VERSION ""

NS_ :

BS_:

BU_:

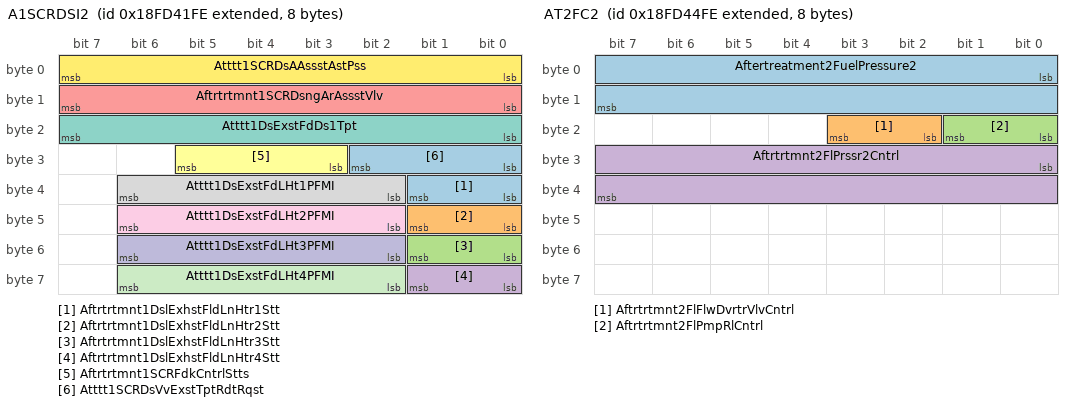
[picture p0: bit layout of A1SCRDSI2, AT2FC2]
BO_ 2566734334 A1SCRDSI2: 8 Vector__XXX
 SG_ Aftrtrtmnt1DslExhstFldLnHtr1Stt : 32|2@1+ (1,0) [0|3] "" Vector__XXX
 SG_ Aftrtrtmnt1DslExhstFldLnHtr2Stt : 40|2@1+ (1,0) [0|3] "" Vector__XXX
 SG_ Aftrtrtmnt1DslExhstFldLnHtr3Stt : 48|2@1+ (1,0) [0|3] "" Vector__XXX
 SG_ Aftrtrtmnt1DslExhstFldLnHtr4Stt : 56|2@1+ (1,0) [0|3] "" Vector__XXX
 SG_ Aftrtrtmnt1SCRDsngArAssstVlv : 8|8@1+ (0.4,0) [0|100] "%" Vector__XXX
 SG_ Aftrtrtmnt1SCRFdkCntrlStts : 27|3@1+ (1,0) [0|7] "" Vector__XXX
 SG_ Atttt1DsExstFdDs1Tpt : 16|8@1+ (1,-40) [-40|210] "degC" Vector__XXX
 SG_ Atttt1DsExstFdLHt1PFMI : 34|5@1+ (1,0) [0|31] "binary" Vector__XXX
 SG_ Atttt1DsExstFdLHt2PFMI : 42|5@1+ (1,0) [0|31] "binary" Vector__XXX
 SG_ Atttt1DsExstFdLHt3PFMI : 50|5@1+ (1,0) [0|31] "binary" Vector__XXX
 SG_ Atttt1DsExstFdLHt4PFMI : 58|5@1+ (1,0) [0|31] "binary" Vector__XXX
 SG_ Atttt1SCRDsAAssstAstPss : 0|8@1+ (8,0) [0|2000] "kPa" Vector__XXX
 SG_ Atttt1SCRDsVvExstTptRdtRqst : 24|3@1+ (1,0) [0|7] "" Vector__XXX

BO_ 2566735102 AT2FC2: 8 Vector__XXX
 SG_ Aftertreatment2FuelPressure2 : 0|16@1+ (0.1,0) [0|6425.5] "kPa" Vector__XXX
 SG_ Aftrtrtmnt2FlFlwDvrtrVlvCntrl : 18|2@1+ (1,0) [0|3] "" Vector__XXX
 SG_ Aftrtrtmnt2FlPmpRlCntrl : 16|2@1+ (1,0) [0|3] "" Vector__XXX
 SG_ Aftrtrtmnt2FlPrssr2Cntrl : 24|16@1+ (0.0025,0) [0|160.6375] "%" Vector__XXX

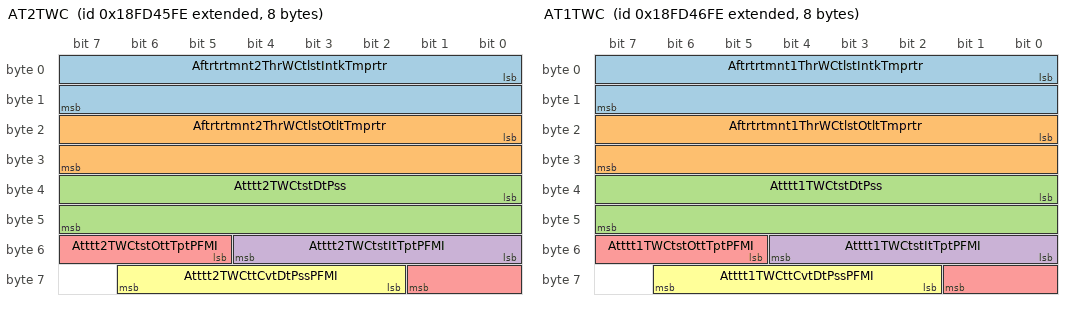
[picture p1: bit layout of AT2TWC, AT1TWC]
BO_ 2566735358 AT2TWC: 8 Vector__XXX
 SG_ Aftrtrtmnt2ThrWCtlstIntkTmprtr : 0|16@1+ (0.03125,-273) [-273|1734.96875] "degC" Vector__XXX
 SG_ Aftrtrtmnt2ThrWCtlstOtltTmprtr : 16|16@1+ (0.03125,-273) [-273|1734.96875] "degC" Vector__XXX
 SG_ Atttt2TWCtstDtPss : 32|16@1+ (0.1,0) [0|6425.5] "kPa" Vector__XXX
 SG_ Atttt2TWCtstItTptPFMI : 48|5@1+ (1,0) [0|31] "binary" Vector__XXX
 SG_ Atttt2TWCtstOttTptPFMI : 53|5@1+ (1,0) [0|31] "binary" Vector__XXX
 SG_ Atttt2TWCttCvtDtPssPFMI : 58|5@1+ (1,0) [0|31] "binary" Vector__XXX

BO_ 2566735614 AT1TWC: 8 Vector__XXX
 SG_ Aftrtrtmnt1ThrWCtlstIntkTmprtr : 0|16@1+ (0.03125,-273) [-273|1734.96875] "degC" Vector__XXX
 SG_ Aftrtrtmnt1ThrWCtlstOtltTmprtr : 16|16@1+ (0.03125,-273) [-273|1734.96875] "degC" Vector__XXX
 SG_ Atttt1TWCtstDtPss : 32|16@1+ (0.1,0) [0|6425.5] "kPa" Vector__XXX
 SG_ Atttt1TWCtstItTptPFMI : 48|5@1+ (1,0) [0|31] "binary" Vector__XXX
 SG_ Atttt1TWCtstOttTptPFMI : 53|5@1+ (1,0) [0|31] "binary" Vector__XXX
 SG_ Atttt1TWCttCvtDtPssPFMI : 58|5@1+ (1,0) [0|31] "binary" Vector__XXX

BO_ 2566736126 O2FT2: 8 Vector__XXX
 SG_ EngnExhstBnk2O2SnsrClsdLpOprtn : 32|4@1+ (1,0) [0|15] "" Vector__XXX
 SG_ LongtermFuelTrimBank2 : 0|16@1+ (0.1,-100) [-100|100] "%" Vector__XXX
 SG_ ShorttermFuelTrimBank2 : 16|16@1+ (0.1,-100) [-100|100] "%" Vector__XXX

BO_ 2566736382 O2FT1: 8 Vector__XXX
 SG_ EngnExhstBnk1O2SnsrClsdLpOprtn : 32|4@1+ (1,0) [0|15] "" Vector__XXX
 SG_ LongtermFuelTrimBank1 : 0|16@1+ (0.1,-100) [-100|100] "%" Vector__XXX
 SG_ ShorttermFuelTrimBank1 : 16|16@1+ (0.1,-100) [-100|100] "%" Vector__XXX

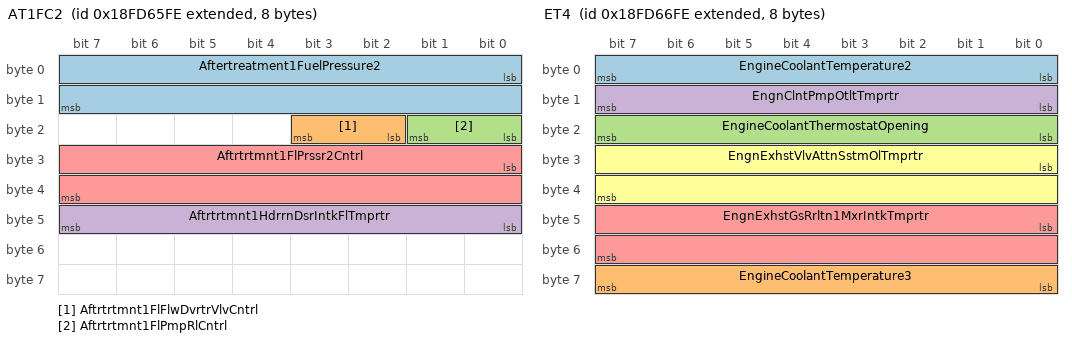
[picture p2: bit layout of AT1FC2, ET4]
BO_ 2566743550 AT1FC2: 8 Vector__XXX
 SG_ Aftertreatment1FuelPressure2 : 0|16@1+ (0.1,0) [0|6425.5] "kPa" Vector__XXX
 SG_ Aftrtrtmnt1FlFlwDvrtrVlvCntrl : 18|2@1+ (1,0) [0|3] "" Vector__XXX
 SG_ Aftrtrtmnt1FlPmpRlCntrl : 16|2@1+ (1,0) [0|3] "" Vector__XXX
 SG_ Aftrtrtmnt1HdrrnDsrIntkFlTmprtr : 40|8@1+ (1,-40) [-40|210] "degC" Vector__XXX
 SG_ Aftrtrtmnt1FlPrssr2Cntrl : 24|16@1+ (0.0025,0) [0|160.6375] "%" Vector__XXX

BO_ 2566743806 ET4: 8 Vector__XXX
 SG_ EngineCoolantTemperature2 : 0|8@1+ (1,-40) [-40|210] "degC" Vector__XXX
 SG_ EngineCoolantTemperature3 : 56|8@1+ (1,-40) [-40|210] "degC" Vector__XXX
 SG_ EngineCoolantThermostatOpening : 16|8@1+ (0.4,0) [0|100] "%" Vector__XXX
 SG_ EngnClntPmpOtltTmprtr : 8|8@1+ (1,-40) [-40|210] "degC" Vector__XXX
 SG_ EngnExhstGsRrltn1MxrIntkTmprtr : 40|16@1+ (0.03125,-273) [-273|1734.96875] "degC" Vector__XXX
 SG_ EngnExhstVlvAttnSstmOlTmprtr : 24|16@1+ (0.03125,-273) [-273|1734.96875] "degC" Vector__XXX

BO_ 2566744062 ZNVW: 8 Vector__XXX
 SG_ ZeroNetVehicleWeightChange : 0|2@1+ (1,0) [0|3] "" Vector__XXX

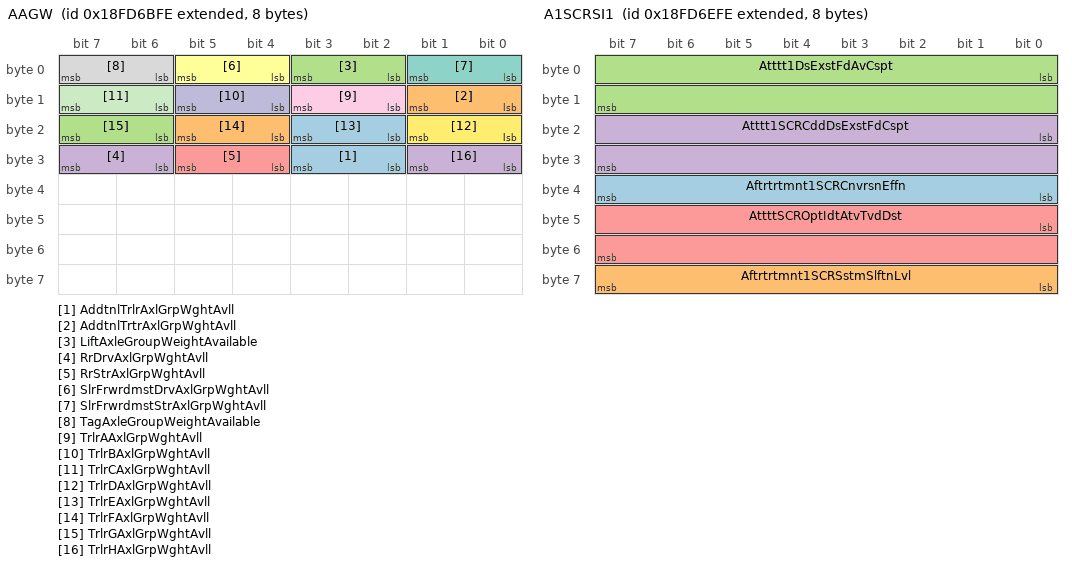
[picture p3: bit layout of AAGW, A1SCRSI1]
BO_ 2566745086 AAGW: 8 Vector__XXX
 SG_ AddtnlTrlrAxlGrpWghtAvll : 26|2@1+ (1,0) [0|3] "" Vector__XXX
 SG_ AddtnlTrtrAxlGrpWghtAvll : 8|2@1+ (1,0) [0|3] "" Vector__XXX
 SG_ LiftAxleGroupWeightAvailable : 2|2@1+ (1,0) [0|3] "" Vector__XXX
 SG_ RrDrvAxlGrpWghtAvll : 30|2@1+ (1,0) [0|3] "" Vector__XXX
 SG_ RrStrAxlGrpWghtAvll : 28|2@1+ (1,0) [0|3] "" Vector__XXX
 SG_ SlrFrwrdmstDrvAxlGrpWghtAvll : 4|2@1+ (1,0) [0|3] "" Vector__XXX
 SG_ SlrFrwrdmstStrAxlGrpWghtAvll : 0|2@1+ (1,0) [0|3] "" Vector__XXX
 SG_ TagAxleGroupWeightAvailable : 6|2@1+ (1,0) [0|3] "" Vector__XXX
 SG_ TrlrAAxlGrpWghtAvll : 10|2@1+ (1,0) [0|3] "" Vector__XXX
 SG_ TrlrBAxlGrpWghtAvll : 12|2@1+ (1,0) [0|3] "" Vector__XXX
 SG_ TrlrCAxlGrpWghtAvll : 14|2@1+ (1,0) [0|3] "" Vector__XXX
 SG_ TrlrDAxlGrpWghtAvll : 16|2@1+ (1,0) [0|3] "" Vector__XXX
 SG_ TrlrEAxlGrpWghtAvll : 18|2@1+ (1,0) [0|3] "" Vector__XXX
 SG_ TrlrFAxlGrpWghtAvll : 20|2@1+ (1,0) [0|3] "" Vector__XXX
 SG_ TrlrGAxlGrpWghtAvll : 22|2@1+ (1,0) [0|3] "" Vector__XXX
 SG_ TrlrHAxlGrpWghtAvll : 24|2@1+ (1,0) [0|3] "" Vector__XXX

BO_ 2566745342 AT2AC2: 8 Vector__XXX
 SG_ Aftrtrtmnt2SndrArDffrntlPrssr : 0|16@1+ (0.0078125,-250) [-250|251.99] "kPa" Vector__XXX
 SG_ Aftrtrtmnt2SndrArMssFlwRt : 32|16@1+ (0.2,0) [0|12851] "kg/h" Vector__XXX
 SG_ Aftrtrtmnt2SndrArPrssr : 48|16@1+ (0.1,0) [0|6425.5] "kPa" Vector__XXX
 SG_ Aftrtrtmnt2SndrArTmprtr : 16|16@1+ (0.03125,-273) [-273|1734.96875] "degC" Vector__XXX

BO_ 2566745598 AT1AC2: 8 Vector__XXX
 SG_ Aftrtrtmnt1SndrArDffrntlPrssr : 0|16@1+ (0.0078125,-250) [-250|251.99] "kPa" Vector__XXX
 SG_ Aftrtrtmnt1SndrArMssFlwRt : 32|16@1+ (0.2,0) [0|12851] "kg/h" Vector__XXX
 SG_ Aftrtrtmnt1SndrArPrssr : 48|16@1+ (0.1,0) [0|6425.5] "kPa" Vector__XXX
 SG_ Aftrtrtmnt1SndrArTmprtr : 16|16@1+ (0.03125,-273) [-273|1734.96875] "degC" Vector__XXX

BO_ 2566745854 A1SCRSI1: 8 Vector__XXX
 SG_ Aftrtrtmnt1SCRCnvrsnEffn : 32|8@1+ (0.4,0) [0|100] "%" Vector__XXX
 SG_ Aftrtrtmnt1SCRSstmSlftnLvl : 56|8@1+ (1,0) [0|250] "%" Vector__XXX
 SG_ Atttt1DsExstFdAvCspt : 0|16@1+ (0.05,0) [0|3212.75] "l/h" Vector__XXX
 SG_ Atttt1SCRCddDsExstFdCspt : 16|16@1+ (0.05,0) [0|3212.75] "l/h" Vector__XXX
 SG_ AttttSCROptIdtAtvTvdDst : 40|16@1+ (1,0) [0|64255] "km" Vector__XXX

BO_ 2566746110 EEC8: 8 Vector__XXX
 SG_ EExstGsRt1CItAstPss : 32|16@1+ (0.5,0) [0|32127.5] "kPa" Vector__XXX
 SG_ EngnExhstGsRrltn1ClrEffn : 48|8@1+ (0.4,0) [0|100] "%" Vector__XXX
 SG_ EngnExhstGsRrltn1ClrIntkTmprtr : 16|16@1+ (0.03125,-273) [-273|1734.96875] "degC" Vector__XXX
 SG_ EngnExhstGsRrltn1Vlv2Cntrl : 0|16@1+ (0.0025,0) [0|160.6375] "%" Vector__XXX

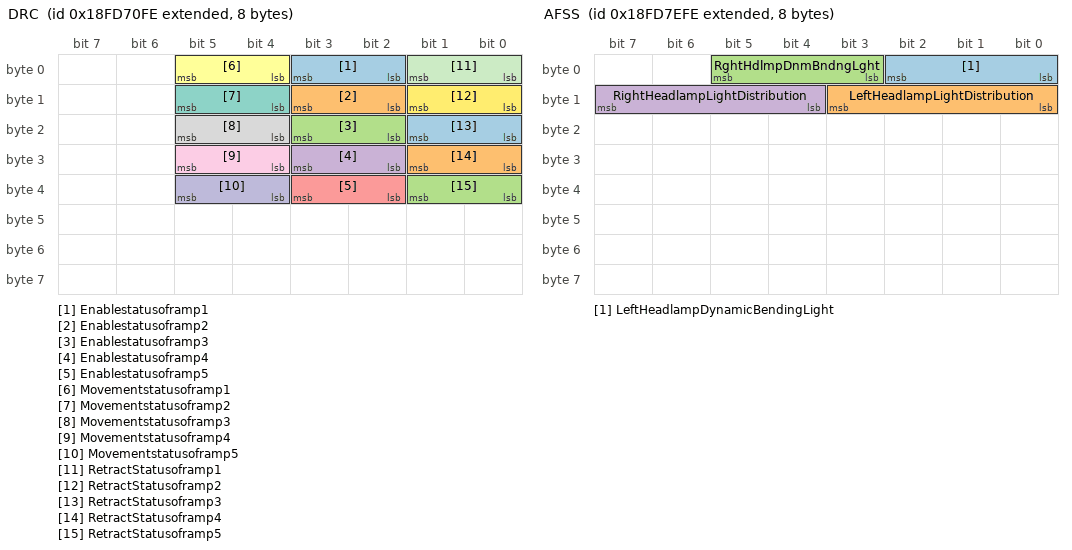
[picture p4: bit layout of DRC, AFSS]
BO_ 2566746366 DRC: 8 Vector__XXX
 SG_ Enablestatusoframp1 : 2|2@1+ (1,0) [0|3] "" Vector__XXX
 SG_ Enablestatusoframp2 : 10|2@1+ (1,0) [0|3] "" Vector__XXX
 SG_ Enablestatusoframp3 : 18|2@1+ (1,0) [0|3] "" Vector__XXX
 SG_ Enablestatusoframp4 : 26|2@1+ (1,0) [0|3] "" Vector__XXX
 SG_ Enablestatusoframp5 : 34|2@1+ (1,0) [0|3] "" Vector__XXX
 SG_ Movementstatusoframp1 : 4|2@1+ (1,0) [0|3] "" Vector__XXX
 SG_ Movementstatusoframp2 : 12|2@1+ (1,0) [0|3] "" Vector__XXX
 SG_ Movementstatusoframp3 : 20|2@1+ (1,0) [0|3] "" Vector__XXX
 SG_ Movementstatusoframp4 : 28|2@1+ (1,0) [0|3] "" Vector__XXX
 SG_ Movementstatusoframp5 : 36|2@1+ (1,0) [0|3] "" Vector__XXX
 SG_ RetractStatusoframp1 : 0|2@1+ (1,0) [0|3] "" Vector__XXX
 SG_ RetractStatusoframp2 : 8|2@1+ (1,0) [0|3] "" Vector__XXX
 SG_ RetractStatusoframp3 : 16|2@1+ (1,0) [0|3] "" Vector__XXX
 SG_ RetractStatusoframp4 : 24|2@1+ (1,0) [0|3] "" Vector__XXX
 SG_ RetractStatusoframp5 : 32|2@1+ (1,0) [0|3] "" Vector__XXX

BO_ 2566746622 BSA: 8 Vector__XXX
 SG_ TractorBrakeStrokeAxle1Left : 0|3@1+ (1,0) [0|7] "" Vector__XXX
 SG_ TractorBrakeStrokeAxle1Right : 3|3@1+ (1,0) [0|7] "" Vector__XXX
 SG_ TractorBrakeStrokeAxle2Left : 6|3@1+ (1,0) [0|7] "" Vector__XXX
 SG_ TractorBrakeStrokeAxle2Right : 9|3@1+ (1,0) [0|7] "" Vector__XXX
 SG_ TractorBrakeStrokeAxle3Left : 12|3@1+ (1,0) [0|7] "" Vector__XXX
 SG_ TractorBrakeStrokeAxle3Right : 15|3@1+ (1,0) [0|7] "" Vector__XXX
 SG_ TractorBrakeStrokeAxle4Left : 18|3@1+ (1,0) [0|7] "" Vector__XXX
 SG_ TractorBrakeStrokeAxle4Right : 21|3@1+ (1,0) [0|7] "" Vector__XXX
 SG_ TractorBrakeStrokeAxle5Left : 24|3@1+ (1,0) [0|7] "" Vector__XXX
 SG_ TractorBrakeStrokeAxle5Right : 27|3@1+ (1,0) [0|7] "" Vector__XXX
 SG_ TrailerBrakeStrokeAxle1Left : 30|3@1+ (1,0) [0|7] "" Vector__XXX
 SG_ TrailerBrakeStrokeAxle1Right : 33|3@1+ (1,0) [0|7] "" Vector__XXX
 SG_ TrailerBrakeStrokeAxle2Left : 36|3@1+ (1,0) [0|7] "" Vector__XXX
 SG_ TrailerBrakeStrokeAxle2Right : 39|3@1+ (1,0) [0|7] "" Vector__XXX
 SG_ TrailerBrakeStrokeAxle3Left : 42|3@1+ (1,0) [0|7] "" Vector__XXX
 SG_ TrailerBrakeStrokeAxle3Right : 45|3@1+ (1,0) [0|7] "" Vector__XXX
 SG_ TrailerBrakeStrokeAxle4Left : 48|3@1+ (1,0) [0|7] "" Vector__XXX
 SG_ TrailerBrakeStrokeAxle4Right : 51|3@1+ (1,0) [0|7] "" Vector__XXX
 SG_ TrailerBrakeStrokeAxle5Left : 54|3@1+ (1,0) [0|7] "" Vector__XXX
 SG_ TrailerBrakeStrokeAxle5Right : 57|3@1+ (1,0) [0|7] "" Vector__XXX

BO_ 2566746878 ESV6: 8 Vector__XXX
 SG_ EngineSparkPlug21 : 0|16@1+ (1,0) [0|64255] "V" Vector__XXX
 SG_ EngineSparkPlug22 : 16|16@1+ (1,0) [0|64255] "V" Vector__XXX
 SG_ EngineSparkPlug23 : 32|16@1+ (1,0) [0|64255] "V" Vector__XXX
 SG_ EngineSparkPlug24 : 48|16@1+ (1,0) [0|64255] "V" Vector__XXX

BO_ 2566747134 ESV5: 8 Vector__XXX
 SG_ EngineSparkPlug17 : 0|16@1+ (1,0) [0|64255] "V" Vector__XXX
 SG_ EngineSparkPlug18 : 16|16@1+ (1,0) [0|64255] "V" Vector__XXX
 SG_ EngineSparkPlug19 : 32|16@1+ (1,0) [0|64255] "V" Vector__XXX
 SG_ EngineSparkPlug20 : 48|16@1+ (1,0) [0|64255] "V" Vector__XXX

BO_ 2566747390 ESV4: 8 Vector__XXX
 SG_ EngineSparkPlug13 : 0|16@1+ (1,0) [0|64255] "V" Vector__XXX
 SG_ EngineSparkPlug14 : 16|16@1+ (1,0) [0|64255] "V" Vector__XXX
 SG_ EngineSparkPlug15 : 32|16@1+ (1,0) [0|64255] "V" Vector__XXX
 SG_ EngineSparkPlug16 : 48|16@1+ (1,0) [0|64255] "V" Vector__XXX

BO_ 2566747646 ESV3: 8 Vector__XXX
 SG_ EngineSparkPlug10 : 16|16@1+ (1,0) [0|64255] "V" Vector__XXX
 SG_ EngineSparkPlug11 : 32|16@1+ (1,0) [0|64255] "V" Vector__XXX
 SG_ EngineSparkPlug12 : 48|16@1+ (1,0) [0|64255] "V" Vector__XXX
 SG_ EngineSparkPlug9 : 0|16@1+ (1,0) [0|64255] "V" Vector__XXX

BO_ 2566747902 ESV2: 8 Vector__XXX
 SG_ EngineSparkPlug5 : 0|16@1+ (1,0) [0|64255] "V" Vector__XXX
 SG_ EngineSparkPlug6 : 16|16@1+ (1,0) [0|64255] "V" Vector__XXX
 SG_ EngineSparkPlug7 : 32|16@1+ (1,0) [0|64255] "V" Vector__XXX
 SG_ EngineSparkPlug8 : 48|16@1+ (1,0) [0|64255] "V" Vector__XXX

BO_ 2566748158 ESV1: 8 Vector__XXX
 SG_ EngineSparkPlug1 : 0|16@1+ (1,0) [0|64255] "V" Vector__XXX
 SG_ EngineSparkPlug2 : 16|16@1+ (1,0) [0|64255] "V" Vector__XXX
 SG_ EngineSparkPlug3 : 32|16@1+ (1,0) [0|64255] "V" Vector__XXX
 SG_ EngineSparkPlug4 : 48|16@1+ (1,0) [0|64255] "V" Vector__XXX

BO_ 2566748414 AT2TI: 32 Vector__XXX
 SG_ Aftrtrtmnt2DslPrtltFltrTrpFlUsd : 0|32@1+ (0.5,0) [0|2105540607.5] "l" Vector__XXX
 SG_ Atttt2DsPttFtTpAtvRtT : 32|32@1+ (1,0) [0|4.21108E+09] "s" Vector__XXX
 SG_ Atttt2DsPttFtTpDsdT : 64|32@1+ (1,0) [0|4.21108E+09] "s" Vector__XXX
 SG_ Atttt2DsPttFtTpNAtvRtItRqsts : 192|32@1+ (1,0) [0|4.21108E+09] "count" Vector__XXX
 SG_ Atttt2DsPttFtTpNAtvRtMRqsts : 224|32@1+ (1,0) [0|4.21108E+09] "count" Vector__XXX
 SG_ Atttt2DsPttFtTpNAtvRts : 96|32@1+ (1,0) [0|4.21108E+09] "count" Vector__XXX
 SG_ Atttt2DsPttFtTpNPssvRts : 160|32@1+ (1,0) [0|4.21108E+09] "count" Vector__XXX
 SG_ Atttt2DsPttFtTpPssvRtT : 128|32@1+ (1,0) [0|4.21108E+09] "s" Vector__XXX

BO_ 2566748670 AT1TI: 32 Vector__XXX
 SG_ Aftrtrtmnt1DslPrtltFltrTrpFlUsd : 0|32@1+ (0.5,0) [0|2105540607.5] "l" Vector__XXX
 SG_ Atttt1DsPttFtTpAtvRtT : 32|32@1+ (1,0) [0|4.21108E+09] "s" Vector__XXX
 SG_ Atttt1DsPttFtTpDsdT : 64|32@1+ (1,0) [0|4.21108E+09] "s" Vector__XXX
 SG_ Atttt1DsPttFtTpNAtvRtItRqsts : 192|32@1+ (1,0) [0|4.21108E+09] "count" Vector__XXX
 SG_ Atttt1DsPttFtTpNAtvRtMRqsts : 224|32@1+ (1,0) [0|4.21108E+09] "count" Vector__XXX
 SG_ Atttt1DsPttFtTpNAtvRts : 96|32@1+ (1,0) [0|4.21108E+09] "count" Vector__XXX
 SG_ Atttt1DsPttFtTpNPssvRts : 160|32@1+ (1,0) [0|4.21108E+09] "count" Vector__XXX
 SG_ Atttt1DsPttFtTpPssvRtT : 128|32@1+ (1,0) [0|4.21108E+09] "s" Vector__XXX

BO_ 2566748926 AT2S1: 8 Vector__XXX
 SG_ Aftrtrtmnt2DslPrtltFltrStLdPrnt : 0|8@1+ (1,0) [0|250] "%" Vector__XXX
 SG_ Atttt2DsPttFtAsLdPt : 8|8@1+ (1,0) [0|250] "%" Vector__XXX
 SG_ Atttt2DsPttFtStLdRtTsd : 48|16@1+ (0.0025,0) [0|160.6375] "%" Vector__XXX
 SG_ Atttt2DsPttFtTSLstAtvRt : 16|32@1+ (1,0) [0|4.21108E+09] "s" Vector__XXX

BO_ 2566749182 AT1S1: 8 Vector__XXX
 SG_ Aftrtrtmnt1DslPrtltFltrStLdPrnt : 0|8@1+ (1,0) [0|250] "%" Vector__XXX
 SG_ Atttt1DsPttFtAsLdPt : 8|8@1+ (1,0) [0|250] "%" Vector__XXX
 SG_ Atttt1DsPttFtStLdRtTsd : 48|16@1+ (0.0025,0) [0|160.6375] "%" Vector__XXX
 SG_ Atttt1DsPttFtTSLstAtvRt : 16|32@1+ (1,0) [0|4.21108E+09] "s" Vector__XXX

BO_ 2566749438 DPFC1: 8 Vector__XXX
 SG_ AftrtrtmntDslPrtltFltrStts : 12|3@1+ (1,0) [0|7] "" Vector__XXX
 SG_ Atttt1DsPttFtCdtsNtMtAtvRt : 60|2@1+ (1,0) [0|3] "" Vector__XXX
 SG_ AttttDsPttFtAtvRtStts : 10|2@1+ (1,0) [0|3] "" Vector__XXX
 SG_ AttttDsPttFtPssvRtStts : 8|2@1+ (1,0) [0|3] "" Vector__XXX
 SG_ DslPrtltFltrAtvRgnrtnAvlltStts : 3|2@1+ (1,0) [0|3] "" Vector__XXX
 SG_ DslPrtltFltrAtvRgnrtnFrdStts : 53|3@1+ (1,0) [0|7] "" Vector__XXX
 SG_ DslPrtltFltrAtvRgnrtnInhtdStts : 16|2@1+ (1,0) [0|3] "" Vector__XXX
 SG_ DslPrtltFltrLmpCmmnd : 0|3@1+ (1,0) [0|7] "" Vector__XXX
 SG_ DsPttFtAttAtvRtIttCt : 48|2@1+ (1,0) [0|3] "" Vector__XXX
 SG_ DsPttFtAtvRtItdDtAtPdOId : 26|2@1+ (1,0) [0|3] "" Vector__XXX
 SG_ DsPttFtAtvRtItdDtCtDsd : 20|2@1+ (1,0) [0|3] "" Vector__XXX
 SG_ DsPttFtAtvRtItdDtENtWdUp : 44|2@1+ (1,0) [0|3] "" Vector__XXX
 SG_ DsPttFtAtvRtItdDtItSwt : 18|2@1+ (1,0) [0|3] "" Vector__XXX
 SG_ DsPttFtAtvRtItdDtLwExstPss : 58|2@1+ (1,0) [0|3] "" Vector__XXX
 SG_ DsPttFtAtvRtItdDtLwExstTpt : 34|2@1+ (1,0) [0|3] "" Vector__XXX
 SG_ DsPttFtAtvRtItdDtOtNt : 28|2@1+ (1,0) [0|3] "" Vector__XXX
 SG_ DsPttFtAtvRtItdDtPBNtSt : 32|2@1+ (1,0) [0|3] "" Vector__XXX
 SG_ DsPttFtAtvRtItdDtPTOAtv : 24|2@1+ (1,0) [0|3] "" Vector__XXX
 SG_ DsPttFtAtvRtItdDtPtSstLt : 42|2@1+ (1,0) [0|3] "" Vector__XXX
 SG_ DsPttFtAtvRtItdDtSstFtAtv : 36|2@1+ (1,0) [0|3] "" Vector__XXX
 SG_ DsPttFtAtvRtItdDtSstTt : 38|2@1+ (1,0) [0|3] "" Vector__XXX
 SG_ DsPttFtAtvRtItdDtSvBAtv : 22|2@1+ (1,0) [0|3] "" Vector__XXX
 SG_ DsPttFtAtvRtItdDtTpSstLt : 40|2@1+ (1,0) [0|3] "" Vector__XXX
 SG_ DsPttFtAtvRtItdDtVSpdAvAwdSpd : 30|2@1+ (1,0) [0|3] "" Vector__XXX
 SG_ DsPttFtAtvRtItdDtVSpdBwAwdSpd : 46|2@1+ (1,0) [0|3] "" Vector__XXX
 SG_ ExhstSstmHghTmprtrLmpCmmnd : 50|3@1+ (1,0) [0|7] "" Vector__XXX
 SG_ HydrocarbonDoserPurgingEnable : 56|2@1+ (1,0) [0|3] "" Vector__XXX
 SG_ DsPttFtAtvRtItdDtTs : 62|2@1+ (1,0) [0|3] "" Vector__XXX

BO_ 2566749950 AFSS: 8 Vector__XXX
 SG_ LeftHeadlampDynamicBendingLight : 0|3@1+ (1,0) [0|7] "" Vector__XXX
 SG_ LeftHeadlampLightDistribution : 8|4@1+ (1,0) [0|15] "" Vector__XXX
 SG_ RghtHdlmpDnmBndngLght : 3|3@1+ (1,0) [0|7] "" Vector__XXX
 SG_ RightHeadlampLightDistribution : 12|4@1+ (1,0) [0|15] "" Vector__XXX

BO_ 2566750206 EC2: 8 Vector__XXX
 SG_ EngnCnfgrtnIdntftn : 16|16@1+ (1,0) [0|64255] "ID" Vector__XXX
 SG_ MxmmCrnkAttmptsprStrtAttmpt : 0|8@1+ (1,0) [0|250] "count" Vector__XXX
 SG_ NmrfCmstnClsfrAvrgng : 8|8@1+ (1,0) [0|250] "count" Vector__XXX
 SG_ TrnsmssnIdlGvrnrFlngInhtSpprt : 32|2@1+ (1,0) [0|3] "" Vector__XXX

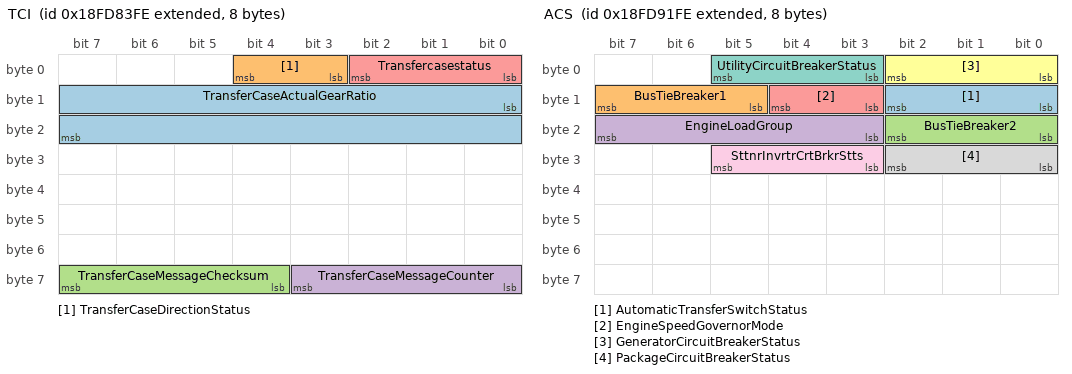
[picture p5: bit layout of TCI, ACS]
BO_ 2566751230 TCI: 8 Vector__XXX
 SG_ TransferCaseActualGearRatio : 8|16@1+ (0.01,0) [0|642.55] "" Vector__XXX
 SG_ TransferCaseDirectionStatus : 3|2@1+ (1,0) [0|3] "" Vector__XXX
 SG_ TransferCaseMessageChecksum : 60|4@1+ (1,0) [0|15] "count" Vector__XXX
 SG_ TransferCaseMessageCounter : 56|4@1+ (1,0) [0|15] "count" Vector__XXX
 SG_ Transfercasestatus : 0|3@1+ (1,0) [0|7] "" Vector__XXX

BO_ 2566751486 EFLP9: 8 Vector__XXX
 SG_ EngnIntkVlvAttnOlPrssrfrClndr17 : 0|16@1+ (0.1,0) [0|6425.5] "kPa" Vector__XXX
 SG_ EngnIntkVlvAttnOlPrssrfrClndr18 : 16|16@1+ (0.1,0) [0|6425.5] "kPa" Vector__XXX
 SG_ EngnIntkVlvAttnOlPrssrfrClndr19 : 32|16@1+ (0.1,0) [0|6425.5] "kPa" Vector__XXX
 SG_ EngnIntkVlvAttnOlPrssrfrClndr20 : 48|16@1+ (0.1,0) [0|6425.5] "kPa" Vector__XXX

BO_ 2566751742 EFLP8: 8 Vector__XXX
 SG_ EngnIntkVlvAttnOlPrssrfrClndr13 : 0|16@1+ (0.1,0) [0|6425.5] "kPa" Vector__XXX
 SG_ EngnIntkVlvAttnOlPrssrfrClndr14 : 16|16@1+ (0.1,0) [0|6425.5] "kPa" Vector__XXX
 SG_ EngnIntkVlvAttnOlPrssrfrClndr15 : 32|16@1+ (0.1,0) [0|6425.5] "kPa" Vector__XXX
 SG_ EngnIntkVlvAttnOlPrssrfrClndr16 : 48|16@1+ (0.1,0) [0|6425.5] "kPa" Vector__XXX

BO_ 2566751998 EFLP7: 8 Vector__XXX
 SG_ EngnIntkVlvAttnOlPrssrfrClndr10 : 16|16@1+ (0.1,0) [0|6425.5] "kPa" Vector__XXX
 SG_ EngnIntkVlvAttnOlPrssrfrClndr11 : 32|16@1+ (0.1,0) [0|6425.5] "kPa" Vector__XXX
 SG_ EngnIntkVlvAttnOlPrssrfrClndr12 : 48|16@1+ (0.1,0) [0|6425.5] "kPa" Vector__XXX
 SG_ EngnIntkVlvAttnOlPrssrfrClndr9 : 0|16@1+ (0.1,0) [0|6425.5] "kPa" Vector__XXX

BO_ 2566752254 EFLP6: 8 Vector__XXX
 SG_ EngnIntkVlvAttnOlPrssrfrClndr5 : 0|16@1+ (0.1,0) [0|6425.5] "kPa" Vector__XXX
 SG_ EngnIntkVlvAttnOlPrssrfrClndr6 : 16|16@1+ (0.1,0) [0|6425.5] "kPa" Vector__XXX
 SG_ EngnIntkVlvAttnOlPrssrfrClndr7 : 32|16@1+ (0.1,0) [0|6425.5] "kPa" Vector__XXX
 SG_ EngnIntkVlvAttnOlPrssrfrClndr8 : 48|16@1+ (0.1,0) [0|6425.5] "kPa" Vector__XXX

BO_ 2566752510 EFLP5: 8 Vector__XXX
 SG_ EngnIntkVlvAttnOlPrssrfrClndr1 : 0|16@1+ (0.1,0) [0|6425.5] "kPa" Vector__XXX
 SG_ EngnIntkVlvAttnOlPrssrfrClndr2 : 16|16@1+ (0.1,0) [0|6425.5] "kPa" Vector__XXX
 SG_ EngnIntkVlvAttnOlPrssrfrClndr3 : 32|16@1+ (0.1,0) [0|6425.5] "kPa" Vector__XXX
 SG_ EngnIntkVlvAttnOlPrssrfrClndr4 : 48|16@1+ (0.1,0) [0|6425.5] "kPa" Vector__XXX

BO_ 2566752766 VDS2: 8 Vector__XXX
 SG_ VehicleRoll : 0|16@1+ (0.0078125,-200) [-200|301.99] "deg" Vector__XXX

BO_ 2566753278 AT2GP: 8 Vector__XXX
 SG_ Atttt2DsPttFtItPss : 0|16@1+ (0.1,0) [0|6425.5] "kPa" Vector__XXX
 SG_ Atttt2DsPttFtOttPss : 16|16@1+ (0.1,0) [0|6425.5] "kPa" Vector__XXX

BO_ 2566753534 AT1GP: 8 Vector__XXX
 SG_ Atttt1DsPttFtItPss : 0|16@1+ (0.1,0) [0|6425.5] "kPa" Vector__XXX
 SG_ Atttt1DsPttFtOttPss : 16|16@1+ (0.1,0) [0|6425.5] "kPa" Vector__XXX

BO_ 2566753790 UTACER: 8 Vector__XXX
 SG_ UtilityTotalkVArHoursExport : 0|32@1+ (1,0) [0|4.21108E+09] "kVArh" Vector__XXX
 SG_ UtilityTotalkVArHoursImport : 32|32@1+ (1,0) [0|4.21108E+09] "kVArh" Vector__XXX

BO_ 2566754046 GTACER: 8 Vector__XXX
 SG_ GeneratorTotalkVArHoursExport : 0|32@1+ (1,0) [0|4.21108E+09] "kVArh" Vector__XXX
 SG_ GeneratorTotalkVArHoursImport : 32|32@1+ (1,0) [0|4.21108E+09] "kVArh" Vector__XXX

BO_ 2566754302 GTACPP: 8 Vector__XXX
 SG_ GeneratorTotalPercentkVA : 16|16@1+ (0.0078125,-251) [-251|250.99] "%" Vector__XXX
 SG_ GeneratorTotalPercentkVAr : 32|16@1+ (0.0078125,-251) [-251|250.99] "%" Vector__XXX
 SG_ GeneratorTotalPercentkW : 0|16@1+ (0.0078125,-251) [-251|250.99] "%" Vector__XXX

BO_ 2566754814 ACS: 8 Vector__XXX
 SG_ AutomaticTransferSwitchStatus : 8|3@1+ (1,0) [0|7] "" Vector__XXX
 SG_ BusTieBreaker1 : 13|3@1+ (1,0) [0|7] "" Vector__XXX
 SG_ BusTieBreaker2 : 16|3@1+ (1,0) [0|7] "" Vector__XXX
 SG_ EngineLoadGroup : 19|5@1+ (1,0) [0|31] "count" Vector__XXX
 SG_ EngineSpeedGovernorMode : 11|2@1+ (1,0) [0|3] "" Vector__XXX
 SG_ GeneratorCircuitBreakerStatus : 0|3@1+ (1,0) [0|7] "" Vector__XXX
 SG_ UtilityCircuitBreakerStatus : 3|3@1+ (1,0) [0|7] "" Vector__XXX
 SG_ PackageCircuitBreakerStatus : 24|3@1+ (1,0) [0|7] "" Vector__XXX
 SG_ SttnrInvrtrCrtBrkrStts : 27|3@1+ (1,0) [0|7] "" Vector__XXX

BO_ 2566755582 EEC7: 8 Vector__XXX
 SG_ EngnCrnksBrthrOlSprtrSpd : 32|16@1+ (1,0) [0|64255] "rpm" Vector__XXX
 SG_ EngnExhstGsRrltn1Vlv2Pstn : 16|16@1+ (0.0025,0) [0|160.6375] "%" Vector__XXX
 SG_ EngnExhstGsRrltn1VlvPstn : 0|16@1+ (0.0025,0) [0|160.6375] "%" Vector__XXX
 SG_ EngnIntkMnfldCmmnddPrssr : 48|16@1+ (0.125,0) [0|8031.875] "kPa" Vector__XXX

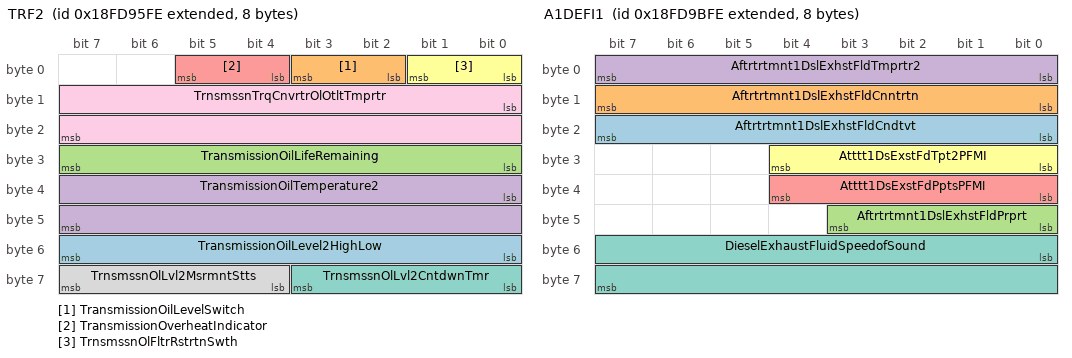
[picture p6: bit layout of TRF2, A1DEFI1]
BO_ 2566755838 TRF2: 8 Vector__XXX
 SG_ TransmissionOilLevel2HighLow : 48|8@1+ (0.5,-62.5) [-62.5|62.5] "l" Vector__XXX
 SG_ TransmissionOilLevelSwitch : 2|2@1+ (1,0) [0|3] "" Vector__XXX
 SG_ TransmissionOilLifeRemaining : 24|8@1+ (0.4,0) [0|100] "%" Vector__XXX
 SG_ TransmissionOilTemperature2 : 32|16@1+ (0.03125,-273) [-273|1734.96875] "degC" Vector__XXX
 SG_ TransmissionOverheatIndicator : 4|2@1+ (1,0) [0|3] "" Vector__XXX
 SG_ TrnsmssnOlFltrRstrtnSwth : 0|2@1+ (1,0) [0|3] "" Vector__XXX
 SG_ TrnsmssnOlLvl2CntdwnTmr : 56|4@1+ (1,0) [0|15] "" Vector__XXX
 SG_ TrnsmssnOlLvl2MsrmntStts : 60|4@1+ (1,0) [0|15] "" Vector__XXX
 SG_ TrnsmssnTrqCnvrtrOlOtltTmprtr : 8|16@1+ (0.03125,-273) [-273|1734.96875] "degC" Vector__XXX

BO_ 2566756094 LFI2: 8 Vector__XXX
 SG_ EngineFuelReturnFlowRate : 32|32@1+ (0.001,0) [0|4211081.215] "l/h" Vector__XXX
 SG_ EngineFuelSupplyFlowRate : 0|32@1+ (0.001,0) [0|4211081.215] "l/h" Vector__XXX

BO_ 2566756350 LFI3: 8 Vector__XXX
 SG_ EngineFuelReturnTemperature : 8|8@1+ (1,-40) [-40|210] "degC" Vector__XXX
 SG_ EngineFuelSupplyTemperature : 0|8@1+ (1,-40) [-40|210] "degC" Vector__XXX

BO_ 2566756606 AT1HI1: 40 Vector__XXX
 SG_ Aftertreatment1TotalFuelUsed : 0|32@1+ (0.5,0) [0|2105540607.5] "l" Vector__XXX
 SG_ Aftrtrtmnt1TtlDsldTm : 64|32@1+ (1,0) [0|4.21108E+09] "s" Vector__XXX
 SG_ Aftrtrtmnt1TtlNmrfAtvRgnrtns : 96|32@1+ (1,0) [0|4.21108E+09] "count" Vector__XXX
 SG_ Aftrtrtmnt1TtlRgnrtnTm : 32|32@1+ (1,0) [0|4.21108E+09] "s" Vector__XXX
 SG_ Atttt1DsPttFtAvDstBtwAtvRts : 288|32@1+ (0.125,0) [0|526385151.875] "km" Vector__XXX
 SG_ Atttt1DsPttFtAvTBtwAtvRts : 256|32@1+ (1,0) [0|4.21108E+09] "s" Vector__XXX
 SG_ Atttt1DsPttFtTtNAtvRtItRqsts : 192|32@1+ (1,0) [0|4.21108E+09] "count" Vector__XXX
 SG_ Atttt1DsPttFtTtNAtvRtMRqsts : 224|32@1+ (1,0) [0|4.21108E+09] "count" Vector__XXX
 SG_ Atttt1DsPttFtTtNPssvRts : 160|32@1+ (1,0) [0|4.21108E+09] "count" Vector__XXX
 SG_ Atttt1DsPttFtTtPssvRtT : 128|32@1+ (1,0) [0|4.21108E+09] "s" Vector__XXX

BO_ 2566756862 AT2HI1: 40 Vector__XXX
 SG_ Aftertreatment2TotalFuelUsed : 0|32@1+ (0.5,0) [0|2105540607.5] "l" Vector__XXX
 SG_ Aftrtrtmnt2TtlDsldTm : 64|32@1+ (1,0) [0|4.21108E+09] "s" Vector__XXX
 SG_ Aftrtrtmnt2TtlNmrfAtvRgnrtns : 96|32@1+ (1,0) [0|4.21108E+09] "count" Vector__XXX
 SG_ Aftrtrtmnt2TtlRgnrtnTm : 32|32@1+ (1,0) [0|4.21108E+09] "s" Vector__XXX
 SG_ Atttt2DsPttFtAvDstBtwAtvRts : 288|32@1+ (0.125,0) [0|526385151.875] "km" Vector__XXX
 SG_ Atttt2DsPttFtAvTBtwAtvRts : 256|32@1+ (1,0) [0|4.21108E+09] "s" Vector__XXX
 SG_ Atttt2DsPttFtTtNAtvRtItRqsts : 192|32@1+ (1,0) [0|4.21108E+09] "count" Vector__XXX
 SG_ Atttt2DsPttFtTtNAtvRtMRqsts : 224|32@1+ (1,0) [0|4.21108E+09] "count" Vector__XXX
 SG_ Atttt2DsPttFtTtNPssvRts : 160|32@1+ (1,0) [0|4.21108E+09] "count" Vector__XXX
 SG_ Atttt2DsPttFtTtPssvRtT : 128|32@1+ (1,0) [0|4.21108E+09] "s" Vector__XXX

BO_ 2566757374 A1DEFI1: 8 Vector__XXX
 SG_ Aftrtrtmnt1DslExhstFldCndtvt : 16|8@1+ (5,0) [0|1250] "µSiemens/mm" Vector__XXX
 SG_ Aftrtrtmnt1DslExhstFldCnntrtn : 8|8@1+ (0.25,0) [0|62.5] "%" Vector__XXX
 SG_ Aftrtrtmnt1DslExhstFldPrprt : 40|4@1+ (1,0) [0|15] "" Vector__XXX
 SG_ Aftrtrtmnt1DslExhstFldTmprtr2 : 0|8@1+ (1,-40) [-40|210] "degC" Vector__XXX
 SG_ Atttt1DsExstFdPptsPFMI : 32|5@1+ (1,0) [0|31] "binary" Vector__XXX
 SG_ Atttt1DsExstFdTpt2PFMI : 24|5@1+ (1,0) [0|31] "binary" Vector__XXX
 SG_ DieselExhaustFluidSpeedofSound : 48|16@1+ (0.1,0) [0|6425.5] "m/s" Vector__XXX

BO_ 2566757630 SEP2: 8 Vector__XXX
 SG_ Sensorsupplyvoltage5 : 0|16@1+ (0.05,0) [0|3212.75] "V" Vector__XXX
 SG_ Sensorsupplyvoltage6 : 16|16@1+ (0.05,0) [0|3212.75] "V" Vector__XXX
 SG_ Sensorsupplyvoltage7 : 32|16@1+ (0.05,0) [0|3212.75] "V" Vector__XXX
 SG_ Sensorsupplyvoltage8 : 48|16@1+ (0.05,0) [0|3212.75] "V" Vector__XXX

BO_ 2566757886 SEP1: 8 Vector__XXX
 SG_ Sensorsupplyvoltage1 : 0|16@1+ (0.05,0) [0|3212.75] "V" Vector__XXX
 SG_ Sensorsupplyvoltage2 : 16|16@1+ (0.05,0) [0|3212.75] "V" Vector__XXX
 SG_ Sensorsupplyvoltage3 : 32|16@1+ (0.05,0) [0|3212.75] "V" Vector__XXX
 SG_ Sensorsupplyvoltage4 : 48|16@1+ (0.05,0) [0|3212.75] "V" Vector__XXX

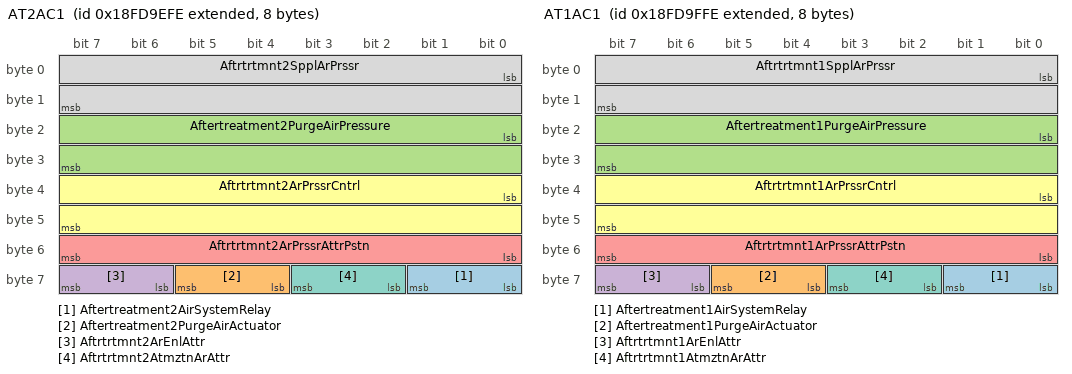
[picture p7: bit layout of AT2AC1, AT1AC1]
BO_ 2566758142 AT2AC1: 8 Vector__XXX
 SG_ Aftertreatment2AirSystemRelay : 56|2@1+ (1,0) [0|3] "" Vector__XXX
 SG_ Aftertreatment2PurgeAirActuator : 60|2@1+ (1,0) [0|3] "" Vector__XXX
 SG_ Aftertreatment2PurgeAirPressure : 16|16@1+ (0.1,0) [0|6425.5] "kPa" Vector__XXX
 SG_ Aftrtrtmnt2ArEnlAttr : 62|2@1+ (1,0) [0|3] "" Vector__XXX
 SG_ Aftrtrtmnt2ArPrssrAttrPstn : 48|8@1+ (0.4,0) [0|100] "%" Vector__XXX
 SG_ Aftrtrtmnt2ArPrssrCntrl : 32|16@1+ (0.0025,0) [0|160.6375] "%" Vector__XXX
 SG_ Aftrtrtmnt2AtmztnArAttr : 58|2@1+ (1,0) [0|3] "" Vector__XXX
 SG_ Aftrtrtmnt2SpplArPrssr : 0|16@1+ (0.1,0) [0|6425.5] "kPa" Vector__XXX

BO_ 2566758398 AT1AC1: 8 Vector__XXX
 SG_ Aftertreatment1AirSystemRelay : 56|2@1+ (1,0) [0|3] "" Vector__XXX
 SG_ Aftertreatment1PurgeAirActuator : 60|2@1+ (1,0) [0|3] "" Vector__XXX
 SG_ Aftertreatment1PurgeAirPressure : 16|16@1+ (0.1,0) [0|6425.5] "kPa" Vector__XXX
 SG_ Aftrtrtmnt1ArEnlAttr : 62|2@1+ (1,0) [0|3] "" Vector__XXX
 SG_ Aftrtrtmnt1ArPrssrAttrPstn : 48|8@1+ (0.4,0) [0|100] "%" Vector__XXX
 SG_ Aftrtrtmnt1ArPrssrCntrl : 32|16@1+ (0.0025,0) [0|160.6375] "%" Vector__XXX
 SG_ Aftrtrtmnt1AtmztnArAttr : 58|2@1+ (1,0) [0|3] "" Vector__XXX
 SG_ Aftrtrtmnt1SpplArPrssr : 0|16@1+ (0.1,0) [0|6425.5] "kPa" Vector__XXX

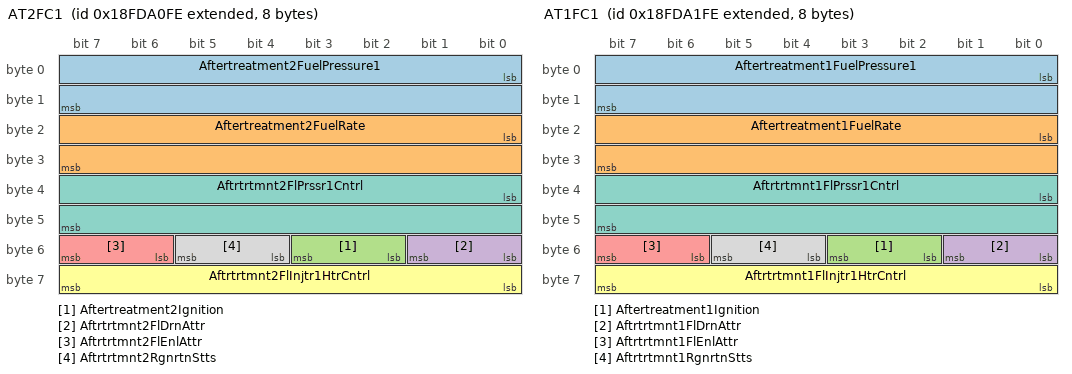
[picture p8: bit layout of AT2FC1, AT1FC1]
BO_ 2566758654 AT2FC1: 8 Vector__XXX
 SG_ Aftertreatment2FuelPressure1 : 0|16@1+ (0.1,0) [0|6425.5] "kPa" Vector__XXX
 SG_ Aftertreatment2FuelRate : 16|16@1+ (0.05,0) [0|3212.75] "l/h" Vector__XXX
 SG_ Aftertreatment2Ignition : 50|2@1+ (1,0) [0|3] "" Vector__XXX
 SG_ Aftrtrtmnt2FlDrnAttr : 48|2@1+ (1,0) [0|3] "" Vector__XXX
 SG_ Aftrtrtmnt2FlEnlAttr : 54|2@1+ (1,0) [0|3] "" Vector__XXX
 SG_ Aftrtrtmnt2FlInjtr1HtrCntrl : 56|8@1+ (0.4,0) [0|100] "%" Vector__XXX
 SG_ Aftrtrtmnt2FlPrssr1Cntrl : 32|16@1+ (0.0025,0) [0|160.6375] "%" Vector__XXX
 SG_ Aftrtrtmnt2RgnrtnStts : 52|2@1+ (1,0) [0|3] "" Vector__XXX

BO_ 2566758910 AT1FC1: 8 Vector__XXX
 SG_ Aftertreatment1FuelPressure1 : 0|16@1+ (0.1,0) [0|6425.5] "kPa" Vector__XXX
 SG_ Aftertreatment1FuelRate : 16|16@1+ (0.05,0) [0|3212.75] "l/h" Vector__XXX
 SG_ Aftertreatment1Ignition : 50|2@1+ (1,0) [0|3] "" Vector__XXX
 SG_ Aftrtrtmnt1FlDrnAttr : 48|2@1+ (1,0) [0|3] "" Vector__XXX
 SG_ Aftrtrtmnt1FlEnlAttr : 54|2@1+ (1,0) [0|3] "" Vector__XXX
 SG_ Aftrtrtmnt1FlInjtr1HtrCntrl : 56|8@1+ (0.4,0) [0|100] "%" Vector__XXX
 SG_ Aftrtrtmnt1FlPrssr1Cntrl : 32|16@1+ (0.0025,0) [0|160.6375] "%" Vector__XXX
 SG_ Aftrtrtmnt1RgnrtnStts : 52|2@1+ (1,0) [0|3] "" Vector__XXX

BO_ 2566759678 PTODE: 8 Vector__XXX
 SG_ AtleastonePTOengaged : 48|2@1+ (1,0) [0|3] "" Vector__XXX
 SG_ EnableSwitchPTOEngineFlywheel : 8|2@1+ (1,0) [0|3] "" Vector__XXX
 SG_ EnggmntCnsntPTOEngnAssrDrv1 : 26|2@1+ (1,0) [0|3] "" Vector__XXX
 SG_ EnggmntCnsntPTOEngnAssrDrv2 : 28|2@1+ (1,0) [0|3] "" Vector__XXX
 SG_ EnggmntCnsntPTOEngnFlwhl : 24|2@1+ (1,0) [0|3] "" Vector__XXX
 SG_ EnggmntSttsPTOEngnAssrDrv1 : 42|2@1+ (1,0) [0|3] "" Vector__XXX
 SG_ EnggmntSttsPTOEngnAssrDrv2 : 44|2@1+ (1,0) [0|3] "" Vector__XXX
 SG_ EnggmntSttsPTOEngnFlwhl : 40|2@1+ (1,0) [0|3] "" Vector__XXX
 SG_ EnlSwthPTOEngnAssrDrv1 : 10|2@1+ (1,0) [0|3] "" Vector__XXX
 SG_ EnlSwthPTOEngnAssrDrv2 : 12|2@1+ (1,0) [0|3] "" Vector__XXX
 SG_ EnlSwthTrnsfrstptshftPTO : 0|2@1+ (1,0) [0|3] "" Vector__XXX
 SG_ EnlSwthTrnsmssntptshftPTO : 2|2@1+ (1,0) [0|3] "" Vector__XXX
 SG_ EnlSwthTrnsmssnnptshftPTO2 : 4|2@1+ (1,0) [0|3] "" Vector__XXX
 SG_ EnlSwthTrnsmssnnptshftPTO1 : 6|2@1+ (1,0) [0|3] "" Vector__XXX
 SG_ EnggmntCnsntTrnsfrstptshftPTO : 16|2@1+ (1,0) [0|3] "" Vector__XXX
 SG_ EnggmntCnsntTrnsmssntptshftPTO : 18|2@1+ (1,0) [0|3] "" Vector__XXX
 SG_ EnggmntCnsntTrnsmssnnptshftPTO2 : 20|2@1+ (1,0) [0|3] "" Vector__XXX
 SG_ EnggmntCnsntTrnsmssnnptshftPTO1 : 22|2@1+ (1,0) [0|3] "" Vector__XXX
 SG_ EnggmntSttsTrnsfrstptshftPTO : 32|2@1+ (1,0) [0|3] "" Vector__XXX
 SG_ EnggmntSttsTrnsmssntptshftPTO : 34|2@1+ (1,0) [0|3] "" Vector__XXX
 SG_ EnggmntSttsTrnsmssnnptshftPTO2 : 36|2@1+ (1,0) [0|3] "" Vector__XXX
 SG_ EnggmntSttsTrnsmssnnptshftPTO1 : 38|2@1+ (1,0) [0|3] "" Vector__XXX

BO_ 2566759934 DC2: 8 Vector__XXX
 SG_ EnableStatusofDoor1 : 4|2@1+ (1,0) [0|3] "" Vector__XXX
 SG_ EnableStatusofDoor10 : 58|2@1+ (1,0) [0|3] "" Vector__XXX
 SG_ EnableStatusofDoor2 : 10|2@1+ (1,0) [0|3] "" Vector__XXX
 SG_ EnableStatusofDoor3 : 16|2@1+ (1,0) [0|3] "" Vector__XXX
 SG_ EnableStatusofDoor4 : 22|2@1+ (1,0) [0|3] "" Vector__XXX
 SG_ EnableStatusofDoor5 : 28|2@1+ (1,0) [0|3] "" Vector__XXX
 SG_ EnableStatusofDoor6 : 34|2@1+ (1,0) [0|3] "" Vector__XXX
 SG_ EnableStatusofDoor7 : 40|2@1+ (1,0) [0|3] "" Vector__XXX
 SG_ EnableStatusofDoor8 : 46|2@1+ (1,0) [0|3] "" Vector__XXX
 SG_ EnableStatusofDoor9 : 52|2@1+ (1,0) [0|3] "" Vector__XXX
 SG_ LockStatusofDoor1 : 0|2@1+ (1,0) [0|3] "" Vector__XXX
 SG_ LockStatusofDoor10 : 54|2@1+ (1,0) [0|3] "" Vector__XXX
 SG_ LockStatusofDoor2 : 6|2@1+ (1,0) [0|3] "" Vector__XXX
 SG_ LockStatusofDoor3 : 12|2@1+ (1,0) [0|3] "" Vector__XXX
 SG_ LockStatusofDoor4 : 18|2@1+ (1,0) [0|3] "" Vector__XXX
 SG_ LockStatusofDoor5 : 24|2@1+ (1,0) [0|3] "" Vector__XXX
 SG_ LockStatusofDoor6 : 30|2@1+ (1,0) [0|3] "" Vector__XXX
 SG_ LockStatusofDoor7 : 36|2@1+ (1,0) [0|3] "" Vector__XXX
 SG_ LockStatusofDoor8 : 42|2@1+ (1,0) [0|3] "" Vector__XXX
 SG_ LockStatusofDoor9 : 48|2@1+ (1,0) [0|3] "" Vector__XXX
 SG_ OpenStatusofDoor1 : 2|2@1+ (1,0) [0|3] "" Vector__XXX
 SG_ OpenStatusofDoor10 : 56|2@1+ (1,0) [0|3] "" Vector__XXX
 SG_ OpenStatusofDoor2 : 8|2@1+ (1,0) [0|3] "" Vector__XXX
 SG_ OpenStatusofDoor3 : 14|2@1+ (1,0) [0|3] "" Vector__XXX
 SG_ OpenStatusofDoor4 : 20|2@1+ (1,0) [0|3] "" Vector__XXX
 SG_ OpenStatusofDoor5 : 26|2@1+ (1,0) [0|3] "" Vector__XXX
 SG_ OpenStatusofDoor6 : 32|2@1+ (1,0) [0|3] "" Vector__XXX
 SG_ OpenStatusofDoor7 : 38|2@1+ (1,0) [0|3] "" Vector__XXX
 SG_ OpenStatusofDoor8 : 44|2@1+ (1,0) [0|3] "" Vector__XXX
 SG_ OpenStatusofDoor9 : 50|2@1+ (1,0) [0|3] "" Vector__XXX

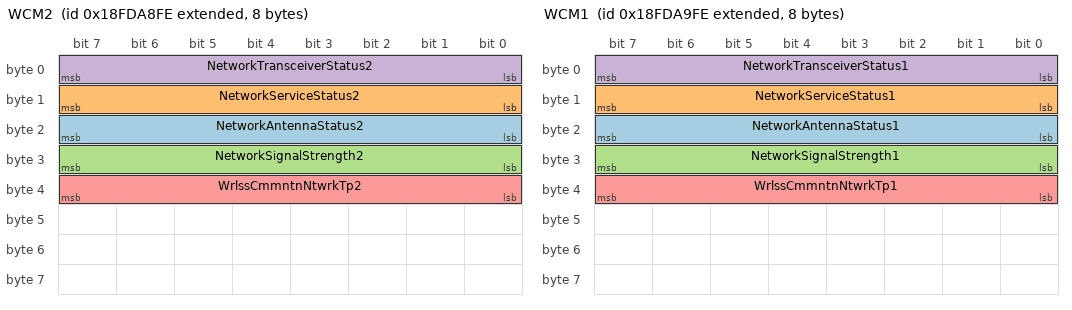
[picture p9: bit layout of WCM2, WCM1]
BO_ 2566760702 WCM2: 8 Vector__XXX
 SG_ NetworkAntennaStatus2 : 16|8@1+ (1,0) [0|255] "" Vector__XXX
 SG_ NetworkServiceStatus2 : 8|8@1+ (1,0) [0|255] "" Vector__XXX
 SG_ NetworkSignalStrength2 : 24|8@1+ (0.4,0) [0|100] "%" Vector__XXX
 SG_ NetworkTransceiverStatus2 : 0|8@1+ (1,0) [0|255] "" Vector__XXX
 SG_ WrlssCmmntnNtwrkTp2 : 32|8@1+ (1,0) [0|255] "" Vector__XXX

BO_ 2566760958 WCM1: 8 Vector__XXX
 SG_ NetworkAntennaStatus1 : 16|8@1+ (1,0) [0|255] "" Vector__XXX
 SG_ NetworkServiceStatus1 : 8|8@1+ (1,0) [0|255] "" Vector__XXX
 SG_ NetworkSignalStrength1 : 24|8@1+ (0.4,0) [0|100] "%" Vector__XXX
 SG_ NetworkTransceiverStatus1 : 0|8@1+ (1,0) [0|255] "" Vector__XXX
 SG_ WrlssCmmntnNtwrkTp1 : 32|8@1+ (1,0) [0|255] "" Vector__XXX

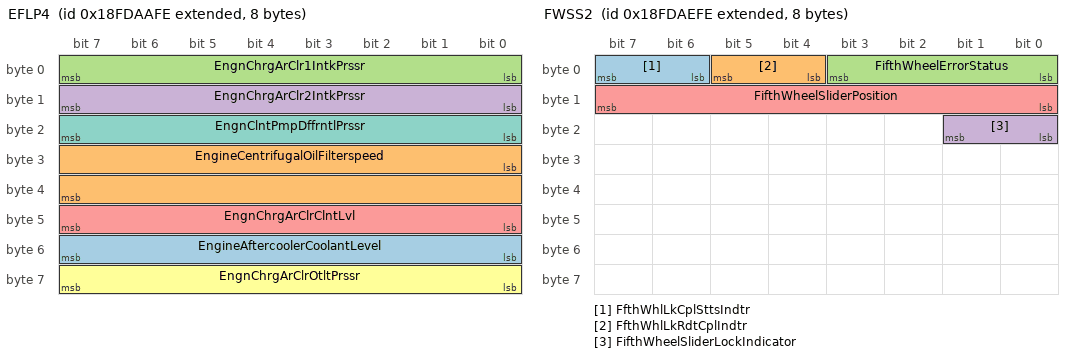
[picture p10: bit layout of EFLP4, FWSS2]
BO_ 2566761214 EFLP4: 8 Vector__XXX
 SG_ EngineAftercoolerCoolantLevel : 48|8@1+ (0.4,0) [0|100] "%" Vector__XXX
 SG_ EngineCentrifugalOilFilterspeed : 24|16@1+ (4,0) [0|257020] "rpm" Vector__XXX
 SG_ EngnChrgArClr1IntkPrssr : 0|8@1+ (2,0) [0|500] "kPa" Vector__XXX
 SG_ EngnChrgArClr2IntkPrssr : 8|8@1+ (2,0) [0|500] "kPa" Vector__XXX
 SG_ EngnChrgArClrClntLvl : 40|8@1+ (0.4,0) [0|100] "%" Vector__XXX
 SG_ EngnChrgArClrOtltPrssr : 56|8@1+ (2,0) [0|500] "kPa" Vector__XXX
 SG_ EngnClntPmpDffrntlPrssr : 16|8@1+ (1.64,-7) [-7|403] "kPa" Vector__XXX

BO_ 2566761726 EFI: 8 Vector__XXX
 SG_ EngineIdleFuelFlowRateThreshold : 8|32@1+ (0.001,0) [0|4211081.215] "l/h" Vector__XXX
 SG_ NmrfFlCnsmptnMntrngTrnsdrs : 0|8@1+ (1,0) [0|250] "count" Vector__XXX

BO_ 2566762238 FWSS2: 8 Vector__XXX
 SG_ FfthWhlLkCplSttsIndtr : 6|2@1+ (1,0) [0|3] "" Vector__XXX
 SG_ FfthWhlLkRdtCplIndtr : 4|2@1+ (1,0) [0|3] "" Vector__XXX
 SG_ FifthWheelErrorStatus : 0|4@1+ (1,0) [0|15] "" Vector__XXX
 SG_ FifthWheelSliderLockIndicator : 16|2@1+ (1,0) [0|3] "" Vector__XXX
 SG_ FifthWheelSliderPosition : 8|8@1+ (10,0) [0|2500] "mm" Vector__XXX

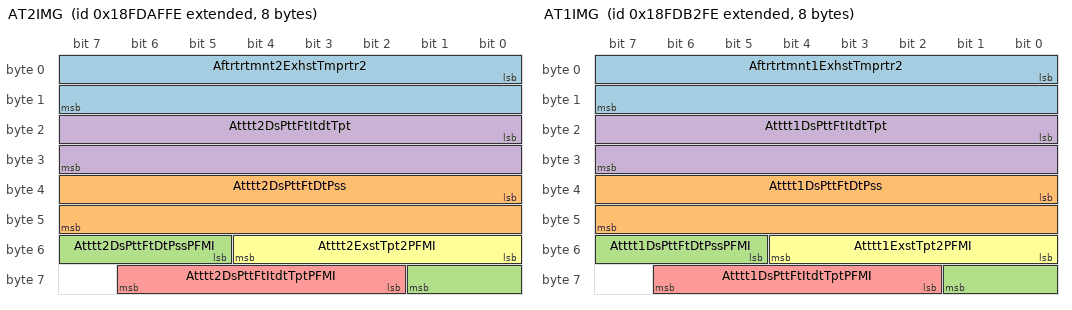
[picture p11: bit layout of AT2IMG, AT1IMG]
BO_ 2566762494 AT2IMG: 8 Vector__XXX
 SG_ Aftrtrtmnt2ExhstTmprtr2 : 0|16@1+ (0.03125,-273) [-273|1734.96875] "degC" Vector__XXX
 SG_ Atttt2DsPttFtDtPss : 32|16@1+ (0.1,0) [0|6425.5] "kPa" Vector__XXX
 SG_ Atttt2DsPttFtDtPssPFMI : 53|5@1+ (1,0) [0|31] "binary" Vector__XXX
 SG_ Atttt2DsPttFtItdtTpt : 16|16@1+ (0.03125,-273) [-273|1734.96875] "degC" Vector__XXX
 SG_ Atttt2DsPttFtItdtTptPFMI : 58|5@1+ (1,0) [0|31] "binary" Vector__XXX
 SG_ Atttt2ExstTpt2PFMI : 48|5@1+ (1,0) [0|31] "binary" Vector__XXX

BO_ 2566762750 AT2OG2: 8 Vector__XXX
 SG_ Aftrtrtmnt2ExhstTmprtr3 : 0|16@1+ (0.03125,-273) [-273|1734.96875] "degC" Vector__XXX
 SG_ Atttt2DsPttFtExstTptPFMI : 40|5@1+ (1,0) [0|31] "binary" Vector__XXX
 SG_ Atttt2DsPttFtOttTpt : 16|16@1+ (0.03125,-273) [-273|1734.96875] "degC" Vector__XXX
 SG_ Atttt2ExstTpt3PFMI : 32|5@1+ (1,0) [0|31] "binary" Vector__XXX

BO_ 2566763006 AT2IG2: 8 Vector__XXX
 SG_ Aftrtrtmnt2ExhstTmprtr1 : 0|16@1+ (0.03125,-273) [-273|1734.96875] "degC" Vector__XXX
 SG_ Atttt2DsPttFtItTpt : 16|16@1+ (0.03125,-273) [-273|1734.96875] "degC" Vector__XXX
 SG_ Atttt2DsPttFtItTptPFMI : 40|5@1+ (1,0) [0|31] "binary" Vector__XXX
 SG_ Atttt2ExstTpt1PFMI : 32|5@1+ (1,0) [0|31] "binary" Vector__XXX

BO_ 2566763262 AT1IMG: 8 Vector__XXX
 SG_ Aftrtrtmnt1ExhstTmprtr2 : 0|16@1+ (0.03125,-273) [-273|1734.96875] "degC" Vector__XXX
 SG_ Atttt1DsPttFtDtPss : 32|16@1+ (0.1,0) [0|6425.5] "kPa" Vector__XXX
 SG_ Atttt1DsPttFtDtPssPFMI : 53|5@1+ (1,0) [0|31] "binary" Vector__XXX
 SG_ Atttt1DsPttFtItdtTpt : 16|16@1+ (0.03125,-273) [-273|1734.96875] "degC" Vector__XXX
 SG_ Atttt1DsPttFtItdtTptPFMI : 58|5@1+ (1,0) [0|31] "binary" Vector__XXX
 SG_ Atttt1ExstTpt2PFMI : 48|5@1+ (1,0) [0|31] "binary" Vector__XXX

BO_ 2566763518 AT1OG2: 8 Vector__XXX
 SG_ Aftrtrtmnt1ExhstTmprtr3 : 0|16@1+ (0.03125,-273) [-273|1734.96875] "degC" Vector__XXX
 SG_ Atttt1DsPttFtOttExstTptPFMI : 40|5@1+ (1,0) [0|31] "binary" Vector__XXX
 SG_ Atttt1DsPttFtOttTpt : 16|16@1+ (0.03125,-273) [-273|1734.96875] "degC" Vector__XXX
 SG_ Atttt1ExstTpt3PFMI : 32|5@1+ (1,0) [0|31] "binary" Vector__XXX

BO_ 2566763774 AT1IG2: 8 Vector__XXX
 SG_ Aftrtrtmnt1ExhstTmprtr1 : 0|16@1+ (0.03125,-273) [-273|1734.96875] "degC" Vector__XXX
 SG_ Atttt1DsPttFtItTpt : 16|16@1+ (0.03125,-273) [-273|1734.96875] "degC" Vector__XXX
 SG_ Atttt1DsPttFtItTptPFMI : 40|5@1+ (1,0) [0|31] "binary" Vector__XXX
 SG_ Atttt1ExstTpt1PFMI : 32|5@1+ (1,0) [0|31] "binary" Vector__XXX

BO_ 2566765054 TPRI: 8 Vector__XXX
 SG_ ReferenceTirePressure : 8|8@1+ (8,0) [0|2000] "kPa" Vector__XXX
 SG_ TireLocation : 0|8@1+ (1,0) [0|255] "" Vector__XXX

BO_ 2566765310 TR6: 8 Vector__XXX
 SG_ FareboxAlarmIdentifier : 8|7@1+ (1,0) [0|127] "" Vector__XXX
 SG_ FareboxEmergencyStatus : 0|2@1+ (1,0) [0|3] "" Vector__XXX

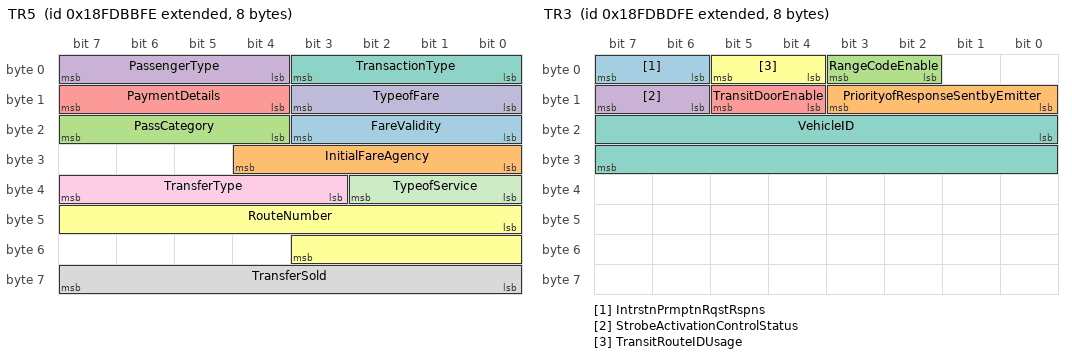
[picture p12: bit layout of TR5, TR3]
BO_ 2566765566 TR5: 8 Vector__XXX
 SG_ FareValidity : 16|4@1+ (1,0) [0|15] "count" Vector__XXX
 SG_ InitialFareAgency : 24|5@1+ (1,0) [0|31] "count" Vector__XXX
 SG_ PassCategory : 20|4@1+ (1,0) [0|15] "count" Vector__XXX
 SG_ PassengerType : 4|4@1+ (1,0) [0|15] "" Vector__XXX
 SG_ PaymentDetails : 12|4@1+ (1,0) [0|15] "" Vector__XXX
 SG_ RouteNumber : 40|12@1+ (1,0) [0|4095] "count" Vector__XXX
 SG_ TransactionType : 0|4@1+ (1,0) [0|15] "" Vector__XXX
 SG_ TransferSold : 56|8@1+ (1,0) [0|255] "count" Vector__XXX
 SG_ TransferType : 35|5@1+ (1,0) [0|31] "" Vector__XXX
 SG_ TypeofFare : 8|4@1+ (1,0) [0|15] "" Vector__XXX
 SG_ TypeofService : 32|3@1+ (1,0) [0|7] "" Vector__XXX

BO_ 2566765822 TR4: 15 Vector__XXX
 SG_ AssignedBlock : 88|16@1+ (1,0) [0|65535] "count" Vector__XXX
 SG_ AssignedRoute : 56|16@1+ (1,0) [0|65535] "count" Vector__XXX
 SG_ AssignedRun : 72|16@1+ (1,0) [0|65535] "count" Vector__XXX
 SG_ Driversfareboxsecuritycode : 104|16@1+ (1,0) [0|65535] "count" Vector__XXX
 SG_ FareboxServiceStatus : 0|2@1+ (1,0) [0|3] "" Vector__XXX
 SG_ FarePresets : 16|8@1+ (1,0) [0|255] "" Vector__XXX
 SG_ PatternNumber : 40|16@1+ (1,0) [0|65535] "count" Vector__XXX
 SG_ TripDirection : 8|4@1+ (1,0) [0|15] "" Vector__XXX
 SG_ TripNumber : 24|16@1+ (1,0) [0|65535] "count" Vector__XXX
 SG_ TripStatus : 2|3@1+ (1,0) [0|7] "" Vector__XXX

BO_ 2566766078 TR3: 8 Vector__XXX
 SG_ IntrstnPrmptnRqstRspns : 6|2@1+ (1,0) [0|3] "" Vector__XXX
 SG_ PriorityofResponseSentbyEmitter : 8|4@1+ (1,0) [0|15] "" Vector__XXX
 SG_ RangeCodeEnable : 2|2@1+ (1,0) [0|3] "" Vector__XXX
 SG_ StrobeActivationControlStatus : 14|2@1+ (1,0) [0|3] "" Vector__XXX
 SG_ TransitDoorEnable : 12|2@1+ (1,0) [0|3] "" Vector__XXX
 SG_ TransitRouteIDUsage : 4|2@1+ (1,0) [0|3] "" Vector__XXX
 SG_ VehicleID : 16|16@1+ (1,0) [0|65535] "count" Vector__XXX

BO_ 2566766334 TR1: 4 Vector__XXX
 SG_ Agency : 0|8@1+ (1,0) [0|255] "count" Vector__XXX
 SG_ NmrftsnthTrnstAssgndBlkIdntt : 24|8@1+ (1,0) [0|250] "byte" Vector__XXX
 SG_ NmrftsnthTrnstAssgndRnIdntt : 16|8@1+ (1,0) [0|250] "byte" Vector__XXX
 SG_ NmrftsnthTrnstAssgndRtIdntt : 8|8@1+ (1,0) [0|250] "byte" Vector__XXX

BO_ 2566766590 TR2: 8 Vector__XXX
 SG_ NmrftsnthMlpstIdntftn : 0|8@1+ (1,0) [0|250] "byte" Vector__XXX

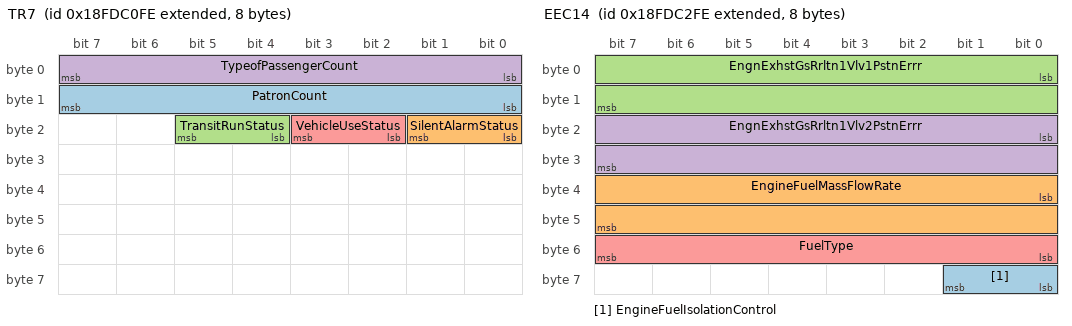
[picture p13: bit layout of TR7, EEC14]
BO_ 2566766846 TR7: 8 Vector__XXX
 SG_ PatronCount : 8|8@1+ (1,0) [0|250] "count" Vector__XXX
 SG_ SilentAlarmStatus : 16|2@1+ (1,0) [0|3] "" Vector__XXX
 SG_ TransitRunStatus : 20|2@1+ (1,0) [0|3] "" Vector__XXX
 SG_ TypeofPassengerCount : 0|8@1+ (1,0) [0|255] "" Vector__XXX
 SG_ VehicleUseStatus : 18|2@1+ (1,0) [0|3] "" Vector__XXX

BO_ 2566767102 EFLP3: 8 Vector__XXX
 SG_ EngnExhstGsRrltn1IntkPrssr : 16|8@1+ (2,0) [0|500] "kPa" Vector__XXX
 SG_ EngnExhstGsRrltn1OtltPrssr : 40|8@1+ (2,0) [0|500] "kPa" Vector__XXX
 SG_ EngnExhstVlvAttnSstmOlPrssr : 24|16@1+ (0.00390625,0) [0|250.996] "MPa" Vector__XXX
 SG_ EngnIntkVlvAttnSstmOlPrssr : 0|16@1+ (0.00390625,0) [0|250.996] "MPa" Vector__XXX
 SG_ EngnThrttlVlv1DffrntlPrssr : 48|16@1+ (0.1,0) [0|6425.5] "kPa" Vector__XXX

BO_ 2566767358 EEC14: 8 Vector__XXX
 SG_ EngineFuelIsolationControl : 56|2@1+ (1,0) [0|3] "" Vector__XXX
 SG_ EngineFuelMassFlowRate : 32|16@1+ (0.005,0) [0|321.275] "g/s" Vector__XXX
 SG_ EngnExhstGsRrltn1Vlv1PstnErrr : 0|16@1+ (0.004,-125) [-125|132.02] "%" Vector__XXX
 SG_ EngnExhstGsRrltn1Vlv2PstnErrr : 16|16@1+ (0.004,-125) [-125|132.02] "%" Vector__XXX
 SG_ FuelType : 48|8@1+ (1,0) [0|255] "" Vector__XXX

BO_ 2566767614 EEC15: 8 Vector__XXX
 SG_ AcceleratorPedal1Channel2 : 0|8@1+ (0.4,0) [0|100] "%" Vector__XXX
 SG_ AcceleratorPedal1Channel3 : 8|8@1+ (0.4,0) [0|100] "%" Vector__XXX
 SG_ AcceleratorPedal2Channel2 : 16|8@1+ (0.4,0) [0|100] "%" Vector__XXX
 SG_ AcceleratorPedal2Channel3 : 24|8@1+ (0.4,0) [0|100] "%" Vector__XXX
 SG_ EngnExhstGsRstrtnVlvCntrl : 32|16@1+ (0.0025,0) [0|160.6375] "%" Vector__XXX

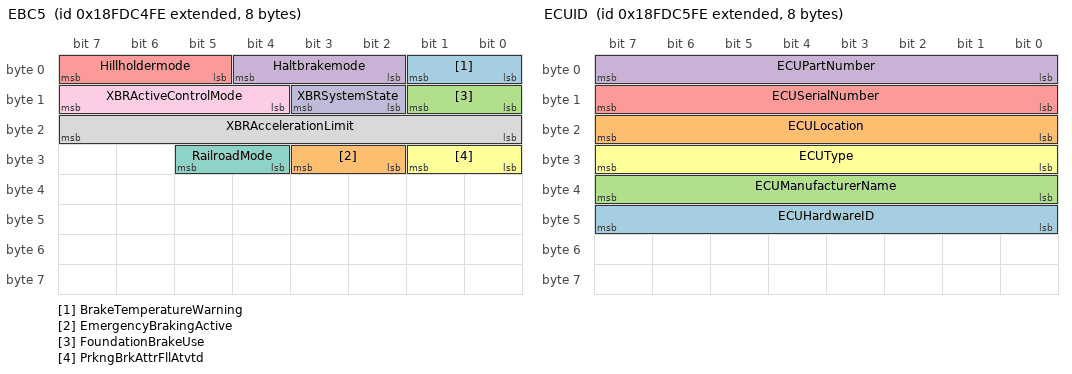
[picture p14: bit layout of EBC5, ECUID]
BO_ 2566767870 EBC5: 8 Vector__XXX
 SG_ BrakeTemperatureWarning : 0|2@1+ (1,0) [0|3] "" Vector__XXX
 SG_ EmergencyBrakingActive : 26|2@1+ (1,0) [0|3] "" Vector__XXX
 SG_ FoundationBrakeUse : 8|2@1+ (1,0) [0|3] "" Vector__XXX
 SG_ Haltbrakemode : 2|3@1+ (1,0) [0|7] "" Vector__XXX
 SG_ Hillholdermode : 5|3@1+ (1,0) [0|7] "" Vector__XXX
 SG_ PrkngBrkAttrFllAtvtd : 24|2@1+ (1,0) [0|3] "" Vector__XXX
 SG_ RailroadMode : 28|2@1+ (1,0) [0|3] "" Vector__XXX
 SG_ XBRAccelerationLimit : 16|8@1+ (0.1,-12.5) [-12.5|12.5] "m/(s*s)" Vector__XXX
 SG_ XBRActiveControlMode : 12|4@1+ (1,0) [0|15] "" Vector__XXX
 SG_ XBRSystemState : 10|2@1+ (1,0) [0|3] "" Vector__XXX

BO_ 2566768126 ECUID: 8 Vector__XXX
 SG_ ECUHardwareID : 40|8@1+ (1,0) [0|255] "ASCII" Vector__XXX
 SG_ ECULocation : 16|8@1+ (1,0) [0|255] "ASCII" Vector__XXX
 SG_ ECUManufacturerName : 32|8@1+ (1,0) [0|255] "ASCII" Vector__XXX
 SG_ ECUPartNumber : 0|8@1+ (1,0) [0|255] "ASCII" Vector__XXX
 SG_ ECUSerialNumber : 8|8@1+ (1,0) [0|255] "ASCII" Vector__XXX
 SG_ ECUType : 24|8@1+ (1,0) [0|255] "ASCII" Vector__XXX

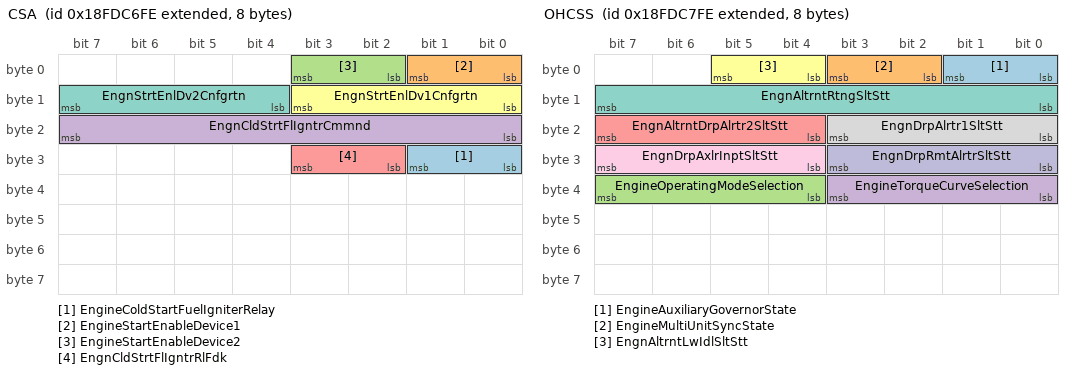
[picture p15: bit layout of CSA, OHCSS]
BO_ 2566768382 CSA: 8 Vector__XXX
 SG_ EngineColdStartFuelIgniterRelay : 24|2@1+ (1,0) [0|3] "" Vector__XXX
 SG_ EngineStartEnableDevice1 : 0|2@1+ (1,0) [0|3] "" Vector__XXX
 SG_ EngineStartEnableDevice2 : 2|2@1+ (1,0) [0|3] "" Vector__XXX
 SG_ EngnCldStrtFlIgntrCmmnd : 16|8@1+ (0.4,0) [0|100] "%" Vector__XXX
 SG_ EngnCldStrtFlIgntrRlFdk : 26|2@1+ (1,0) [0|3] "" Vector__XXX
 SG_ EngnStrtEnlDv1Cnfgrtn : 8|4@1+ (1,0) [0|15] "" Vector__XXX
 SG_ EngnStrtEnlDv2Cnfgrtn : 12|4@1+ (1,0) [0|15] "" Vector__XXX

BO_ 2566768638 OHCSS: 8 Vector__XXX
 SG_ EngineAuxiliaryGovernorState : 0|2@1+ (1,0) [0|3] "" Vector__XXX
 SG_ EngineMultiUnitSyncState : 2|2@1+ (1,0) [0|3] "" Vector__XXX
 SG_ EngineOperatingModeSelection : 36|4@1+ (1,0) [0|15] "" Vector__XXX
 SG_ EngineTorqueCurveSelection : 32|4@1+ (1,0) [0|15] "" Vector__XXX
 SG_ EngnAltrntDrpAlrtr2SltStt : 20|4@1+ (1,0) [0|15] "" Vector__XXX
 SG_ EngnAltrntLwIdlSltStt : 4|2@1+ (1,0) [0|3] "" Vector__XXX
 SG_ EngnAltrntRtngSltStt : 8|8@1+ (1,0) [0|255] "" Vector__XXX
 SG_ EngnDrpAlrtr1SltStt : 16|4@1+ (1,0) [0|15] "" Vector__XXX
 SG_ EngnDrpAxlrInptSltStt : 28|4@1+ (1,0) [0|15] "" Vector__XXX
 SG_ EngnDrpRmtAlrtrSltStt : 24|4@1+ (1,0) [0|15] "" Vector__XXX

BO_ 2566768894 ISCS: 8 Vector__XXX
 SG_ EngnOprtrPrmrIntrmdtSpdSltStt : 0|4@1+ (1,0) [0|15] "" Vector__XXX

BO_ 2566769406 ISC: 8 Vector__XXX
 SG_ EngnOprtrPrmrIntrmdtSpdSlt : 0|4@1+ (1,0) [0|15] "" Vector__XXX

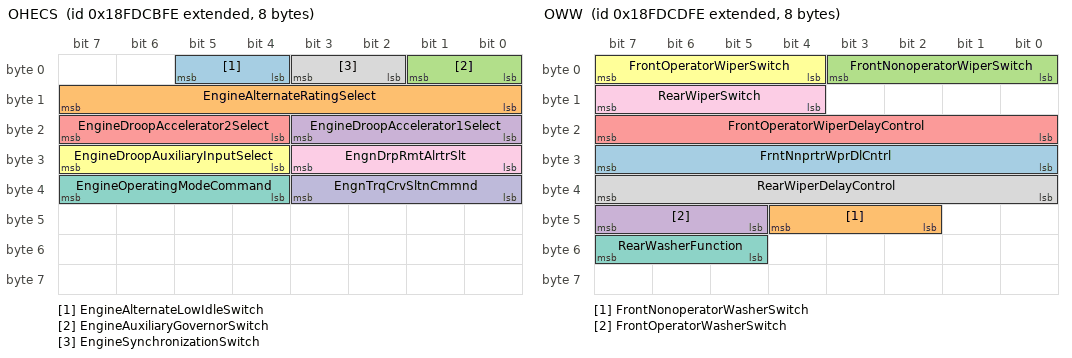
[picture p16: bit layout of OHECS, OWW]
BO_ 2566769662 OHECS: 8 Vector__XXX
 SG_ EngineAlternateLowIdleSwitch : 4|2@1+ (1,0) [0|3] "" Vector__XXX
 SG_ EngineAlternateRatingSelect : 8|8@1+ (1,0) [0|255] "selection" Vector__XXX
 SG_ EngineAuxiliaryGovernorSwitch : 0|2@1+ (1,0) [0|3] "" Vector__XXX
 SG_ EngineDroopAccelerator1Select : 16|4@1+ (1,0) [0|15] "" Vector__XXX
 SG_ EngineDroopAccelerator2Select : 20|4@1+ (1,0) [0|15] "" Vector__XXX
 SG_ EngineDroopAuxiliaryInputSelect : 28|4@1+ (1,0) [0|15] "" Vector__XXX
 SG_ EngineOperatingModeCommand : 36|4@1+ (1,0) [0|15] "" Vector__XXX
 SG_ EngineSynchronizationSwitch : 2|2@1+ (1,0) [0|3] "" Vector__XXX
 SG_ EngnDrpRmtAlrtrSlt : 24|4@1+ (1,0) [0|15] "" Vector__XXX
 SG_ EngnTrqCrvSltnCmmnd : 32|4@1+ (1,0) [0|15] "" Vector__XXX

BO_ 2566770174 OWW: 8 Vector__XXX
 SG_ FrntNnprtrWprDlCntrl : 24|8@1+ (0.4,0) [0|100] "%" Vector__XXX
 SG_ FrontNonoperatorWasherSwitch : 42|3@1+ (1,0) [0|7] "" Vector__XXX
 SG_ FrontNonoperatorWiperSwitch : 0|4@1+ (1,0) [0|15] "" Vector__XXX
 SG_ FrontOperatorWasherSwitch : 45|3@1+ (1,0) [0|7] "" Vector__XXX
 SG_ FrontOperatorWiperDelayControl : 16|8@1+ (0.4,0) [0|100] "%" Vector__XXX
 SG_ FrontOperatorWiperSwitch : 4|4@1+ (1,0) [0|15] "" Vector__XXX
 SG_ RearWasherFunction : 53|3@1+ (1,0) [0|7] "" Vector__XXX
 SG_ RearWiperDelayControl : 32|8@1+ (0.4,0) [0|100] "%" Vector__XXX
 SG_ RearWiperSwitch : 12|4@1+ (1,0) [0|15] "" Vector__XXX

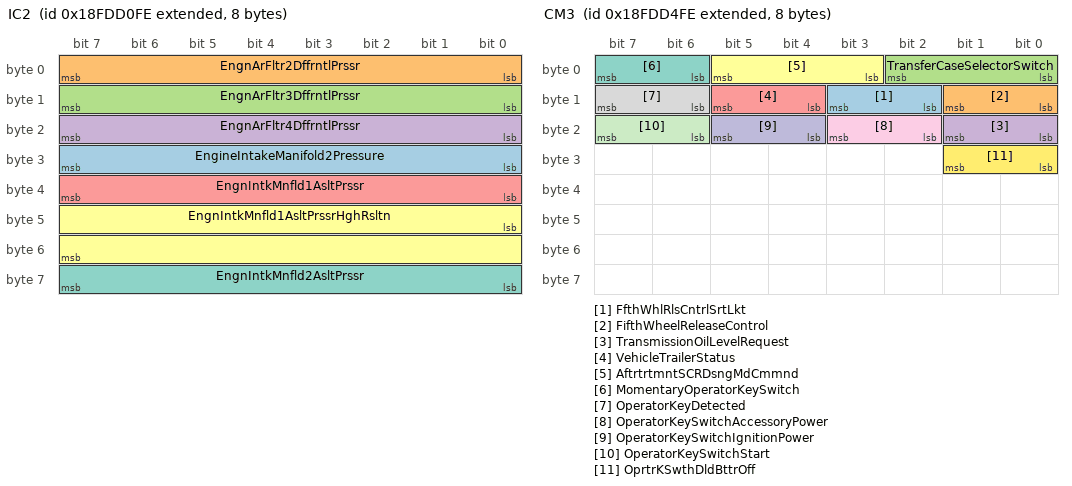
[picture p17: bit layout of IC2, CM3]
BO_ 2566770942 IC2: 8 Vector__XXX
 SG_ EngineIntakeManifold2Pressure : 24|8@1+ (2,0) [0|500] "kPa" Vector__XXX
 SG_ EngnArFltr2DffrntlPrssr : 0|8@1+ (0.05,0) [0|12.5] "kPa" Vector__XXX
 SG_ EngnArFltr3DffrntlPrssr : 8|8@1+ (0.05,0) [0|12.5] "kPa" Vector__XXX
 SG_ EngnArFltr4DffrntlPrssr : 16|8@1+ (0.05,0) [0|12.5] "kPa" Vector__XXX
 SG_ EngnIntkMnfld1AsltPrssr : 32|8@1+ (2,0) [0|500] "kPa" Vector__XXX
 SG_ EngnIntkMnfld1AsltPrssrHghRsltn : 40|16@1+ (0.1,0) [0|6425.5] "kPa" Vector__XXX
 SG_ EngnIntkMnfld2AsltPrssr : 56|8@1+ (2,0) [0|500] "kPa" Vector__XXX

BO_ 2566771454 EP: 8 Vector__XXX
 SG_ DataMemoryUsage : 16|8@1+ (0.4,0) [0|100] "%" Vector__XXX
 SG_ KeepAliveBatteryConsumption : 0|16@1+ (1,0) [0|64255] "mAh" Vector__XXX

BO_ 2566771710 TCI6: 8 Vector__XXX
 SG_ EngnTrhrgr1CmprssrOtltTmprtr : 0|16@1+ (0.03125,-273) [-273|1734.96875] "degC" Vector__XXX
 SG_ EngnTrhrgr2CmprssrOtltTmprtr : 16|16@1+ (0.03125,-273) [-273|1734.96875] "degC" Vector__XXX
 SG_ EngnTrhrgr3CmprssrOtltTmprtr : 32|16@1+ (0.03125,-273) [-273|1734.96875] "degC" Vector__XXX
 SG_ EngnTrhrgr4CmprssrOtltTmprtr : 48|16@1+ (0.03125,-273) [-273|1734.96875] "degC" Vector__XXX

BO_ 2566771966 CM3: 8 Vector__XXX
 SG_ FfthWhlRlsCntrlSrtLkt : 10|2@1+ (1,0) [0|3] "" Vector__XXX
 SG_ FifthWheelReleaseControl : 8|2@1+ (1,0) [0|3] "" Vector__XXX
 SG_ TransferCaseSelectorSwitch : 0|3@1+ (1,0) [0|7] "" Vector__XXX
 SG_ TransmissionOilLevelRequest : 16|2@1+ (1,0) [0|3] "" Vector__XXX
 SG_ VehicleTrailerStatus : 12|2@1+ (1,0) [0|3] "" Vector__XXX
 SG_ AftrtrtmntSCRDsngMdCmmnd : 3|3@1+ (1,0) [0|7] "" Vector__XXX
 SG_ MomentaryOperatorKeySwitch : 6|2@1+ (1,0) [0|3] "" Vector__XXX
 SG_ OperatorKeyDetected : 14|2@1+ (1,0) [0|3] "" Vector__XXX
 SG_ OperatorKeySwitchAccessoryPower : 18|2@1+ (1,0) [0|3] "" Vector__XXX
 SG_ OperatorKeySwitchIgnitionPower : 20|2@1+ (1,0) [0|3] "" Vector__XXX
 SG_ OperatorKeySwitchStart : 22|2@1+ (1,0) [0|3] "" Vector__XXX
 SG_ OprtrKSwthDldBttrOff : 24|2@1+ (1,0) [0|3] "" Vector__XXX

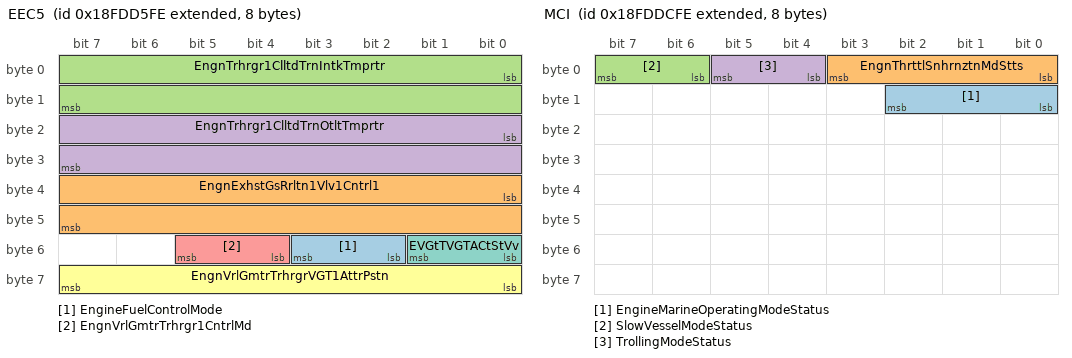
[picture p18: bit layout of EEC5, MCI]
BO_ 2566772222 EEC5: 8 Vector__XXX
 SG_ EngineFuelControlMode : 50|2@1+ (1,0) [0|3] "" Vector__XXX
 SG_ EngnExhstGsRrltn1Vlv1Cntrl1 : 32|16@1+ (0.0025,0) [0|160.6375] "%" Vector__XXX
 SG_ EngnTrhrgr1ClltdTrnIntkTmprtr : 0|16@1+ (0.03125,-273) [-273|1734.96875] "degC" Vector__XXX
 SG_ EngnTrhrgr1ClltdTrnOtltTmprtr : 16|16@1+ (0.03125,-273) [-273|1734.96875] "degC" Vector__XXX
 SG_ EngnVrlGmtrTrhrgr1CntrlMd : 52|2@1+ (1,0) [0|3] "" Vector__XXX
 SG_ EngnVrlGmtrTrhrgrVGT1AttrPstn : 56|8@1+ (0.4,0) [0|100] "%" Vector__XXX
 SG_ EVGtTVGTACtStVv : 48|2@1+ (1,0) [0|3] "" Vector__XXX

BO_ 2566774014 MCI: 8 Vector__XXX
 SG_ EngineMarineOperatingModeStatus : 8|3@1+ (1,0) [0|7] "" Vector__XXX
 SG_ EngnThrttlSnhrnztnMdStts : 0|4@1+ (1,0) [0|15] "" Vector__XXX
 SG_ SlowVesselModeStatus : 6|2@1+ (1,0) [0|3] "" Vector__XXX
 SG_ TrollingModeStatus : 4|2@1+ (1,0) [0|3] "" Vector__XXX

BO_ 2566775038 AMB2: 8 Vector__XXX
 SG_ BrmtrAsltPrssrHghRsltn : 48|16@1+ (0.1,0) [0|6425.5] "kPa" Vector__XXX
 SG_ CalculatedAmbientAirTemperature : 32|16@1+ (0.03125,-273) [-273|1734.96875] "degC" Vector__XXX
 SG_ SolarIntensityPercent : 0|8@1+ (0.4,0) [0|100] "%" Vector__XXX
 SG_ SolarSensorMaximum : 8|8@1+ (0.4,0) [0|100] "mW/(cm*cm)" Vector__XXX
 SG_ SpecificHumidity : 16|16@1+ (0.01,0) [0|642.55] "g/kg" Vector__XXX

BO_ 2566775294 CACI: 8 Vector__XXX
 SG_ AirConditionerCompressorStatus : 8|2@1+ (1,0) [0|3] "" Vector__XXX
 SG_ CACRfrgrntCmprssrOtltPrssr : 0|8@1+ (16,0) [0|4000] "kPa" Vector__XXX

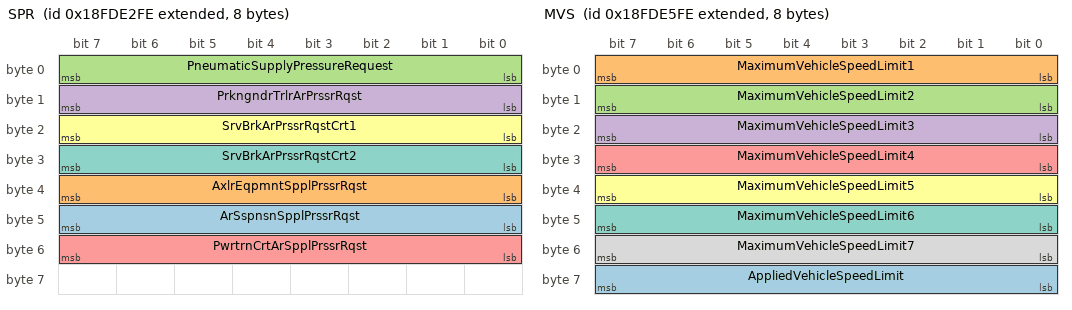
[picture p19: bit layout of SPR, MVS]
BO_ 2566775550 SPR: 8 Vector__XXX
 SG_ ArSspnsnSpplPrssrRqst : 40|8@1+ (8,0) [0|2000] "kPa" Vector__XXX
 SG_ AxlrEqpmntSpplPrssrRqst : 32|8@1+ (8,0) [0|2000] "kPa" Vector__XXX
 SG_ PneumaticSupplyPressureRequest : 0|8@1+ (8,0) [0|2000] "kPa" Vector__XXX
 SG_ PrkngndrTrlrArPrssrRqst : 8|8@1+ (8,0) [0|2000] "kPa" Vector__XXX
 SG_ PwrtrnCrtArSpplPrssrRqst : 48|8@1+ (8,0) [0|2000] "kPa" Vector__XXX
 SG_ SrvBrkArPrssrRqstCrt1 : 16|8@1+ (8,0) [0|2000] "kPa" Vector__XXX
 SG_ SrvBrkArPrssrRqstCrt2 : 24|8@1+ (8,0) [0|2000] "kPa" Vector__XXX

BO_ 2566775806 EOAC: 8 Vector__XXX
 SG_ TravelVelocityControlPosition : 0|8@1+ (1,-125) [-125|125] "%" Vector__XXX

BO_ 2566776062 EPD: 8 Vector__XXX
 SG_ PayloadCapacityPercentage : 56|8@1+ (1,0) [0|250] "%" Vector__XXX
 SG_ PayloadCarryBackWeight : 40|16@1+ (2,0) [0|128510] "kg" Vector__XXX
 SG_ PayloadPercentage : 0|8@1+ (1,0) [0|250] "%" Vector__XXX
 SG_ PayloadWeight : 8|24@1+ (2,0) [0|3E+07] "kg" Vector__XXX
 SG_ PayloadWeightConfidence : 32|8@1+ (0.5,0) [0|125] "%" Vector__XXX

BO_ 2566776318 MVS: 8 Vector__XXX
 SG_ AppliedVehicleSpeedLimit : 56|8@1+ (1,0) [0|250] "km/h" Vector__XXX
 SG_ MaximumVehicleSpeedLimit1 : 0|8@1+ (1,0) [0|250] "km/h" Vector__XXX
 SG_ MaximumVehicleSpeedLimit2 : 8|8@1+ (1,0) [0|250] "km/h" Vector__XXX
 SG_ MaximumVehicleSpeedLimit3 : 16|8@1+ (1,0) [0|250] "km/h" Vector__XXX
 SG_ MaximumVehicleSpeedLimit4 : 24|8@1+ (1,0) [0|250] "km/h" Vector__XXX
 SG_ MaximumVehicleSpeedLimit5 : 32|8@1+ (1,0) [0|250] "km/h" Vector__XXX
 SG_ MaximumVehicleSpeedLimit6 : 40|8@1+ (1,0) [0|250] "km/h" Vector__XXX
 SG_ MaximumVehicleSpeedLimit7 : 48|8@1+ (1,0) [0|250] "km/h" Vector__XXX

CM_ BO_ 2566734334 "Aftertreatment 1 SCR Dosing System Information 2";
CM_ SG_ 2566734334 Aftrtrtmnt1DslExhstFldLnHtr1Stt "The diesel exhaust fluid line heater 1 state for aftertreatment system 1 (exhaust bank 1). 00b = heater inactive 01b = heater active 10b = error 11b = not avail…";
CM_ SG_ 2566734334 Aftrtrtmnt1DslExhstFldLnHtr2Stt "The diesel exhaust fluid line heater 2 state for aftertreatment system 1 (exhaust bank 1). 00b = heater inactive 01b = heater active 10b = error 11b = not avail…";
CM_ SG_ 2566734334 Aftrtrtmnt1DslExhstFldLnHtr3Stt "The diesel exhaust fluid line heater 3 state for aftertreatment system 1 (exhaust bank 1). 00b = heater inactive 01b = heater active 10b = error 11b = not avail…";
CM_ SG_ 2566734334 Aftrtrtmnt1DslExhstFldLnHtr4Stt "The diesel exhaust fluid line heater 4 state for aftertreatment system 1 (exhaust bank 1). 00b = heater inactive 01b = heater active 10b = error 11b = not avail…";
CM_ SG_ 2566734334 Aftrtrtmnt1SCRDsngArAssstVlv "The position of the valve used to regulate the air supply of an air assist SCR dosing system for an engine. 0% represents no supply and 100% is full supply.…";
CM_ SG_ 2566734334 Aftrtrtmnt1SCRFdkCntrlStts "The SCR feedback control status (open/closed loop) for aftertreatment system 1 (exhaust bank 1).000b = open loop control active 001b = closed loop control activ…";
CM_ SG_ 2566734334 Atttt1DsExstFdDs1Tpt "The temperature (measured closest to dosing valve) of the first or only DEF dosing unit for aftertreatment system 1 (exhaust bank 1).…";
CM_ SG_ 2566734334 Atttt1DsExstFdLHt1PFMI "Used to identify the applicable J1939-73 FMI detected in the diesel exhaust fluid line heater 1, by the manufacturer’s control software in exhaust bank 1.  In t…";
CM_ SG_ 2566734334 Atttt1DsExstFdLHt2PFMI "Used to identify the applicable J1939-73 FMI detected in the diesel exhaust fluid line heater 2, by the manufacturer’s control software in exhaust bank 1.  In t…";
CM_ SG_ 2566734334 Atttt1DsExstFdLHt3PFMI "Used to identify the applicable J1939-73 FMI detected in the diesel exhaust fluid line heater 3, by the manufacturer’s control software in exhaust bank 1.  In t…";
CM_ SG_ 2566734334 Atttt1DsExstFdLHt4PFMI "Used to identify the applicable J1939-73 FMI detected in the diesel exhaust fluid line heater 4, by the manufacturer’s control software in exhaust bank 1.  In t…";
CM_ SG_ 2566734334 Atttt1SCRDsAAssstAstPss "The SCR dosing system air assist absolute pressure for aftertreatment system 1 (exhaust bank 1).  The air assist system is used to improve the dosed reagent ato…";
CM_ SG_ 2566734334 Atttt1SCRDsVvExstTptRdtRqst "Protection request for the doser valve of the SCR system to prevent overheating000b = no request 001b = reduction request stage 1010b = reduction request stage …";
CM_ BO_ 2566735102 "Aftertreatment 2 Fuel Control 2";
CM_ SG_ 2566735102 Aftertreatment2FuelPressure2 "Second fuel pressure measurement for the aftertreatment 2 system.…";
CM_ SG_ 2566735102 Aftrtrtmnt2FlFlwDvrtrVlvCntrl "Indicates how the device is controlling the aftertreatment 2 fuel flow diverter valve. When this valve is on it diverts fuel flow from the Aftertreatment 2 Rege…";
CM_ SG_ 2566735102 Aftrtrtmnt2FlPmpRlCntrl "Indicates how the device is controlling the aftertreatment 2 fuel pump relay.00b = off01b = on10b = reserved for SAE assignment11b = not available…";
CM_ SG_ 2566735102 Aftrtrtmnt2FlPrssr2Cntrl "Position that the controller is commanding the aftertreatment 2 fuel pressure 2 control to maintain.  0% = fully closed, 100% = fully open.…";
CM_ BO_ 2566735358 "Aftertreatment 2 Three Way Catalyst";
CM_ SG_ 2566735358 Aftrtrtmnt2ThrWCtlstIntkTmprtr "Temperature of engine combustion byproducts entering the Three Way Catalyst in exhaust bank 2.(For a single exhaust bank system, refer to parameters in PGN 6483…";
CM_ SG_ 2566735358 Aftrtrtmnt2ThrWCtlstOtltTmprtr "Temperature of engine combustion byproducts leaving the Three Way Catalyst in exhaust bank 2.  (For a single exhaust bank system, refer to parameters in PGN 648…";
CM_ SG_ 2566735358 Atttt2TWCtstDtPss "Exhaust differential pressure measured between the intake and exhaust of a Three Way Catalyst in exhaust bank 2.(For a single exhaust bank system, refer to para…";
CM_ SG_ 2566735358 Atttt2TWCtstItTptPFMI "Used to identify the applicable J1939-73 FMI detected in the Three Way Catalyst intake temperature sensor by the manufacturer’s sensor control software in exhau…";
CM_ SG_ 2566735358 Atttt2TWCtstOttTptPFMI "Used to identify the applicable J1939-73 FMI detected in the Three Way Catalyst outlet temperature sensor by the manufacturer’s sensor control software in exhau…";
CM_ SG_ 2566735358 Atttt2TWCttCvtDtPssPFMI "Used to identify the applicable J1939-73 FMI detected in the Three Way Catalytic Converter differential pressure sensor by the manufacturer’s sensor control sof…";
CM_ BO_ 2566735614 "Aftertreatment 1 Three Way Catalyst";
CM_ SG_ 2566735614 Aftrtrtmnt1ThrWCtlstIntkTmprtr "Temperature of engine combustion byproducts entering the Three Way Catalyst in exhaust bank 1.…";
CM_ SG_ 2566735614 Aftrtrtmnt1ThrWCtlstOtltTmprtr "Temperature of engine combustion byproducts leaving the Three Way Catalyst in exhaust bank 1.…";
CM_ SG_ 2566735614 Atttt1TWCtstDtPss "Exhaust differential pressure measured between the intake and exhaust of a Three Way Catalyst in exhaust bank 1.…";
CM_ SG_ 2566735614 Atttt1TWCtstItTptPFMI "Used to identify the applicable J1939-73 FMI detected in the Three Way Catalyst intake temperature sensor by the manufacturer’s sensor control software in exhau…";
CM_ SG_ 2566735614 Atttt1TWCtstOttTptPFMI "Used to identify the applicable J1939-73 FMI detected in the Three Way Catalyst outlet temperature sensor by the manufacturer’s sensor control software in exhau…";
CM_ SG_ 2566735614 Atttt1TWCttCvtDtPssPFMI "Used to identify the applicable J1939-73 FMI detected in the Three Way Catalytic Converter differential pressure sensor by the manufacturer’s sensor control sof…";
CM_ BO_ 2566736126 "Engine Exhaust Bank 2 O2 Fuel Trim";
CM_ SG_ 2566736126 EngnExhstBnk2O2SnsrClsdLpOprtn "This parameter indicates the status of the bank 2 O2 sensor feedback closed loop operation0000b = Open loop - has not yet satisfied conditions to go closed loop…";
CM_ SG_ 2566736126 LongtermFuelTrimBank2 "This parameter is the long-term percent change in fueling based on the O2 sensor feedback for cylinder bank 2, based on the operating point in the nominal fuel …";
CM_ SG_ 2566736126 ShorttermFuelTrimBank2 "This parameter is the short-term percent change in fueling based on the O2 sensor feedback for cylinder bank 2, based on the operating point in the nominal fuel…";
CM_ BO_ 2566736382 "Engine Exhaust Bank 1 O2 Fuel Trim";
CM_ SG_ 2566736382 EngnExhstBnk1O2SnsrClsdLpOprtn "This parameter indicates the status of the bank 1 O2 sensor feedback closed loop operation0000b = Open loop - has not yet satisfied conditions to go closed loop…";
CM_ SG_ 2566736382 LongtermFuelTrimBank1 "This parameter is the long-term percent change in fueling based on the O2 sensor feedback for cylinder bank 1, based on the operating point in the nominal fuel …";
CM_ SG_ 2566736382 ShorttermFuelTrimBank1 "This parameter is the short-term percent change in fueling based on the O2 sensor feedback for cylinder bank 1, based on the operating point in the nominal fuel…";
CM_ BO_ 2566743550 "Aftertreatment 1 Fuel Control 2";
CM_ SG_ 2566743550 Aftertreatment1FuelPressure2 "Second fuel pressure measurement for the aftertreatment 1 system…";
CM_ SG_ 2566743550 Aftrtrtmnt1FlFlwDvrtrVlvCntrl "Indicates how the device is controlling the aftertreatment 1 fuel flow diverter valve. When this valve is on it diverts fuel flow from the Aftertreatment 1 Rege…";
CM_ SG_ 2566743550 Aftrtrtmnt1FlPmpRlCntrl "Indicates how the device is controlling the aftertreatment 1 fuel pump relay.00b = off01b = on10b = reserved for SAE assignment11b = not available…";
CM_ SG_ 2566743550 Aftrtrtmnt1HdrrnDsrIntkFlTmprtr "Measured temperature of the intake fuel to the hydrocarbon dosing device.…";
CM_ SG_ 2566743550 Aftrtrtmnt1FlPrssr2Cntrl "Position that the controller is commanding the aftertreatment 1 fuel pressure 2 control to maintain.  0% = fully closed, 100% = fully open.…";
CM_ BO_ 2566743806 "Engine Temperature 4";
CM_ SG_ 2566743806 EngineCoolantTemperature2 "Second temperature of liquid found in the engine cooling system.   See also SPNs 110, 4193 and 6209.…";
CM_ SG_ 2566743806 EngineCoolantTemperature3 "Third temperature of liquid found in the engine cooling system. See also SPNs 110, 4076 and 4193.…";
CM_ SG_ 2566743806 EngineCoolantThermostatOpening "The current position of the Thermostat used to regulate the temperature of the engine coolant.  0% represents the thermostat allows flow to completely bypass th…";
CM_ SG_ 2566743806 EngnClntPmpOtltTmprtr "The actual value of engine coolant temperature at the coolant pump outlet.  See also SPNs 110, 4076 and 6209 for additional coolant temperature parameters.…";
CM_ SG_ 2566743806 EngnExhstGsRrltn1MxrIntkTmprtr "The temperature of the EGR gas entering the intake mixer, measured after the intake throttle when provided.…";
CM_ SG_ 2566743806 EngnExhstVlvAttnSstmOlTmprtr "The temperature of the oil in the hydraulic system that powers the engine exhaust valve actuation system…";
CM_ BO_ 2566744062 "Zero Net Vehicle Weight Change";
CM_ SG_ 2566744062 ZeroNetVehicleWeightChange "Zero Net Vehicle Weight Change command.  A controller receiving this command will record the current Gross Combination Weight as the new Zero, and future reques…";
CM_ BO_ 2566745086 "Available Axle Group Weights";
CM_ SG_ 2566745086 AddtnlTrlrAxlGrpWghtAvll "Indicates the availability of the additional trailer axle group for purposes of weight measurement00b = Additional trailer axle group not present01b = Additiona…";
CM_ SG_ 2566745086 AddtnlTrtrAxlGrpWghtAvll "Indicates the availability of the additional tractor axle group for purposes of weight measurement00b = Additional tractor axle group not present01b = Additiona…";
CM_ SG_ 2566745086 LiftAxleGroupWeightAvailable "Indicates the availability of the lift axle group for purposes of weight measurement00b = Lift axle group not present01b = Lift axle group present10b = Reserved…";
CM_ SG_ 2566745086 RrDrvAxlGrpWghtAvll "Indicates if a second (or rear) drive axle group weight is available.00b = Rear drive axle group not present01b = Rear drive axle group present10b = Reserved11b…";
CM_ SG_ 2566745086 RrStrAxlGrpWghtAvll "Indicates if a second (or rear) steer axle group weight is available.00b = Rear Steer axle group not present01b = Rear Steer axle group present10b = Reserved11b…";
CM_ SG_ 2566745086 SlrFrwrdmstDrvAxlGrpWghtAvll "Indicates the availability of the sole or forward-most drive axle group for purposes of weight measurement00b = Drive axle group not present01b = Drive axle gro…";
CM_ SG_ 2566745086 SlrFrwrdmstStrAxlGrpWghtAvll "Indicates the availability of the sole or forward-most steer axle group for purposes of weight measurement00b = Steer axle group not present01b = Steer axle gro…";
CM_ SG_ 2566745086 TagAxleGroupWeightAvailable "Indicates the availability of the tag axle group for purposes of weight measurement00b = Tag axle group not present01b = Tag axle group present10b = Reserved11b…";
CM_ SG_ 2566745086 TrlrAAxlGrpWghtAvll "Indicates the availability of the trailer A axle group for purposes of weight measurement00b = Trailer A axle group not present01b = Trailer A axle group presen…";
CM_ SG_ 2566745086 TrlrBAxlGrpWghtAvll "Indicates the availability of the trailer B axle group for purposes of weight measurement00b = Trailer B axle group not present01b = Trailer B axle group presen…";
CM_ SG_ 2566745086 TrlrCAxlGrpWghtAvll "Indicates the availability of the trailer C axle group for purposes of weight measurement00b = Trailer C axle group not present01b = Trailer C axle group presen…";
CM_ SG_ 2566745086 TrlrDAxlGrpWghtAvll "Indicates the availability of the trailer D axle group for purposes of weight measurement00b = Trailer D axle group not present01b = Trailer D axle group presen…";
CM_ SG_ 2566745086 TrlrEAxlGrpWghtAvll "Indicates the availability of the trailer E axle group for purposes of weight measurement00b = Trailer E axle group not present01b = Trailer E axle group presen…";
CM_ SG_ 2566745086 TrlrFAxlGrpWghtAvll "Indicates the availability of the trailer F axle group for purposes of weight measurement00b = Trailer F axle group not present01b = Trailer F axle group presen…";
CM_ SG_ 2566745086 TrlrGAxlGrpWghtAvll "Indicates the availability of the trailer G axle group for purposes of weight measurement00b = Trailer G axle group not present01b = Trailer G axle group presen…";
CM_ SG_ 2566745086 TrlrHAxlGrpWghtAvll "Indicates the availability of the trailer H axle group for purposes of weight measurement00b = Trailer H axle group not present01b = Trailer H axle group presen…";
CM_ BO_ 2566745342 "Aftertreatment 2 Air Control 2";
CM_ SG_ 2566745342 Aftrtrtmnt2SndrArDffrntlPrssr "Indicates the secondary air differential pressure for aftertreatment 2.  Secondary air is air provided to the exhaust system (per SAE J2403).…";
CM_ SG_ 2566745342 Aftrtrtmnt2SndrArMssFlwRt "Indicates the secondary air mass flow for aftertreatment 2.  Secondary air is the air provided to the exhaust system (per SAE J2403).…";
CM_ SG_ 2566745342 Aftrtrtmnt2SndrArPrssr "Pressure of the secondary air for aftertreatment 2.  Secondary air is air provided to the exhaust system (per SAE J2403).For absolute pressure, see SPN 5590.…";
CM_ SG_ 2566745342 Aftrtrtmnt2SndrArTmprtr "Indicates the secondary air temperature for aftertreatment 2.  Secondary air is air provided to the exhaust system (per SAE J2403).…";
CM_ BO_ 2566745598 "Aftertreatment 1 Air Control 2";
CM_ SG_ 2566745598 Aftrtrtmnt1SndrArDffrntlPrssr "Indicates the secondary air differential pressure for aftertreatment 1.  Secondary air is air provided to the exhaust system (per SAE J2403).…";
CM_ SG_ 2566745598 Aftrtrtmnt1SndrArMssFlwRt "Indicates the secondary air mass flow for aftertreatment 1.  Secondary air is the air provided to the exhaust system (per SAE J2403).…";
CM_ SG_ 2566745598 Aftrtrtmnt1SndrArPrssr "Pressure of the secondary air for aftertreatment 1.  Secondary air is air provided to the exhaust system (per SAE J2403).For absolute pressure, see SPN 5589.…";
CM_ SG_ 2566745598 Aftrtrtmnt1SndrArTmprtr "Indicates the secondary air temperature for aftertreatment 1.  Secondary air is air provided to the exhaust system (per SAE J2403).…";
CM_ BO_ 2566745854 "Aftertreatment 1 SCR Service Information 1";
CM_ SG_ 2566745854 Aftrtrtmnt1SCRCnvrsnEffn "The SCR conversion efficiency percentage.  Calculated as 100 times the catalyst intake NOx minus the catalyst outlet NOx divided by the catalyst intake NOx.  Th…";
CM_ SG_ 2566745854 Aftrtrtmnt1SCRSstmSlftnLvl "Indicates the sulfur level in the SCR system for aftertreatment 1..100% level could be the regeneration trigger level (and if conditions are not favorable for r…";
CM_ SG_ 2566745854 Atttt1DsExstFdAvCspt "Measured use of diesel exhaust fluid by a Selective Catalytic Reduction system for exhaust emission control, averaged over the previous 15 hours of engine opera…";
CM_ SG_ 2566745854 Atttt1SCRCddDsExstFdCspt "This parameter transmits the amount of diesel exhaust fluid that the emissions control system has requested to be used, averaged over the past 15 hours of engin…";
CM_ SG_ 2566745854 AttttSCROptIdtAtvTvdDst "The distance traveled while SCR inducement (SPN 5246 is equal to level 1 to 5) is active.  Distance is reset once inducement is no longer active for SCR (SPN 52…";
CM_ BO_ 2566746110 "Electronic Engine Controller 8";
CM_ SG_ 2566746110 EExstGsRt1CItAstPss "Exhaust gas recirculation absolute pressure is measured at the EGR cooler intake. See SPN 3358 for EGR pressure measured at the EGR cooler outlet before the val…";
CM_ SG_ 2566746110 EngnExhstGsRrltn1ClrEffn "Exhaust Gas Recirculation cooler efficiency is an indication of the cooler’s ability to reduce the temperature of the exhaust gas that is being recirculated bac…";
CM_ SG_ 2566746110 EngnExhstGsRrltn1ClrIntkTmprtr "Exhaust Gas Recirculation (EGR) Temperature measured at the EGR cooler intake.  See SPN 412 for Engine EGR temperature which is typically measured at the EGR co…";
CM_ SG_ 2566746110 EngnExhstGsRrltn1Vlv2Cntrl "Desired percentage of maximum Exhaust Gas Recirculation (EGR) valve opening for valve 2.  0% means valve is closed. 100% means maximum valve opening (full gas f…";
CM_ BO_ 2566746366 "Door ramp control";
CM_ SG_ 2566746366 Enablestatusoframp1 "Enable status of ramp at doorway 1, counting from front to back on the vehicle.00b = ramp disabled01b = ramp enabled 10b = error 11b = not available…";
CM_ SG_ 2566746366 Enablestatusoframp2 "Enable status of ramp at doorway 2, counting from front to back on the vehicle.00b = ramp disabled01b = ramp enabled 10b = error 11b = not available…";
CM_ SG_ 2566746366 Enablestatusoframp3 "Enable status of ramp at doorway 3, counting from front to back on the vehicle.00b = ramp disabled01b = ramp enabled 10b = error 11b = not available…";
CM_ SG_ 2566746366 Enablestatusoframp4 "Enable status of ramp at doorway 4, counting from front to back on the vehicle.00b = ramp disabled01b = ramp enabled 10b = error 11b = not available…";
CM_ SG_ 2566746366 Enablestatusoframp5 "Enable status of ramp at doorway 5, counting from front to back on the vehicle.00b = ramp disabled01b = ramp enabled 10b = error 11b = not available…";
CM_ SG_ 2566746366 Movementstatusoframp1 "Movement status of ramp at doorway 1, counting from front to back on the vehicle.00b = ramp not being moved01b = ramp being moved10b = error11b = not available…";
CM_ SG_ 2566746366 Movementstatusoframp2 "Movement status of ramp at doorway 2, counting from front to back on the vehicle.00b = ramp not being moved01b = ramp being moved10b = error11b = not available…";
CM_ SG_ 2566746366 Movementstatusoframp3 "Movement status of ramp at doorway 3, counting from front to back on the vehicle.00b = ramp not being moved01b = ramp being moved10b = error11b = not available…";
CM_ SG_ 2566746366 Movementstatusoframp4 "Movement status of ramp at doorway 4, counting from front to back on the vehicle.00b = ramp not being moved01b = ramp being moved10b = error11b = not available…";
CM_ SG_ 2566746366 Movementstatusoframp5 "Movement status of ramp at doorway 5, counting from front to back on the vehicle.00b = ramp not being moved01b = ramp being moved10b = error11b = not available…";
CM_ SG_ 2566746366 RetractStatusoframp1 "Retract status of ramp at doorway 1, counting from front to back on the vehicle.00b = ramp retracted01b = ramp extended10b = error11b = not available…";
CM_ SG_ 2566746366 RetractStatusoframp2 "Retract status of ramp at doorway 2, counting from front to back on the vehicle.00b = ramp retracted01b = ramp extended10b = error11b = not available…";
CM_ SG_ 2566746366 RetractStatusoframp3 "Retract status of ramp at doorway 3, counting from front to back on the vehicle.00b = ramp retracted01b = ramp extended10b = error11b = not available…";
CM_ SG_ 2566746366 RetractStatusoframp4 "Retract status of ramp at doorway 4, counting from front to back on the vehicle.00b = ramp retracted01b = ramp extended10b = error11b = not available…";
CM_ SG_ 2566746366 RetractStatusoframp5 "Retract status of ramp at doorway 5, counting from front to back on the vehicle.00b = ramp retracted01b = ramp extended10b = error11b = not available…";
CM_ BO_ 2566746622 "Brake actuator stroke status";
CM_ SG_ 2566746622 TractorBrakeStrokeAxle1Left "Brake stroke status for left brake actuator on tractor axle 1. 000b = OK (Normal operation)  001b = Non-functioning010b = Overstroke 011b = Dragging brake100b =…";
CM_ SG_ 2566746622 TractorBrakeStrokeAxle1Right "Brake stroke status for right brake actuator on tractor axle 1. 000b = OK (Normal operation)001b = Non-functioning010b = Overstroke011b = Dragging brake100b = R…";
CM_ SG_ 2566746622 TractorBrakeStrokeAxle2Left "Brake stroke status for left brake actuator on tractor axle 2. 000b = OK (Normal operation)001b = Non-functioning010b = Overstroke011b = Dragging brake100b = Re…";
CM_ SG_ 2566746622 TractorBrakeStrokeAxle2Right "Brake stroke status for right brake actuator on tractor axle 2.000b = OK (Normal operation)001b = Non-functioning010b = Overstroke011b = Dragging brake100b = Re…";
CM_ SG_ 2566746622 TractorBrakeStrokeAxle3Left "Brake stroke status for left brake actuator on tractor axle 3.000b = OK (Normal operation)001b = Non-functioning010b = Overstroke011b = Dragging brake100b = Res…";
CM_ SG_ 2566746622 TractorBrakeStrokeAxle3Right "Brake stroke status for right brake actuator on tractor axle 3.000b = OK (Normal operation)001b = Non-functioning010b = Overstroke011b = Dragging brake100b = Re…";
CM_ SG_ 2566746622 TractorBrakeStrokeAxle4Left "Brake stroke status for left brake actuator on tractor axle 4.000b = OK (Normal operation)001b = Non-functioning010b = Overstroke011b = Dragging brake100b = Res…";
CM_ SG_ 2566746622 TractorBrakeStrokeAxle4Right "Brake stroke status for right brake actuator on tractor axle 4.000b = OK (Normal operation)001b = Non-functioning010b = Overstroke011b = Dragging brake100b = Re…";
CM_ SG_ 2566746622 TractorBrakeStrokeAxle5Left "Brake stroke status for left brake actuator on tractor axle 5.000b = OK (Normal operation)001b = Non-functioning010b = Overstroke011b = Dragging brake100b = Res…";
CM_ SG_ 2566746622 TractorBrakeStrokeAxle5Right "Brake stroke status for right brake actuator on tractor axle 5.000b = OK (Normal operation)001b = Non-functioning010b = Overstroke011b = Dragging brake100b = Re…";
CM_ SG_ 2566746622 TrailerBrakeStrokeAxle1Left "Brake stroke status for left brake actuator on trailerr axle 1.000b = OK (Normal operation)001b = Non-functioning010b = Overstroke011b = Dragging brake100b = Re…";
CM_ SG_ 2566746622 TrailerBrakeStrokeAxle1Right "Brake stroke status for right brake actuator on trailer axle 1.000b = OK (Normal operation)001b = Non-functioning010b = Overstroke011b = Dragging brake100b = Re…";
CM_ SG_ 2566746622 TrailerBrakeStrokeAxle2Left "Brake stroke status for left brake actuator on trailer axle 2.000b = OK (Normal operation)001b = Non-functioning010b = Overstroke011b = Dragging brake100b = Res…";
CM_ SG_ 2566746622 TrailerBrakeStrokeAxle2Right "Brake stroke status for right brake actuator on trailer axle 2.000b = OK (Normal operation)001b = Non-functioning010b = Overstroke011b = Dragging brake100b = Re…";
CM_ SG_ 2566746622 TrailerBrakeStrokeAxle3Left "Brake stroke status for left brake actuator on trailer axle 3.000b = OK (Normal operation)001b = Non-functioning010b = Overstroke011b = Dragging brake100b = Res…";
CM_ SG_ 2566746622 TrailerBrakeStrokeAxle3Right "Brake stroke status for right brake actuator on trailer axle 3.000b = OK (Normal operation)001b = Non-functioning010b = Overstroke011b = Dragging brake100b = Re…";
CM_ SG_ 2566746622 TrailerBrakeStrokeAxle4Left "Brake stroke status for left brake actuator on trailer axle 4.000b = OK (Normal operation)001b = Non-functioning010b = Overstroke011b = Dragging brake100b = Res…";
CM_ SG_ 2566746622 TrailerBrakeStrokeAxle4Right "Brake stroke status for right brake actuator on trailer axle 4.000b = OK (Normal operation)001b = Non-functioning010b = Overstroke011b = Dragging brake100b = Re…";
CM_ SG_ 2566746622 TrailerBrakeStrokeAxle5Left "Brake stroke status for left brake actuator on trailer axle 5.000b = OK (Normal operation)001b = Non-functioning010b = Overstroke011b = Dragging brake100b = Res…";
CM_ SG_ 2566746622 TrailerBrakeStrokeAxle5Right "Brake stroke status for right brake actuator on trailer axle 5.000b = OK (Normal operation)001b = Non-functioning010b = Overstroke011b = Dragging brake100b = Re…";
CM_ BO_ 2566746878 "Engine Spark Voltage 6";
CM_ SG_ 2566746878 EngineSparkPlug21 "The measured voltage of the spark event on Cylinder #21…";
CM_ SG_ 2566746878 EngineSparkPlug22 "The measured voltage of the spark event on Cylinder #22…";
CM_ SG_ 2566746878 EngineSparkPlug23 "The measured voltage of the spark event on Cylinder #23…";
CM_ SG_ 2566746878 EngineSparkPlug24 "The measured voltage of the spark event on Cylinder #24…";
CM_ BO_ 2566747134 "Engine Spark Voltage 5";
CM_ SG_ 2566747134 EngineSparkPlug17 "The measured voltage of the spark event on Cylinder #17…";
CM_ SG_ 2566747134 EngineSparkPlug18 "The measured voltage of the spark event on Cylinder #18…";
CM_ SG_ 2566747134 EngineSparkPlug19 "The measured voltage of the spark event on Cylinder #19…";
CM_ SG_ 2566747134 EngineSparkPlug20 "The measured voltage of the spark event on Cylinder #20…";
CM_ BO_ 2566747390 "Engine Spark Voltage 4";
CM_ SG_ 2566747390 EngineSparkPlug13 "The measured voltage of the spark event on Cylinder #13…";
CM_ SG_ 2566747390 EngineSparkPlug14 "The measured voltage of the spark event on Cylinder #14…";
CM_ SG_ 2566747390 EngineSparkPlug15 "The measured voltage of the spark event on Cylinder #15…";
CM_ SG_ 2566747390 EngineSparkPlug16 "The measured voltage of the spark event on Cylinder #16…";
CM_ BO_ 2566747646 "Engine Spark Voltage 3";
CM_ SG_ 2566747646 EngineSparkPlug10 "The measured voltage of the spark event on Cylinder #10…";
CM_ SG_ 2566747646 EngineSparkPlug11 "The measured voltage of the spark event on Cylinder #11…";
CM_ SG_ 2566747646 EngineSparkPlug12 "The measured voltage of the spark event on Cylinder #12…";
CM_ SG_ 2566747646 EngineSparkPlug9 "The measured voltage of the spark event on Cylinder #9…";
CM_ BO_ 2566747902 "Engine Spark Voltage 2";
CM_ SG_ 2566747902 EngineSparkPlug5 "The measured voltage of the spark event on Cylinder #5…";
CM_ SG_ 2566747902 EngineSparkPlug6 "The measured voltage of the spark event on Cylinder #6…";
CM_ SG_ 2566747902 EngineSparkPlug7 "The measured voltage of the spark event on Cylinder #7…";
CM_ SG_ 2566747902 EngineSparkPlug8 "The measured voltage of the spark event on Cylinder #8…";
CM_ BO_ 2566748158 "Engine Spark Voltage 1";
CM_ SG_ 2566748158 EngineSparkPlug1 "The measured voltage of the spark event on Cylinder #1…";
CM_ SG_ 2566748158 EngineSparkPlug2 "The measured voltage of the spark event on Cylinder #2…";
CM_ SG_ 2566748158 EngineSparkPlug3 "The measured voltage of the spark event on Cylinder #3…";
CM_ SG_ 2566748158 EngineSparkPlug4 "The measured voltage of the spark event on Cylinder #4…";
CM_ BO_ 2566748414 "Aftertreatment 2 Trip Information";
CM_ SG_ 2566748414 Aftrtrtmnt2DslPrtltFltrTrpFlUsd "Total amount of fuel used by the aftertreatment 2 diesel particulate filter during the current trip period.NOTE: This SPN needs to be reset by the reset PGN 568…";
CM_ SG_ 2566748414 Atttt2DsPttFtTpAtvRtT "Total amount of time that the aftertreatment 2 diesel particulate filter has been in active regeneration during the current trip period.NOTE: This SPN needs to …";
CM_ SG_ 2566748414 Atttt2DsPttFtTpDsdT "Total amount of time that aftertreatment 2 diesel particulate filter regeneration has been manually disabled during the current trip period.NOTE: This SPN needs…";
CM_ SG_ 2566748414 Atttt2DsPttFtTpNAtvRtItRqsts "Total number of aftertreatment 2 diesel particulate filter active regeneration inhibit requests by the operator during the current trip period.NOTE: This SPN ne…";
CM_ SG_ 2566748414 Atttt2DsPttFtTpNAtvRtMRqsts "Total number of aftertreatment 2 diesel particulate filter active regeneration manual requests by the operator during the current trip period.NOTE: This SPN nee…";
CM_ SG_ 2566748414 Atttt2DsPttFtTpNAtvRts "Total number of active regenerations of the aftertreatment 2 diesel particulate filter during the current trip period.NOTE: This SPN needs to be reset by the re…";
CM_ SG_ 2566748414 Atttt2DsPttFtTpNPssvRts "Total number of passive regenerations of the aftertreatment 2 diesel particulate filter during the current trip period.NOTE: This SPN needs to be reset by the r…";
CM_ SG_ 2566748414 Atttt2DsPttFtTpPssvRtT "Total amount of time that the aftertreatment 2 diesel particulate filter has been in passive regeneration during the current trip period.NOTE: This SPN needs to…";
CM_ BO_ 2566748670 "Aftertreatment 1 Trip Information";
CM_ SG_ 2566748670 Aftrtrtmnt1DslPrtltFltrTrpFlUsd "Total amount of fuel used by the aftertreatment 1 diesel particulate filter during the current trip period.NOTE: This SPN needs to be reset by the reset PGN 568…";
CM_ SG_ 2566748670 Atttt1DsPttFtTpAtvRtT "Total amount of time that the aftertreatment 1 diesel particulate filter has been in active regeneration during the current trip period.NOTE: This SPN needs to …";
CM_ SG_ 2566748670 Atttt1DsPttFtTpDsdT "Total amount of time that aftertreatment 1 diesel particulate filter regeneration has been manually disabled during the current trip period.NOTE: This SPN needs…";
CM_ SG_ 2566748670 Atttt1DsPttFtTpNAtvRtItRqsts "Total number of aftertreatment 1 diesel particulate filter active regeneration inhibit requests by the operator during the current trip period.NOTE: This SPN ne…";
CM_ SG_ 2566748670 Atttt1DsPttFtTpNAtvRtMRqsts "Total number of aftertreatment 1 diesel particulate filter active regeneration manual requests by the operator during the current trip period.NOTE: This SPN nee…";
CM_ SG_ 2566748670 Atttt1DsPttFtTpNAtvRts "Total number of active regenerations of the aftertreatment 1 diesel particulate filter during the current trip period.NOTE: This SPN needs to be reset by the re…";
CM_ SG_ 2566748670 Atttt1DsPttFtTpNPssvRts "Total number of passive regenerations of the aftertreatment 1 diesel particulate filter during the current trip period.NOTE: This SPN needs to be reset by the r…";
CM_ SG_ 2566748670 Atttt1DsPttFtTpPssvRtT "Total amount of time that the aftertreatment 1 diesel particulate filter has been in passive regeneration during the current trip period.NOTE: This SPN needs to…";
CM_ BO_ 2566748926 "Aftertreatment 2 Service 1";
CM_ SG_ 2566748926 Aftrtrtmnt2DslPrtltFltrStLdPrnt "Indicates the soot load percent of diesel particulate filter 2.  100% is the level at which active diesel particulate filter regeneration should be triggered.10…";
CM_ SG_ 2566748926 Atttt2DsPttFtAsLdPt "Indicates the ash load percent of diesel particulate filter 2.  100% is the level at which diesel particulate filter ash service should be performed.100% level …";
CM_ SG_ 2566748926 Atttt2DsPttFtStLdRtTsd "This parameter indicates the value that will first cause DPF regeneration in aftertreatment 2. There may be multiple parameters that cause DPF regeneration (e.g…";
CM_ SG_ 2566748926 Atttt2DsPttFtTSLstAtvRt "Indicates the time since the last active regeneration event of diesel particulate filter 2.…";
CM_ BO_ 2566749182 "Aftertreatment 1 Service 1";
CM_ SG_ 2566749182 Aftrtrtmnt1DslPrtltFltrStLdPrnt "Indicates the soot load percent of diesel particulate filter 1.  100% is the level at which active diesel particulate filter regeneration should be triggered.10…";
CM_ SG_ 2566749182 Atttt1DsPttFtAsLdPt "Indicates the ash load percent of diesel particulate filter 1.  100% is the level at which diesel particulate filter ash service should be performed.100% level …";
CM_ SG_ 2566749182 Atttt1DsPttFtStLdRtTsd "This parameter indicates the value that will first cause DPF regeneration in aftertreatment 1. There may be multiple parameters that cause DPF regeneration (e.g…";
CM_ SG_ 2566749182 Atttt1DsPttFtTSLstAtvRt "Indicates the time since the last active regeneration event of diesel particulate filter 1.…";
CM_ BO_ 2566749438 "Diesel Particulate Filter Control 1";
CM_ SG_ 2566749438 AftrtrtmntDslPrtltFltrStts "Indicates the state of the diesel particulate filter regeneration need and urgency.  This is an aggregate of bank 1 and bank 2.  It is a system status and not i…";
CM_ SG_ 2566749438 Atttt1DsPttFtCdtsNtMtAtvRt "Indicates that diesel particulate filter 1 is not able to begin or continue an active regenerate event at the current engine operating conditions.00b = active D…";
CM_ SG_ 2566749438 AttttDsPttFtAtvRtStts "Indicates the state of diesel particulate filter active regeneration.  This is an aggregate of bank 1 and bank 2.  It is a system status and not individual bank…";
CM_ SG_ 2566749438 AttttDsPttFtPssvRtStts "Indicates the state of diesel particulate filter passive regeneration.  This is an aggregate of bank 1 and bank 2.  It is a system status and not individual ban…";
CM_ SG_ 2566749438 DslPrtltFltrAtvRgnrtnAvlltStts "Indicates that diesel particulate filter active regeneration is available for initiation through Aftertreatment Regeneration Force Switch (SPN 3696).00b = Not r…";
CM_ SG_ 2566749438 DslPrtltFltrAtvRgnrtnFrdStts "Indicates the forced execution status of diesel particulate filter regeneration.000b = Not Active001b = Active – Forced by Switch (See SPN 3696)010b = Active – …";
CM_ SG_ 2566749438 DslPrtltFltrAtvRgnrtnInhtdStts "Indicates the state of diesel particulate filter active regeneration inhibition.00b = not inhibited01b = inhibited10b = reserved for SAE assignment11b = not ava…";
CM_ SG_ 2566749438 DslPrtltFltrLmpCmmnd "Command to control the diesel particulate filter lamp.000b = Off001b = On – solid010b = reserved for SAE assignment 011b = reserved for SAE assignment100b = On …";
CM_ SG_ 2566749438 DsPttFtAttAtvRtIttCt "Indicates the configuration of diesel particulate filter active regeneration automatic initiation.00b = not enabled01b = enabled10b = reserved for SAE assignmen…";
CM_ SG_ 2566749438 DsPttFtAtvRtItdDtAtPdOId "Indicates the state of diesel particulate filter active regeneration inhibition due to the accelerator pedal being off idle.00b = not inhibited01b = inhibited10…";
CM_ SG_ 2566749438 DsPttFtAtvRtItdDtCtDsd "Indicates the state of diesel particulate filter active regeneration inhibition due to the clutch being disengaged.00b = not inhibited01b = inhibited10b = reser…";
CM_ SG_ 2566749438 DsPttFtAtvRtItdDtENtWdUp "Indicates the state of diesel particulate filter active regeneration inhibition due to the engine not being warmed up.00b = not inhibited01b = inhibited10b = re…";
CM_ SG_ 2566749438 DsPttFtAtvRtItdDtItSwt "Indicates the state of diesel particulate filter active regeneration inhibition due to the Diesel Particulate Filter Regeneration Inhibit Switch.00b = not inhib…";
CM_ SG_ 2566749438 DsPttFtAtvRtItdDtLwExstPss "Indicates the state of diesel particulate filter active regeneration inhibition due to low exhaust pressure.00b = not inhibited01b = inhibited10b = reserved for…";
CM_ SG_ 2566749438 DsPttFtAtvRtItdDtLwExstTpt "Indicates the state of diesel particulate filter active regeneration inhibition due to the exhaust temperature being too low.  This implies that the diesel part…";
CM_ SG_ 2566749438 DsPttFtAtvRtItdDtOtNt "Indicates the state of diesel particulate filter active regeneration inhibition due to the transmission being out of neutral.00b = not inhibited01b = inhibited1…";
CM_ SG_ 2566749438 DsPttFtAtvRtItdDtPBNtSt "Indicates the state of diesel particulate filter active regeneration inhibition due to the parking brake being not set.00b = not inhibited01b = inhibited10b = r…";
CM_ SG_ 2566749438 DsPttFtAtvRtItdDtPTOAtv "Indicates the state of diesel particulate filter active regeneration inhibition due to the PTO being active.00b = not inhibited01b = inhibited10b = reserved for…";
CM_ SG_ 2566749438 DsPttFtAtvRtItdDtPtSstLt "Indicates the state of diesel particulate filter active regeneration inhibition due to a permanent system lockout.00b = not inhibited01b = inhibited10b = reserv…";
CM_ SG_ 2566749438 DsPttFtAtvRtItdDtSstFtAtv "Indicates the state of diesel particulate filter active regeneration inhibition due to a system fault being active.00b = not inhibited01b = inhibited10b = reser…";
CM_ SG_ 2566749438 DsPttFtAtvRtItdDtSstTt "Indicates the state of diesel particulate filter active regeneration inhibition due to a system timeout.00b = not inhibited01b = inhibited10b = reserved for SAE…";
CM_ SG_ 2566749438 DsPttFtAtvRtItdDtSvBAtv "Indicates the state of diesel particulate filter active regeneration inhibition due to the service brake being active.00b = not inhibited01b = inhibited10b = re…";
CM_ SG_ 2566749438 DsPttFtAtvRtItdDtTpSstLt "Indicates the state of diesel particulate filter active regeneration inhibition due to a temporary system lockout.00b = not inhibited01b = inhibited10b = reserv…";
CM_ SG_ 2566749438 DsPttFtAtvRtItdDtVSpdAvAwdSpd "Indicates the state of diesel particulate filter active regeneration inhibition due to the vehicle speed being above an allowed limit.00b = not inhibited01b = i…";
CM_ SG_ 2566749438 DsPttFtAtvRtItdDtVSpdBwAwdSpd "Indicates the state of diesel particulate filter active regeneration inhibition due to vehicle speed being less than the allowed vehicle speed.00b = not inhibit…";
CM_ SG_ 2566749438 ExhstSstmHghTmprtrLmpCmmnd "Command to control the exhaust system high temperature lamp.  This lamp indicates that the exhaust system temperature is high.000b = Off001b = On – solid 010b =…";
CM_ SG_ 2566749438 HydrocarbonDoserPurgingEnable "Purging enable of the Hydrocarbon Doser (HCD).00b = Purging not enabled01b = Purging enabled - less urgent10b = Purging enabled - urgent11b = Not available…";
CM_ SG_ 2566749438 DsPttFtAtvRtItdDtTs "Indicates the state of diesel particulate filter active regeneration inhibition due to a combine thresher being active/engaged.This parameter indicates the reas…";
CM_ BO_ 2566749950 "Adaptive Front-Lighting System Status";
CM_ SG_ 2566749950 LeftHeadlampDynamicBendingLight "This parameter indicates whether the dynamic bending light of the left headlamp is working properly.000b = Dynamic bending light deactivated.  There is no probl…";
CM_ SG_ 2566749950 LeftHeadlampLightDistribution "This parameter indicates what kind of light distribution is set by the AFS system for the left headlamp.0000b = Light distribution town - The basic light distri…";
CM_ SG_ 2566749950 RghtHdlmpDnmBndngLght "This parameter indicates whether the dynamic bending light of the left headlamp is working properly.000b = Dynamic bending light deactivated.  There is no probl…";
CM_ SG_ 2566749950 RightHeadlampLightDistribution "This parameter indicates what kind of light distribution is set by the AFS system for the right headlamp.0000b = Light distribution town - The basic light distr…";
CM_ BO_ 2566750206 "Engine Configuration 2";
CM_ SG_ 2566750206 EngnCnfgrtnIdntftn "Used to identify the hardware configuration of engine family. Each number will have a reference to set of parameters such as, but not limited to, number of cyli…";
CM_ SG_ 2566750206 MxmmCrnkAttmptsprStrtAttmpt "The number of cranking cycles that will be performed before ending the start attempt.  This is intended to be used in conjunction with Crank Attempt Count on Pr…";
CM_ SG_ 2566750206 NmrfCmstnClsfrAvrgng "Defined number of combustion cycles used for calculating average parameters of combustion in each cylinder.…";
CM_ SG_ 2566750206 TrnsmssnIdlGvrnrFlngInhtSpprt "Companion parameter to Transmission Idle Governor Fueling Inhibit (SPN 7829). This configuration parameter provides confirmation to the Transmission that the en…";
CM_ BO_ 2566751230 "Transfer Case Information";
CM_ SG_ 2566751230 TransferCaseActualGearRatio "Actual ratio of input shaft speed to output shaft speed of the transfer case.…";
CM_ SG_ 2566751230 TransferCaseDirectionStatus "Indicates the vehicle direction capability based on the current transfer case or power shuttle state.  Such devices are typically downstream of the traditional …";
CM_ SG_ 2566751230 TransferCaseMessageChecksum "The message checksum is used to verify the signal path from the transmitting device to the receiving device. The message checksum is calculated using the first …";
CM_ SG_ 2566751230 TransferCaseMessageCounter "The message counter is used to detect situations where the transmitting ECU malfunction repeats the same frame all the time.  The receiver of the information ma…";
CM_ SG_ 2566751230 Transfercasestatus "This parameter describes the feedback from the  transfer case controller . Used by instrument clusters,  tachographs, PTOs , etc.000b = 2 wheel high (normal or …";
CM_ BO_ 2566751486 "Engine Fluid Level/Pressure 9";
CM_ SG_ 2566751486 EngnIntkVlvAttnOlPrssrfrClndr17 "The gage pressure of the oil in the hydraulic accumulator that powers the engine intake valve for cylinder #17.…";
CM_ SG_ 2566751486 EngnIntkVlvAttnOlPrssrfrClndr18 "The gage pressure of the oil in the hydraulic accumulator that powers the engine intake valve for cylinder #18.…";
CM_ SG_ 2566751486 EngnIntkVlvAttnOlPrssrfrClndr19 "The gage pressure of the oil in the hydraulic accumulator that powers the engine intake valve for cylinder #19.…";
CM_ SG_ 2566751486 EngnIntkVlvAttnOlPrssrfrClndr20 "The gage pressure of the oil in the hydraulic accumulator that powers the engine intake valve for cylinder #20.…";
CM_ BO_ 2566751742 "Engine Fluid Level/Pressure 8";
CM_ SG_ 2566751742 EngnIntkVlvAttnOlPrssrfrClndr13 "The gage pressure of the oil in the hydraulic accumulator that powers the engine intake valve for cylinder #13.…";
CM_ SG_ 2566751742 EngnIntkVlvAttnOlPrssrfrClndr14 "The gage pressure of the oil in the hydraulic accumulator that powers the engine intake valve for cylinder #14.…";
CM_ SG_ 2566751742 EngnIntkVlvAttnOlPrssrfrClndr15 "The gage pressure of the oil in the hydraulic accumulator that powers the engine intake valve for cylinder #15.…";
CM_ SG_ 2566751742 EngnIntkVlvAttnOlPrssrfrClndr16 "The gage pressure of the oil in the hydraulic accumulator that powers the engine intake valve for cylinder #16.…";
CM_ BO_ 2566751998 "Engine Fluid Level/Pressure 7";
CM_ SG_ 2566751998 EngnIntkVlvAttnOlPrssrfrClndr10 "The gage pressure of the oil in the hydraulic accumulator that powers the engine intake valve for cylinder #10.…";
CM_ SG_ 2566751998 EngnIntkVlvAttnOlPrssrfrClndr11 "The gage pressure of the oil in the hydraulic accumulator that powers the engine intake valve for cylinder #11.…";
CM_ SG_ 2566751998 EngnIntkVlvAttnOlPrssrfrClndr12 "The gage pressure of the oil in the hydraulic accumulator that powers the engine intake valve for cylinder #12.…";
CM_ SG_ 2566751998 EngnIntkVlvAttnOlPrssrfrClndr9 "The gage pressure of the oil in the hydraulic accumulator that powers the engine intake valve for cylinder #9.…";
CM_ BO_ 2566752254 "Engine Fluid Level/Pressure 6";
CM_ SG_ 2566752254 EngnIntkVlvAttnOlPrssrfrClndr5 "The gage pressure of the oil in the hydraulic accumulator that powers the engine intake valve for cylinder #5.…";
CM_ SG_ 2566752254 EngnIntkVlvAttnOlPrssrfrClndr6 "The gage pressure of the oil in the hydraulic accumulator that powers the engine intake valve for cylinder #6.…";
CM_ SG_ 2566752254 EngnIntkVlvAttnOlPrssrfrClndr7 "The gage pressure of the oil in the hydraulic accumulator that powers the engine intake valve for cylinder #7.…";
CM_ SG_ 2566752254 EngnIntkVlvAttnOlPrssrfrClndr8 "The gage pressure of the oil in the hydraulic accumulator that powers the engine intake valve for cylinder #8.…";
CM_ BO_ 2566752510 "Engine Fluid Level/Pressure 5";
CM_ SG_ 2566752510 EngnIntkVlvAttnOlPrssrfrClndr1 "The gage pressure of the oil in the hydraulic accumulator that powers the engine intake valve for cylinder #1.  This intake valve pressure is at the first cylin…";
CM_ SG_ 2566752510 EngnIntkVlvAttnOlPrssrfrClndr2 "The gage pressure of the oil in the hydraulic accumulator that powers the engine intake valve for cylinder #2.…";
CM_ SG_ 2566752510 EngnIntkVlvAttnOlPrssrfrClndr3 "The gage pressure of the oil in the hydraulic accumulator that powers the engine intake valve for cylinder #3.…";
CM_ SG_ 2566752510 EngnIntkVlvAttnOlPrssrfrClndr4 "The gage pressure of the oil in the hydraulic accumulator that powers the engine intake valve for cylinder #4.…";
CM_ BO_ 2566752766 "Vehicle Direction/Speed 2";
CM_ SG_ 2566752766 VehicleRoll "This parameter indicates the roll in degrees from level.  Facing the direction of travel a tip to the left would be indicated by a negative number and a tip to …";
CM_ BO_ 2566753278 "Aftertreatment 2 Gas Parameters";
CM_ SG_ 2566753278 Atttt2DsPttFtItPss "This parameter indicates the diesel particulate filter intake gage pressure 2 (bank 2).…";
CM_ SG_ 2566753278 Atttt2DsPttFtOttPss "This parameter indicates the diesel particulate filter outlet gage pressure 2 (bank 2).…";
CM_ BO_ 2566753534 "Aftertreatment 1 Gas Parameters";
CM_ SG_ 2566753534 Atttt1DsPttFtItPss "This parameter indicates the diesel particulate filter intake gage pressure 1 (bank 1).…";
CM_ SG_ 2566753534 Atttt1DsPttFtOttPss "This parameter indicates the diesel particulate filter outlet gage pressure 1 (bank 1).…";
CM_ BO_ 2566753790 "Utility Total AC Reactive Energy";
CM_ SG_ 2566753790 UtilityTotalkVArHoursExport "This parameter reports the cumulative total AC reactive energy exported from the utility.…";
CM_ SG_ 2566753790 UtilityTotalkVArHoursImport "This parameter reports the cumulative total AC reactive energy imported to the utility.…";
CM_ BO_ 2566754046 "Generator Total AC Reactive Energy";
CM_ SG_ 2566754046 GeneratorTotalkVArHoursExport "This parameter reports the cumulative total AC reactive energy exported from the generator.…";
CM_ SG_ 2566754046 GeneratorTotalkVArHoursImport "This parameter reports the cumulative total AC reactive energy imported to the generator.…";
CM_ BO_ 2566754302 "Generator Total AC Percent Power";
CM_ SG_ 2566754302 GeneratorTotalPercentkVA "This parameter reports the generator total AC apparent power, as a percentage of rated power.…";
CM_ SG_ 2566754302 GeneratorTotalPercentkVAr "This parameter reports the generator total AC reactive power, as a percentage of rated power.…";
CM_ SG_ 2566754302 GeneratorTotalPercentkW "This parameter reports the generator total AC power, as a percentage of rated power.…";
CM_ BO_ 2566754814 "AC Switching Device Status";
CM_ SG_ 2566754814 AutomaticTransferSwitchStatus "This parameter indicates the measured state of the automatic transfer switch.000b = Normal position001b = Emergency position010b = Available for SAE assignment0…";
CM_ SG_ 2566754814 BusTieBreaker1 "The measured state of first tie breaker on the electrical power bus.000b = Open001b = Closed010b = Locked Out011b = Transitioning to Open state100b = Transition…";
CM_ SG_ 2566754814 BusTieBreaker2 "The measured state of second tie breaker on the electrical power bus.000b = Open001b = Closed010b = Locked Out011b = Transitioning to Open state100b = Transitio…";
CM_ SG_ 2566754814 EngineLoadGroup "The engine load group for the reporting engine. An Engine Load Group is a set of engines tied together for sharing the electrical power bus load. Load Group ass…";
CM_ SG_ 2566754814 EngineSpeedGovernorMode "Indicates the engine speed governor operating mode.00b = Isochronous Mode01b = Droop Mode10b = Error11b = Not Available…";
CM_ SG_ 2566754814 GeneratorCircuitBreakerStatus "This parameter indicates the measured state of the generator circuit breaker.000b = Open001b = Closed010b = Locked Out011b = Transitioning to Open state100b = T…";
CM_ SG_ 2566754814 UtilityCircuitBreakerStatus "This parameter indicates the measured state of the utility circuit breaker.000b = Open001b = Closed010b = Locked Out011b = Transitioning to Open state100b = Tra…";
CM_ SG_ 2566754814 PackageCircuitBreakerStatus "The state of the package circuit breaker.Generic circuit breaker for various applications.000b = Open001b = Closed010b = Locked Out011b = Transitioning to Open …";
CM_ SG_ 2566754814 SttnrInvrtrCrtBrkrStts "The state of the inverter circuit breaker.For stationary non-vehicular applications of inverters.000b = Open001b = Closed010b = Locked Out011b = Transitioning t…";
CM_ BO_ 2566755582 "Electronic Engine Controller 7";
CM_ SG_ 2566755582 EngnCrnksBrthrOlSprtrSpd "The speed of a rotating (centrifugal) crankcase oil separator.…";
CM_ SG_ 2566755582 EngnExhstGsRrltn1Vlv2Pstn "The position of the second exhaust gas recirculation valve expressed as a percentage of full travel. Zero percent means the valve is closed and no exhaust gas i…";
CM_ SG_ 2566755582 EngnExhstGsRrltn1VlvPstn "The position of the exhaust gas recirculation valve expressed as a percentage of full travel. Zero percent means the valve is closed and no exhaust gas is flowi…";
CM_ SG_ 2566755582 EngnIntkMnfldCmmnddPrssr "Provides the commanded set point value for the engine intake manifold pressure.…";
CM_ BO_ 2566755838 "Transmission Fluids 2";
CM_ SG_ 2566755838 TransmissionOilLevel2HighLow "Second instance of a transmission oil level indicator. Conveys the current volume of transmission sump oil compared to recommended volume. Positive values indic…";
CM_ SG_ 2566755838 TransmissionOilLevelSwitch "This switch indicates whether transmission oil level is full or empty.00b = Empty01b = Full or not empty10b = Error11b = Not available…";
CM_ SG_ 2566755838 TransmissionOilLifeRemaining "Signal which indicates the actual oil life remaining in percent.  100% means the transmission oil is brand new, and 0% means the transmission oil is at the end …";
CM_ SG_ 2566755838 TransmissionOilTemperature2 "Second instance of transmission lubricant temperature. This parameter may reflect the temperature of a second sump or oil supply. If only one instance of transm…";
CM_ SG_ 2566755838 TransmissionOverheatIndicator "Signal from transmission indicating that its fluid temperature is above normal acceptable limits, and as a result, transmission operation may be altered or rest…";
CM_ SG_ 2566755838 TrnsmssnOlFltrRstrtnSwth "This switch indicates whether the transmission oil filter is clogged.00b = No restriction01b = Restriction exists on oil filter10b = Error11b = Not available…";
CM_ SG_ 2566755838 TrnsmssnOlLvl2CntdwnTmr "Countdown timer for the second instance of a transmission oil level indicator. Once all vehicle conditions (such as vehicle stopped, etc) are met, some transmis…";
CM_ SG_ 2566755838 TrnsmssnOlLvl2MsrmntStts "Measurement status for the second instance of a transmission oil level indicator. Indicates if conditions are acceptable to obtain a valid transmission oil leve…";
CM_ SG_ 2566755838 TrnsmssnTrqCnvrtrOlOtltTmprtr "Temperature of transmission torque converter outlet oil.…";
CM_ BO_ 2566756094 "Fuel Information 2 (Liquid)";
CM_ SG_ 2566756094 EngineFuelReturnFlowRate "The rate of fuel flowing through a fuel return line carrying fuel from the engine back to fuel tank.…";
CM_ SG_ 2566756094 EngineFuelSupplyFlowRate "The rate of fuel flowing through a fuel supply line carrying fuel from the fuel tank to the engine.…";
CM_ BO_ 2566756350 "Fuel Information 3 (Liquid)";
CM_ SG_ 2566756350 EngineFuelReturnTemperature "The temperature of the fuel flowing through a fuel return line from the engine back to the fuel tank.…";
CM_ SG_ 2566756350 EngineFuelSupplyTemperature "The temperature of the fuel flowing through a fuel supply line from the fuel tank to the engine.…";
CM_ BO_ 2566756606 "Aftertreatment 1 Historical Information 1";
CM_ SG_ 2566756606 Aftertreatment1TotalFuelUsed "Total amount of fuel used by aftertreatment device 1 over the lifetime of the device.…";
CM_ SG_ 2566756606 Aftrtrtmnt1TtlDsldTm "Total amount of time that aftertreatment 1 regeneration has been manually disabled.…";
CM_ SG_ 2566756606 Aftrtrtmnt1TtlNmrfAtvRgnrtns "Total number of active regenerations by aftertreatment device 1 over the lifetime of the device.…";
CM_ SG_ 2566756606 Aftrtrtmnt1TtlRgnrtnTm "Total amount of time that aftertreatment device 1 has been regenerating over the lifetime of the device.…";
CM_ SG_ 2566756606 Atttt1DsPttFtAvDstBtwAtvRts "Indicates the average distance since last reset between active regenerations, that have not been forced to occur by manual request, for aftertreatment device 1.…";
CM_ SG_ 2566756606 Atttt1DsPttFtAvTBtwAtvRts "Indicates the average time since last reset between active regenerations, that have not been forced to occur by manual request, for Aftertreatment device 1.If t…";
CM_ SG_ 2566756606 Atttt1DsPttFtTtNAtvRtItRqsts "Total number of aftertreatment device 1 active regeneration inhibit requests by the operator over the lifetime of the device.…";
CM_ SG_ 2566756606 Atttt1DsPttFtTtNAtvRtMRqsts "Total number of aftertreatment device 1 active regeneration manual requests by the operator over the lifetime of the device.…";
CM_ SG_ 2566756606 Atttt1DsPttFtTtNPssvRts "Total number of passive regenerations by aftertreatment device 1 over the lifetime of the device.…";
CM_ SG_ 2566756606 Atttt1DsPttFtTtPssvRtT "Total amount of time that aftertreatment 1 diesel particulate filter has been in passive regeneration over the lifetime of the device.…";
CM_ BO_ 2566756862 "Aftertreatment 2 Historical information 1";
CM_ SG_ 2566756862 Aftertreatment2TotalFuelUsed "Total amount of fuel used by aftertreatment device 2 over the lifetime of the device.…";
CM_ SG_ 2566756862 Aftrtrtmnt2TtlDsldTm "Total amount of time that aftertreatment 2 regeneration has been manually disabled.…";
CM_ SG_ 2566756862 Aftrtrtmnt2TtlNmrfAtvRgnrtns "Total number of active regenerations by aftertreatment device 2 over the lifetime of the device.…";
CM_ SG_ 2566756862 Aftrtrtmnt2TtlRgnrtnTm "Total amount of time that aftertreatment device 2 has been regenerating over the lifetime of the device.…";
CM_ SG_ 2566756862 Atttt2DsPttFtAvDstBtwAtvRts "Indicates the average distance since last reset between active regenerations, that have not been forced to occur by manual request, for aftertreatment device 2.…";
CM_ SG_ 2566756862 Atttt2DsPttFtAvTBtwAtvRts "Indicates the average time since last reset between active regenerations, that have not been forced to occur by manual request, for Aftertreatment device 2.…";
CM_ SG_ 2566756862 Atttt2DsPttFtTtNAtvRtItRqsts "Total number of Aftertreatment device 2 active regeneration inhibit requests by the operator over the lifetime of the device.…";
CM_ SG_ 2566756862 Atttt2DsPttFtTtNAtvRtMRqsts "Total number of Aftertreatment device 2 active regeneration manual requests by the operator over the lifetime of the device.…";
CM_ SG_ 2566756862 Atttt2DsPttFtTtNPssvRts "Total number of passive regenerations by Aftertreatment device 2 over the lifetime of the device.…";
CM_ SG_ 2566756862 Atttt2DsPttFtTtPssvRtT "Total amount of time that Aftertreatment device 2 has been in passive regeneration over the lifetime of the device.…";
CM_ BO_ 2566757374 "Aftertreatment 1 Diesel Exhaust Fluid Information 1";
CM_ SG_ 2566757374 Aftrtrtmnt1DslExhstFldCndtvt "A measure of the conductivity of the diesel exhaust fluid at the sensor.  The conductivity is an indication of the diesel exhaust fluid's chemical make up.…";
CM_ SG_ 2566757374 Aftrtrtmnt1DslExhstFldCnntrtn "A measure of the concentration of urea in water.  Zero percent means that the tank contains no urea.  A 32.5% value indicates that the diesel exhaust fluid is o…";
CM_ SG_ 2566757374 Aftrtrtmnt1DslExhstFldPrprt "This parameter indicates the property of the fluid compound in the tank.  A value of 0011b indicates uncontaminated Diesel Exhaust Fluid.0000b = Urea concentrat…";
CM_ SG_ 2566757374 Aftrtrtmnt1DslExhstFldTmprtr2 "Temperature of the diesel exhaust fluid at the device measuring diesel exhaust fluid quality…";
CM_ SG_ 2566757374 Atttt1DsExstFdPptsPFMI "Used to identify the applicable J1939-73 FMI that applies to the most significant failure of the diesel exhaust fluid properties sensor.  This may be used for i…";
CM_ SG_ 2566757374 Atttt1DsExstFdTpt2PFMI "Used to identify the applicable J1939-73 FMI that applies to the most significant failure of the diesel exhaust fluid temperature sensor.  In the case of multip…";
CM_ SG_ 2566757374 DieselExhaustFluidSpeedofSound "The speed of sound in the fluid that is in the diesel exhaust fluid tank.…";
CM_ BO_ 2566757630 "Sensor Electrical Power #2";
CM_ SG_ 2566757630 Sensorsupplyvoltage5 "Sensor ECU supply voltage 5…";
CM_ SG_ 2566757630 Sensorsupplyvoltage6 "Sensor ECU supply voltage 6…";
CM_ SG_ 2566757630 Sensorsupplyvoltage7 "Sensor ECU supply voltage 7…";
CM_ SG_ 2566757630 Sensorsupplyvoltage8 "Sensor ECU supply voltage 8…";
CM_ BO_ 2566757886 "Sensor Electrical Power #1";
CM_ SG_ 2566757886 Sensorsupplyvoltage1 "Sensor ECU supply voltage 1…";
CM_ SG_ 2566757886 Sensorsupplyvoltage2 "Sensor ECU supply voltage 2…";
CM_ SG_ 2566757886 Sensorsupplyvoltage3 "Sensor ECU supply voltage 3…";
CM_ SG_ 2566757886 Sensorsupplyvoltage4 "Sensor ECU supply voltage 4…";
CM_ BO_ 2566758142 "Aftertreatment 2 Air Control 1";
CM_ SG_ 2566758142 Aftertreatment2AirSystemRelay "Indicates whether aftertreatment 2 air system relay is on or off00b = not active01b = active10b = reserved for SAE assignment11b = not available…";
CM_ SG_ 2566758142 Aftertreatment2PurgeAirActuator "Indicates whether aftertreatment 2 purge air actuator is on or off00b = not active01b = active10b = reserved for SAE assignment11b = not available…";
CM_ SG_ 2566758142 Aftertreatment2PurgeAirPressure "Pressure of the purge air supply for aftertreatment 2…";
CM_ SG_ 2566758142 Aftrtrtmnt2ArEnlAttr "Indicates whether aftertreatment 2 air enable actuator is on or off00b = not active01b = active10b = reserved for SAE assignment11b = not available…";
CM_ SG_ 2566758142 Aftrtrtmnt2ArPrssrAttrPstn "Position of the aftertreatment 2 air pressure actuator as measured by a position feedback sensor.…";
CM_ SG_ 2566758142 Aftrtrtmnt2ArPrssrCntrl "Position that the controller is commanding the aftertreatment 2 air pressure control to maintain.  0% = fully closed, 100% = fully open…";
CM_ SG_ 2566758142 Aftrtrtmnt2AtmztnArAttr "Indicates whether aftertreatment 2 atomization air actuator is on or off00b = not active01b = active10b = reserved for SAE assignment11b = not available…";
CM_ SG_ 2566758142 Aftrtrtmnt2SpplArPrssr "Pressure of the supply air for aftertreatment 2.  Supply air is the air supplied from a pneumatic line for an air-assisted or pneumatic actuator.  One example i…";
CM_ BO_ 2566758398 "Aftertreatment 1 Air Control 1";
CM_ SG_ 2566758398 Aftertreatment1AirSystemRelay "Indicates whether aftertreatment 1 air system relay is on or off00b = not active01b = active10b = reserved for SAE assignment11b = not available…";
CM_ SG_ 2566758398 Aftertreatment1PurgeAirActuator "Indicates whether aftertreatment 1 purge air actuator is on or off00b = not active01b = active10b = reserved for SAE assignment11b = not available…";
CM_ SG_ 2566758398 Aftertreatment1PurgeAirPressure "Pressure of the purge air supply for aftertreatment 1…";
CM_ SG_ 2566758398 Aftrtrtmnt1ArEnlAttr "Indicates whether aftertreatment 1 air enable actuator is on or off00b = not active01b = active10b = reserved for SAE assignment11b = not available…";
CM_ SG_ 2566758398 Aftrtrtmnt1ArPrssrAttrPstn "Position of the aftertreatment 1 air pressure actuator as measured by a position feedback sensor.…";
CM_ SG_ 2566758398 Aftrtrtmnt1ArPrssrCntrl "Position that the controller is commanding the aftertreatment 1 air pressure control to maintain.  0% = fully closed, 100% = fully open…";
CM_ SG_ 2566758398 Aftrtrtmnt1AtmztnArAttr "Indicates whether aftertreatment 1 atomization air actuator is on or off00b = not active01b = active10b = reserved for SAE assignment11b = not available…";
CM_ SG_ 2566758398 Aftrtrtmnt1SpplArPrssr "Pressure of the supply air for aftertreatment 1.  Supply air is the air supplied from a pneumatic line for an air-assisted or pneumatic actuator.  One example i…";
CM_ BO_ 2566758654 "Aftertreatment 2 Fuel Control 1";
CM_ SG_ 2566758654 Aftertreatment2FuelPressure1 "Pressure of the fuel for Aftertreatment 2.…";
CM_ SG_ 2566758654 Aftertreatment2FuelRate "Rate of fuel being delivered to aftertreatment 2 for regeneration…";
CM_ SG_ 2566758654 Aftertreatment2Ignition "Indicates whether aftertreatment 2 ignition circuit is energized by the ECU.00b = not active01b = active10b = reserved for SAE assignment11b = not available…";
CM_ SG_ 2566758654 Aftrtrtmnt2FlDrnAttr "Indicates whether aftertreatment 2 fuel drain actuator is on or off00b = not active01b = active10b = reserved for SAE assignment11b = not available…";
CM_ SG_ 2566758654 Aftrtrtmnt2FlEnlAttr "Indicates whether aftertreatment 2 fuel enable actuator is on or off00b = not active01b = active10b = reserved for SAE assignment11b = not available…";
CM_ SG_ 2566758654 Aftrtrtmnt2FlInjtr1HtrCntrl "Heating level that the controller is commanding the aftertreatment 2 fuel injector 1 heater control to maintain. 0% = off, 100% = maximum.…";
CM_ SG_ 2566758654 Aftrtrtmnt2FlPrssr1Cntrl "Position that the controller is commanding the aftertreatment 2 fuel pressure control to maintain.  0% = fully closed, 100% = fully open.…";
CM_ SG_ 2566758654 Aftrtrtmnt2RgnrtnStts "Indicates whether regeneration is active or inactive in aftertreatment 2.  00b = not active01b = active10b = reserved for SAE assignment11b = not available…";
CM_ BO_ 2566758910 "Aftertreatment 1 Fuel Control 1";
CM_ SG_ 2566758910 Aftertreatment1FuelPressure1 "First fuel pressure measurement for the aftertreatment 1 system…";
CM_ SG_ 2566758910 Aftertreatment1FuelRate "Rate of fuel being delivered to aftertreatment 1 for regeneration…";
CM_ SG_ 2566758910 Aftertreatment1Ignition "Indicates whether aftertreatment 1 ignition circuit is energized by the ECU.00b = not active01b = active10b = reserved for SAE assignment11b = not available…";
CM_ SG_ 2566758910 Aftrtrtmnt1FlDrnAttr "Indicates whether aftertreatment 1 fuel drain actuator is on or off00b = not active01b = active10b = reserved for SAE assignment11b = not available…";
CM_ SG_ 2566758910 Aftrtrtmnt1FlEnlAttr "Indicates whether aftertreatment 1 fuel enable actuator is on or off00b = not active01b = active10b = reserved for SAE assignment11b = not available…";
CM_ SG_ 2566758910 Aftrtrtmnt1FlInjtr1HtrCntrl "Heating level that the controller is commanding the aftertreatment 1 fuel injector 1 heater control to maintain. 0% = off, 100% = maximum.…";
CM_ SG_ 2566758910 Aftrtrtmnt1FlPrssr1Cntrl "Position that the controller is commanding the aftertreatment 1 fuel pressure control to maintain.  0% = fully closed, 100% = fully open.…";
CM_ SG_ 2566758910 Aftrtrtmnt1RgnrtnStts "Indicates whether regeneration is active or inactive in aftertreatment 1.  00b = not active01b = active10b = reserved for SAE assignment11b = not available…";
CM_ BO_ 2566759678 "PTO Drive Engagement";
CM_ SG_ 2566759678 AtleastonePTOengaged "Indicates that at least one PTO is engaged00b = No PTO drive is engaged01b = At least one PTO drive is engaged10b = Error11b = Not availableNote:  This paramete…";
CM_ SG_ 2566759678 EnableSwitchPTOEngineFlywheel "Status of the PTO Engine Flywheel enable switch00b = Enable switch off – PTO operation not desired01b = Enable switch on – PTO operation desired 10b = Error11b …";
CM_ SG_ 2566759678 EnggmntCnsntPTOEngnAssrDrv1 "Engagement consent status for the PTO engine accessory drive 100b = Consent not given – PTO drive may not be engaged01b = Consent given – PTO drive may be engag…";
CM_ SG_ 2566759678 EnggmntCnsntPTOEngnAssrDrv2 "Engagement Consent status for the PTO engine accessory drive 2 00b = Consent not given – PTO drive may not be engaged01b = Consent given – PTO drive may be enga…";
CM_ SG_ 2566759678 EnggmntCnsntPTOEngnFlwhl "Engagement Consent status for the PTO Engine Flywheel00b = Consent not given – PTO drive may not be engaged01b = Consent given – PTO drive may be engaged10b = E…";
CM_ SG_ 2566759678 EnggmntSttsPTOEngnAssrDrv1 "Engagement status of the PTO engine accessory drive 100b = Drive not engaged01b = Drive engaged10b = Error11b = Not available…";
CM_ SG_ 2566759678 EnggmntSttsPTOEngnAssrDrv2 "Engagement status of the PTO engine accessory drive 200b = Drive not engaged01b = Drive engaged10b = Error11b = Not available…";
CM_ SG_ 2566759678 EnggmntSttsPTOEngnFlwhl "Engagement status of the PTO Engine Flywheel00b = Drive not engaged01b = Drive engaged10b = Error11b = Not available…";
CM_ SG_ 2566759678 EnlSwthPTOEngnAssrDrv1 "Status of the PTO engine accessory drive 1 enable switch00b = Enable switch off – PTO operation not desired01b = Enable switch on – PTO operation desired10b = E…";
CM_ SG_ 2566759678 EnlSwthPTOEngnAssrDrv2 "Status of the PTO engine accessory drive 2 enable switch00b = Enable switch off – PTO operation not desired01b = Enable switch on – PTO operation desired10b = E…";
CM_ SG_ 2566759678 EnlSwthTrnsfrstptshftPTO "Status of the operator's switch or other input which indicates the desire for engaging the PTO drive mounted on the output shaft of the transfer case. 00b = Ena…";
CM_ SG_ 2566759678 EnlSwthTrnsmssntptshftPTO "Status of the operator's switch or other input which indicates the desire for engaging the PTO drive mounted on the transmission output shaft. 00b = Enable swit…";
CM_ SG_ 2566759678 EnlSwthTrnsmssnnptshftPTO2 "Status of the operator's switch or other input which indicates the desire for engaging the second PTO drive mounted on the transmission case.   If there is only…";
CM_ SG_ 2566759678 EnlSwthTrnsmssnnptshftPTO1 "Status of the operator's switch or other input which indicates the desire for engaging the first PTO drive mounted on the transmission case.  There may be more …";
CM_ SG_ 2566759678 EnggmntCnsntTrnsfrstptshftPTO "Status of the transmission controller's consent to engage the PTO drive connected to the transfer case output shaft.  The controller in charge of the PTO drive …";
CM_ SG_ 2566759678 EnggmntCnsntTrnsmssntptshftPTO "Status of the transmission controller's consent to engage the PTO drive connected to the transmission output shaft.  The controller in charge of the PTO drive s…";
CM_ SG_ 2566759678 EnggmntCnsntTrnsmssnnptshftPTO2 "Status of the transmission controller's consent to engage the second PTO drive mounted on the transmission case.  The controller in charge of the PTO drive shou…";
CM_ SG_ 2566759678 EnggmntCnsntTrnsmssnnptshftPTO1 "Status of the transmission controller's consent to engage the first or sole PTO drive mounted on the transmission case.  The controller in charge of the PTO dri…";
CM_ SG_ 2566759678 EnggmntSttsTrnsfrstptshftPTO "Reports if this specific PTO drive is engaged.  This parameter should be broadcast only by the controller(s) receiving feedback about the specific drive.  For e…";
CM_ SG_ 2566759678 EnggmntSttsTrnsmssntptshftPTO "Reports if this specific PTO drive is engaged.  This parameter should be broadcast only by the controller(s) receiving feedback about the specific drive.  For e…";
CM_ SG_ 2566759678 EnggmntSttsTrnsmssnnptshftPTO2 "Reports if this specific PTO drive is engaged.  This parameter should be broadcast only by the controller(s) receiving feedback about the specific drive.  For e…";
CM_ SG_ 2566759678 EnggmntSttsTrnsmssnnptshftPTO1 "Reports if this specific PTO drive is engaged.  This parameter should be broadcast only by the controller(s) receiving feedback about the specific drive.  For e…";
CM_ BO_ 2566759934 "Door Control 2";
CM_ SG_ 2566759934 EnableStatusofDoor1 "Enable status of bus door 1.  Enabled means the bus doors are able to be automatically opened or closed.00b = door disabled01b = door enabled10b = error11b = no…";
CM_ SG_ 2566759934 EnableStatusofDoor10 "Enable status of bus door 10.  Enabled means the bus doors are able to be automatically opened or closed.00b = door disabled01b = door enabled10b = error11b = n…";
CM_ SG_ 2566759934 EnableStatusofDoor2 "Enable status of bus door 2.  Enabled means the bus doors are able to be automatically opened or closed.00b = door disabled01b = door enabled10b = error11b = no…";
CM_ SG_ 2566759934 EnableStatusofDoor3 "Enable status of bus door 3.  Enabled means the bus doors are able to be automatically opened or closed.00b = door disabled01b = door enabled10b = error11b = no…";
CM_ SG_ 2566759934 EnableStatusofDoor4 "Enable status of bus door 4.  Enabled means the bus doors are able to be automatically opened or closed.00b = door disabled01b = door enabled10b = error11b = no…";
CM_ SG_ 2566759934 EnableStatusofDoor5 "Enable status of bus door 5.  Enabled means the bus doors are able to be automatically opened or closed.00b = door disabled01b = door enabled10b = error11b = no…";
CM_ SG_ 2566759934 EnableStatusofDoor6 "Enable status of bus door 6.  Enabled means the bus doors are able to be automatically opened or closed.00b = door disabled01b = door enabled10b = error11b = no…";
CM_ SG_ 2566759934 EnableStatusofDoor7 "Enable status of bus door 7.  Enabled means the bus doors are able to be automatically opened or closed.00b = door disabled01b = door enabled10b = error11b = no…";
CM_ SG_ 2566759934 EnableStatusofDoor8 "Enable status of bus door 8.  Enabled means the bus doors are able to be automatically opened or closed.00b = door disabled01b = door enabled10b = error11b = no…";
CM_ SG_ 2566759934 EnableStatusofDoor9 "Enable status of bus door 9.  Enabled means the bus doors are able to be automatically opened or closed.00b = door disabled01b = door enabled10b = error11b = no…";
CM_ SG_ 2566759934 LockStatusofDoor1 "Lock status of bus door 100b = unlocked 01b = locked10b = error11b = not available…";
CM_ SG_ 2566759934 LockStatusofDoor10 "Lock status of bus door 1000b = unlocked 01b = locked10b = error11b = not available…";
CM_ SG_ 2566759934 LockStatusofDoor2 "Lock status of bus door 200b = unlocked 01b = locked10b = error11b = not available…";
CM_ SG_ 2566759934 LockStatusofDoor3 "Lock status of bus door 300b = unlocked 01b = locked10b = error11b = not available…";
CM_ SG_ 2566759934 LockStatusofDoor4 "Lock status of bus door 400b = unlocked 01b = locked10b = error11b = not available…";
CM_ SG_ 2566759934 LockStatusofDoor5 "Lock status of bus door 500b = unlocked 01b = locked10b = error11b = not available…";
CM_ SG_ 2566759934 LockStatusofDoor6 "Lock status of bus door 600b = unlocked 01b = locked10b = error11b = not available…";
CM_ SG_ 2566759934 LockStatusofDoor7 "Lock status of bus door 700b = unlocked 01b = locked10b = error11b = not available…";
CM_ SG_ 2566759934 LockStatusofDoor8 "Lock status of bus door 800b = unlocked 01b = locked10b = error11b = not available…";
CM_ SG_ 2566759934 LockStatusofDoor9 "Lock status of bus door 900b = unlocked 01b = locked10b = error11b = not available…";
CM_ SG_ 2566759934 OpenStatusofDoor1 "Open status of bus door 100b = door closed01b = door opened10b = error11b = not available…";
CM_ SG_ 2566759934 OpenStatusofDoor10 "Open status of bus door 1000b = door closed01b = door opened10b = error11b = not available…";
CM_ SG_ 2566759934 OpenStatusofDoor2 "Open status of bus door 200b = door closed01b = door opened10b = error11b = not available…";
CM_ SG_ 2566759934 OpenStatusofDoor3 "Open status of bus door 300b = door closed01b = door opened10b = error11b = not available…";
CM_ SG_ 2566759934 OpenStatusofDoor4 "Open status of bus door 400b = door closed01b = door opened10b = error11b = not available…";
CM_ SG_ 2566759934 OpenStatusofDoor5 "Open status of bus door 500b = door closed01b = door opened10b = error11b = not available…";
CM_ SG_ 2566759934 OpenStatusofDoor6 "Open status of bus door 600b = door closed01b = door opened10b = error11b = not available…";
CM_ SG_ 2566759934 OpenStatusofDoor7 "Open status of bus door 700b = door closed01b = door opened10b = error11b = not available…";
CM_ SG_ 2566759934 OpenStatusofDoor8 "Open status of bus door 800b = door closed01b = door opened10b = error11b = not available…";
CM_ SG_ 2566759934 OpenStatusofDoor9 "Open status of bus door 900b = door closed01b = door opened10b = error11b = not available…";
CM_ BO_ 2566760702 "Wireless Communications Message 2";
CM_ SG_ 2566760702 NetworkAntennaStatus2 "Indicates the status of the antenna for the wireless communications network type0 = Off1 = On2 to 250 = Reserved for Future Assignment251 to 253 = Reserved254 =…";
CM_ SG_ 2566760702 NetworkServiceStatus2 "Indicates the status of the Service for the wireless communications network type0 = Local Service1 = Roaming Service2 = Service not available3 = Not Authorized …";
CM_ SG_ 2566760702 NetworkSignalStrength2 "Indicates the signal strength for the wireless communications network type.…";
CM_ SG_ 2566760702 NetworkTransceiverStatus2 "Indicates the status of the transceiver for the wireless communications network type0 = Off1 = On2 = Not Authorized to Operate on Network3 to 250 = Reserved for…";
CM_ SG_ 2566760702 WrlssCmmntnNtwrkTp2 "Type of Wireless Communication Network0 = Cellular network #11 = Cellular network #22 = Wireless LAN #13 = Wireless LAN #24 = Satellite network5 to 250 = Reserv…";
CM_ BO_ 2566760958 "Wireless Communications Message 1";
CM_ SG_ 2566760958 NetworkAntennaStatus1 "Indicates the status of the antenna for the wireless communications network type0 = Off1 = On2 to 250 = Reserved for Future Assignment251 to 253 = Reserved254 =…";
CM_ SG_ 2566760958 NetworkServiceStatus1 "Indicates the status of the Service for the wireless communications network type0 = Local Service1 = Roaming Service2 = Service not available3 = Not Authorized …";
CM_ SG_ 2566760958 NetworkSignalStrength1 "Indicates the signal strength for the wireless communications network type.…";
CM_ SG_ 2566760958 NetworkTransceiverStatus1 "Indicates the status of the transceiver for the wireless communications network type0 = Off1 = On2 = Not Authorized to Operate on Network3 to 250 = Reserved for…";
CM_ SG_ 2566760958 WrlssCmmntnNtwrkTp1 "Type of Wireless Communication Network0 = Cellular network #11 = Cellular network #22 = Wireless LAN #13 = Wireless LAN #24 = Satellite network5 to 250 = Reserv…";
CM_ BO_ 2566761214 "Engine Fluid Level/Pressure 4";
CM_ SG_ 2566761214 EngineAftercoolerCoolantLevel "Ratio of aftercooler coolant system volume of liquid to total cooling system volume.  The engine aftercooler coolant level is for  the low temperature (LT) cool…";
CM_ SG_ 2566761214 EngineCentrifugalOilFilterspeed "The speed of a rotating (centrifugal) engine oil filter.…";
CM_ SG_ 2566761214 EngnChrgArClr1IntkPrssr "Pressure of air at intake to 1st or only charge air cooler, from multiple first stage turbochargers being cooled and feeding multiple second stage turbochargers…";
CM_ SG_ 2566761214 EngnChrgArClr2IntkPrssr "Pressure of air at intake to 2nd charge air cooler, from multiple first stage turbochargers being cooled and feeding multiple second stage turbochargers.…";
CM_ SG_ 2566761214 EngnChrgArClrClntLvl "Ratio of volume of liquid found in an engine charge air cooler cooling system to total engine charge air cooler cooling system volume.…";
CM_ SG_ 2566761214 EngnChrgArClrOtltPrssr "Measures pressure of air at outlet from charge air cooler…";
CM_ SG_ 2566761214 EngnClntPmpDffrntlPrssr "The differential pressure measured across the input and output of the engine coolant pump.…";
CM_ BO_ 2566761726 "Engine Fuel Information";
CM_ SG_ 2566761726 EngineIdleFuelFlowRateThreshold "A configuration value that indicates the maximum flow rate for engine idle operation.…";
CM_ SG_ 2566761726 NmrfFlCnsmptnMntrngTrnsdrs "The number of fuel consumption monitoring transducers installed in the fuel consumption monitoring system.…";
CM_ BO_ 2566762238 "Fifth Wheel Smart Systems 2";
CM_ SG_ 2566762238 FfthWhlLkCplSttsIndtr "Indicates results of coupling operation to the vehicle operator. For incomplete couples further information can be obtained from the fifth wheel error status SP…";
CM_ SG_ 2566762238 FfthWhlLkRdtCplIndtr "Indicates to the vehicle operator that the fifth wheel lock is open and ready to couple.00b = Lock not open, not ready to couple01b = Lock open, ready to couple…";
CM_ SG_ 2566762238 FifthWheelErrorStatus "Fifth wheel error state which conveys information when coupling status is incomplete or bad.0000b = Improper Couple0001b = Locks Closed / No Kingpin at Startup0…";
CM_ SG_ 2566762238 FifthWheelSliderLockIndicator "Indicates to vehicle operator that the fifth wheel slider is in position and locked. 00b = Not Locked01b = Locked10b = Error11b = Not Available…";
CM_ SG_ 2566762238 FifthWheelSliderPosition "Slider position measurement. Zero equals fully back position, that is, the farthest to the rear of the vehicle.…";
CM_ BO_ 2566762494 "Aftertreatment 2 Intermediate Gas";
CM_ SG_ 2566762494 Aftrtrtmnt2ExhstTmprtr2 "The reading from the exhaust temperature sensor located midstream of the other two temperature sensors in the aftertreatment system in exhaust bank 2.  (For a s…";
CM_ SG_ 2566762494 Atttt2DsPttFtDtPss "Exhaust differential pressure measured between the intake and exhaust of a diesel particulate filter in exhaust bank 2.  (For a single exhaust bank system, refe…";
CM_ SG_ 2566762494 Atttt2DsPttFtDtPssPFMI "Used to identify the applicable J1939-73 FMI detected in the diesel particulate filter differential pressure sensor by the manufacturer’s sensor control softwar…";
CM_ SG_ 2566762494 Atttt2DsPttFtItdtTpt "Temperature of engine combustion byproducts at a mid-point in the diesel particulate filter in exhaust bank 2.  (For a single exhaust bank system, refer to para…";
CM_ SG_ 2566762494 Atttt2DsPttFtItdtTptPFMI "Used to identify the applicable J1939-73 FMI detected in the diesel particulate filter intermediate temperature sensor by the manufacturer’s sensor control soft…";
CM_ SG_ 2566762494 Atttt2ExstTpt2PFMI "Used to identify the applicable J1939-73 FMI detected in the exhaust temperature 2 sensor by the manufacturer’s sensor control software in exhaust bank 2.  In t…";
CM_ BO_ 2566762750 "Aftertreatment 2 Outlet Gas 2";
CM_ SG_ 2566762750 Aftrtrtmnt2ExhstTmprtr3 "The reading from the exhaust temperature sensor located farthest downstream in the aftertreatment system in exhaust bank 2.  (For a single exhaust bank system, …";
CM_ SG_ 2566762750 Atttt2DsPttFtExstTptPFMI "Used to identify the applicable J1939-73 FMI detected in the diesel particulate filter outlet temperature sensor by the manufacturer’s sensor control software i…";
CM_ SG_ 2566762750 Atttt2DsPttFtOttTpt "Temperature of engine combustion byproducts leaving the diesel particulate filter exhaust in exhaust bank 2.  (For a single exhaust bank system, refer to parame…";
CM_ SG_ 2566762750 Atttt2ExstTpt3PFMI "Used to identify the applicable J1939-73 FMI detected in the exhaust temperature 3 sensor by the manufacturer’s sensor control software in exhaust bank 2.  In t…";
CM_ BO_ 2566763006 "Aftertreatment 2 Intake Gas 2";
CM_ SG_ 2566763006 Aftrtrtmnt2ExhstTmprtr1 "The reading from the exhaust temperature sensor located farthest upstream in the aftertreatment system in exhaust bank 2.  (For a single exhaust bank system, re…";
CM_ SG_ 2566763006 Atttt2DsPttFtItTpt "Temperature of engine combustion byproducts entering the diesel particulate filter in exhaust bank 2.  (For a single exhaust bank system, refer to parameters in…";
CM_ SG_ 2566763006 Atttt2DsPttFtItTptPFMI "Used to identify the applicable J1939-73 FMI detected in the diesel particulate filter intake temperature sensor by the manufacturer’s sensor control software i…";
CM_ SG_ 2566763006 Atttt2ExstTpt1PFMI "Used to identify the applicable J1939-73 FMI detected in the exhaust temperature 1 sensor by the manufacturer’s sensor control software in exhaust bank 2.  In t…";
CM_ BO_ 2566763262 "Aftertreatment 1 Intermediate Gas";
CM_ SG_ 2566763262 Aftrtrtmnt1ExhstTmprtr2 "The reading from the exhaust temperature sensor located midstream of the other two temperature sensors in the aftertreatment system in exhaust bank 1.…";
CM_ SG_ 2566763262 Atttt1DsPttFtDtPss "Exhaust differential pressure measured between the intake and exhaust of a diesel particulate filter in exhaust bank 1.…";
CM_ SG_ 2566763262 Atttt1DsPttFtDtPssPFMI "Used to identify the applicable J1939-73 FMI detected in the diesel particulate filter differential pressure sensor by the manufacturer’s sensor control softwar…";
CM_ SG_ 2566763262 Atttt1DsPttFtItdtTpt "Temperature of engine combustion byproducts at a mid-point in the diesel particulate filter in exhaust bank 1.…";
CM_ SG_ 2566763262 Atttt1DsPttFtItdtTptPFMI "Used to identify the applicable J1939-73 FMI detected in the diesel particulate filter intermediate temperature sensor by the manufacturer’s sensor control soft…";
CM_ SG_ 2566763262 Atttt1ExstTpt2PFMI "Used to identify the applicable J1939-73 FMI detected in the exhaust temperature 2 sensor by the manufacturer’s sensor control software in exhaust bank 1.  In t…";
CM_ BO_ 2566763518 "Aftertreatment 1 Outlet Gas 2";
CM_ SG_ 2566763518 Aftrtrtmnt1ExhstTmprtr3 "The reading from the exhaust temperature sensor located farthest downstream in the aftertreatment system in exhaust bank 1.…";
CM_ SG_ 2566763518 Atttt1DsPttFtOttExstTptPFMI "Used to identify the applicable J1939-73 FMI detected in the diesel particulate filter outlet temperature sensor by the manufacturer’s sensor control software i…";
CM_ SG_ 2566763518 Atttt1DsPttFtOttTpt "Temperature of engine combustion byproducts leaving the diesel particulate filter exhaust in exhaust bank 1.…";
CM_ SG_ 2566763518 Atttt1ExstTpt3PFMI "Used to identify the applicable J1939-73 FMI detected in the exhaust temperature 3 sensor by the manufacturer’s sensor control software in exhaust bank 1.  In t…";
CM_ BO_ 2566763774 "Aftertreatment 1 Intake Gas 2";
CM_ SG_ 2566763774 Aftrtrtmnt1ExhstTmprtr1 "The reading from the exhaust temperature sensor located farthest upstream in the aftertreatment system in exhaust bank 1.…";
CM_ SG_ 2566763774 Atttt1DsPttFtItTpt "Temperature of engine combustion byproducts entering the diesel particulate filter in exhaust bank 1.…";
CM_ SG_ 2566763774 Atttt1DsPttFtItTptPFMI "Used to identify the applicable J1939-73 FMI detected in the diesel particulate filter intake temperature sensor by the manufacturer’s sensor control software i…";
CM_ SG_ 2566763774 Atttt1ExstTpt1PFMI "Used to identify the applicable J1939-73 FMI detected in the exhaust temperature 1 sensor by the manufacturer’s sensor control software in exhaust bank 1.   In …";
CM_ BO_ 2566765054 "Tire Pressure Reference Information";
CM_ SG_ 2566765054 ReferenceTirePressure "Reference value of the tire pressure as basis for the tire pressure monitoring…";
CM_ SG_ 2566765054 TireLocation "Identifies which tire is associated with the parametric data in this PGN.The low order 4 bits represent a position number, counting left to right when facing in…";
CM_ BO_ 2566765310 "Farebox Status";
CM_ SG_ 2566765310 FareboxAlarmIdentifier "Indicates the nature of the farebox alarm condition.0000000b = Voltage dropout0000001b = Voltage restored0000010b = Probe started0000011b = Probe completed00001…";
CM_ SG_ 2566765310 FareboxEmergencyStatus "Indicates if a farebox emergency condition exists.00b = Non-emergency condition01b = Emergency condition10b = Error Condition11b = Not available…";
CM_ BO_ 2566765566 "Farebox Point of Sale";
CM_ SG_ 2566765566 FareValidity "Agency defined value indicating validity of this fare…";
CM_ SG_ 2566765566 InitialFareAgency "Identifies where the initial fare is paidNote:  The definition of the agency numbering plan shall be agreed by the operating agency and the farebox manufacturer…";
CM_ SG_ 2566765566 PassCategory "Agency defined value indicating the category of the passenger associated with this fare…";
CM_ SG_ 2566765566 PassengerType "Enumerated value representing the type/class of passenger, as defined by the agency.…";
CM_ SG_ 2566765566 PaymentDetails "Payment details.0000b = Not an upgrade0001b = Cash0010b = Token0011b = Ticket0100b = Pass0101b = Card0110b to 1010b = Reserved for assignment1011b to 1111b = Ag…";
CM_ SG_ 2566765566 RouteNumber "The route number issuing the transfer.…";
CM_ SG_ 2566765566 TransactionType "Enumerated value representing the type of transaction completed0000b = Cash0001b = Token0010b = Ticket0011b = Pass0100b = Card0101b = Permit0110b = Transfer0111…";
CM_ SG_ 2566765566 TransferSold "Indicates that a transfer was sold or issued on this transaction including its type and/or restrictions. The final definitions of the transfer issued informatio…";
CM_ SG_ 2566765566 TransferType "The kind of transfer used00000b = North00001b = South00010b = East00011b = West00100b = In00101b = Out00110b to 11111b = Agency defined…";
CM_ SG_ 2566765566 TypeofFare "Type of Fare0000b = Cash/No detail0001b = Token A0010b = Token B0011b = Ticket A0100b = Ticket B0101b = Pass A0110b = Pass B0111b to 1010b = Reserved for assign…";
CM_ SG_ 2566765566 TypeofService "The type of service provided000b = Local service001b = Express service010b to 111b = Agency defined…";
CM_ BO_ 2566765822 "Farebox Service Detail";
CM_ SG_ 2566765822 AssignedBlock "The agency defined block number for this trip…";
CM_ SG_ 2566765822 AssignedRoute "The identity number assigned to this route.Note:  This is the numerical value for the route as opposed to the Transit Assigned Route Identity (SPN 3074) which i…";
CM_ SG_ 2566765822 AssignedRun "The agency defined run number for this trip…";
CM_ SG_ 2566765822 Driversfareboxsecuritycode "Security code for the farebox, numerical only.Note:  0 = Farebox is in reporting status1 to 65535 = security code…";
CM_ SG_ 2566765822 FareboxServiceStatus "Indicates if the farebox is in or out of service.00b = Farebox out of service01b = Farebox in service10b = Error Condition11b = Not available…";
CM_ SG_ 2566765822 FarePresets "Fare Presets00000000b to 00001111b = Agency defined00010000b to 11111111b = Reserved for assignment…";
CM_ SG_ 2566765822 PatternNumber "The agency defined pattern number for this trip…";
CM_ SG_ 2566765822 TripDirection "The general direction of travel for this trip.0000b = North0001b = South0010b = East0011b = West0100b = In0101b = Out0110b to 1111b = Agency defined…";
CM_ SG_ 2566765822 TripNumber "The identity number assigned to this trip.…";
CM_ SG_ 2566765822 TripStatus "Trip Status000b = Undefined001b = Trip start010b = Trip end011b = Undefined100b = Undefined101b = Layover start110b = Layover end111b = Undefined…";
CM_ BO_ 2566766078 "Signal Preemption";
CM_ SG_ 2566766078 IntrstnPrmptnRqstRspns "Status of the intersection signal preemption00b = Message is a request directed to the emitter01b = Message is a response from the emitter10b = Error condition1…";
CM_ SG_ 2566766078 PriorityofResponseSentbyEmitter "Priority of response sent by emitter0000b = Reserved0001b = Low priority0010b = Probe priority0011b = High priority0100b to 1000b = Reserved1001b = Priority set…";
CM_ SG_ 2566766078 RangeCodeEnable "Range code enable00b = Range code not used for interleaved data01b = Range code used for interleaved data10b = Error condition11b = Not available…";
CM_ SG_ 2566766078 StrobeActivationControlStatus "Strobe activation control status00b = Deactivate strobe01b = Activate strobe10b = Error condition11b = Not availableNote: Strobe will flash if not overridden by…";
CM_ SG_ 2566766078 TransitDoorEnable "Transit door enable00b = Ignore transit door status01b = Transit door status will override strobe activation10b = Error condition11b = Not available…";
CM_ SG_ 2566766078 TransitRouteIDUsage "Transit route ID usage00b = Transit route ID not used for interleaved data01b = Transit route ID used for interleaved data (if range code not enabled)10b = Erro…";
CM_ SG_ 2566766078 VehicleID "Numerical designation of the vehicle.   65535 is used to represent the vehicle ID is not available.…";
CM_ BO_ 2566766334 "Transit Route";
CM_ SG_ 2566766334 Agency "The identity of the agency involved in this transaction…";
CM_ SG_ 2566766334 NmrftsnthTrnstAssgndBlkIdntt "Number of bytes in the Transit Assigned Block Identity.  This parameter identifies the length, in bytes, of the data in SPN 3076 (Transit Assigned Block Identit…";
CM_ SG_ 2566766334 NmrftsnthTrnstAssgndRnIdntt "Number of bytes in the Transit Assigned Run Identity.  This parameter identifies the length, in bytes, of the data in SPN 3075 (Transit Assigned Run Identity).…";
CM_ SG_ 2566766334 NmrftsnthTrnstAssgndRtIdntt "Number of bytes in the Transit Assigned Route Identity.  This parameter identifies the length, in bytes, of the data in SPN 3074 (Transit Assigned Route Identit…";
CM_ BO_ 2566766590 "Transit Milepost";
CM_ SG_ 2566766590 NmrftsnthMlpstIdntftn "Number of bytes in the Milepost Identification.  This parameter identifies the length, in bytes, of the data in SPN 509 (Milepost Identification).…";
CM_ BO_ 2566766846 "Passenger Counter";
CM_ SG_ 2566766846 PatronCount "Count of the number of passengers on a transit vehicle.  If the type of passenger count (SPN 3043) is 0, the patron count indicates the number of patrons curren…";
CM_ SG_ 2566766846 SilentAlarmStatus "Used to report silent alarm push button status.00b = Off01b = On10b = Error condition11b = Not available…";
CM_ SG_ 2566766846 TransitRunStatus "Status of the run switch for the vehicle.00b = Off01b = On10b = Error condition11b = Not available…";
CM_ SG_ 2566766846 TypeofPassengerCount "Used to notify transit link devices of the type of passenger counting system used in the vehicle.  Some passenger counting systems indicate real-time boarding a…";
CM_ SG_ 2566766846 VehicleUseStatus "Used to indicate the proper or unauthorized use of the vehicle. The administrative control device or any device issuing the vehicle use status PID should be sen…";
CM_ BO_ 2566767102 "Engine Fluid Level/Pressure 3";
CM_ SG_ 2566767102 EngnExhstGsRrltn1IntkPrssr "EGR intake gage pressure is measured after the EGR cooler and before the EGR valve.…";
CM_ SG_ 2566767102 EngnExhstGsRrltn1OtltPrssr "EGR outlet pressure is measured immediately after the EGR valve.…";
CM_ SG_ 2566767102 EngnExhstVlvAttnSstmOlPrssr "The absolute pressure of the oil in the hydraulic system that powers the engine exhaust valve actuation system…";
CM_ SG_ 2566767102 EngnIntkVlvAttnSstmOlPrssr "The gage pressure of the oil in the hydraulic system that powers the engine intake valve actuation system…";
CM_ SG_ 2566767102 EngnThrttlVlv1DffrntlPrssr "The differential pressure between the intake and outlet of the throttle valve 1 (SPN 51).  The differential pressure is measured from the intake with respect to…";
CM_ BO_ 2566767358 "Electronic Engine Controller 14";
CM_ SG_ 2566767358 EngineFuelIsolationControl "Control setting for fuel isolation. In a single injector dual fuel system when using just diesel fuel, diesel must not be allowed to migrate into the gaseous fu…";
CM_ SG_ 2566767358 EngineFuelMassFlowRate "Mass of liquid fuel consumed by engine per unit of time.…";
CM_ SG_ 2566767358 EngnExhstGsRrltn1Vlv1PstnErrr "The position error of the Exhaust Gas Recirculation 1 valve, determined as the actual position (SPN 27) minus the commanded position (SPN 2791).…";
CM_ SG_ 2566767358 EngnExhstGsRrltn1Vlv2PstnErrr "The position error of the Exhaust Gas Recirculation 1 valve 2, determined as the actual position (SPN 3821) minus the commanded position (SPN 3822).…";
CM_ SG_ 2566767358 FuelType "Type of fuel currently being utilized by the vehicleData Byte - Scaling - External Display00h = Not available - NONE01h = Gasoline/petrol - GAS02h = Methanol - …";
CM_ BO_ 2566767614 "Electronic Engine Controller 15";
CM_ SG_ 2566767614 AcceleratorPedal1Channel2 "Sensor output 2 for the accelerator pedal #1 position when using a redundant-style sensor.  The ratio of actual accelerator pedal position to maximum pedal posi…";
CM_ SG_ 2566767614 AcceleratorPedal1Channel3 "Sensor output 3 for the accelerator pedal #1 position when using a redundant-style sensor.  The ratio of actual accelerator pedal position to maximum pedal posi…";
CM_ SG_ 2566767614 AcceleratorPedal2Channel2 "Sensor output 2 for the accelerator pedal #2 position when using a redundant-style sensor.  The ratio of actual accelerator pedal position to maximum pedal posi…";
CM_ SG_ 2566767614 AcceleratorPedal2Channel3 "Sensor output 3 for the accelerator pedal #2 position when using a redundant-style sensor.  The ratio of actual accelerator pedal position to maximum pedal posi…";
CM_ SG_ 2566767614 EngnExhstGsRstrtnVlvCntrl "Desired percentage of maximum Exhaust Gas Restriction opening for valve. 0% means valve is closed. 100% means maximum valve opening (full gas flow).…";
CM_ BO_ 2566767870 "Electronic Brake Controller 5";
CM_ SG_ 2566767870 BrakeTemperatureWarning "This parameter indicates if the temperature in the service brakes exceeds a certain value. It can be used for a warning information for the driver. The temperat…";
CM_ SG_ 2566767870 EmergencyBrakingActive "Signal which indicates an emergency braking situation (ref. ECE Regulation 13 paragraph 5.2.1.31) with high  deceleration values.  This signal can be used to ac…";
CM_ SG_ 2566767870 FoundationBrakeUse "This parameter indicates if the brake system presently uses the foundation brakes.00b = Foundation brakes not in use01b = Foundation brakes in use10b = Reserved…";
CM_ SG_ 2566767870 Haltbrakemode "Signal which indicates the current mode of the halt brake function.000b = Inactive001b = Active010b = Active, but not functioning properly.  (This mode may be u…";
CM_ SG_ 2566767870 Hillholdermode "Signal which indicates the current mode of the hill holder function.000b = Inactive001b = Active010b = Active, but will change to inactive in a short time.  (Th…";
CM_ SG_ 2566767870 PrkngBrkAttrFllAtvtd "Signal which indicates when the parking brake actuator is fully activated.  (see also SPN 70 and 619).00b = Parking Brake Actuator not fully activated01b = Park…";
CM_ SG_ 2566767870 RailroadMode "Signal which indicates the current state of the Railroad Mode / Function.00b = Inactive (Driving mode: Steer Axle on ground)01b = Active (Railroad mode: Steer A…";
CM_ SG_ 2566767870 XBRAccelerationLimit "The brake system may temporarily or generally limit the maximum brake performance available for external systems. A temporary limit may be nessary due to high b…";
CM_ SG_ 2566767870 XBRActiveControlMode "This parameter indicates which XBR Control Mode is executed by the brake system.0000b = No brake demand being executed (default mode)0001b = Driver's brake dema…";
CM_ SG_ 2566767870 XBRSystemState "This parameter indicates which external brake control is allowed.00b = Any external brake demand will be accepted (brake system fully operational)01b = Only ext…";
CM_ BO_ 2566768126 "ECU Identification Information";
CM_ SG_ 2566768126 ECUHardwareID "The ECU Hardware ID provides information to identify a specific ECU hardware version.As an example, on a CAN network, this parameter can be used to uniquely ide…";
CM_ SG_ 2566768126 ECULocation "The location of the ECU within a network.…";
CM_ SG_ 2566768126 ECUManufacturerName "The name of the manufacturer of the physical ECU.This name may be different than the manufacturer identified by the Manufacturer Code (SPN 2838) and listed in t…";
CM_ SG_ 2566768126 ECUPartNumber "The part number of the physical ECU.…";
CM_ SG_ 2566768126 ECUSerialNumber "The serial number of the physical ECU.…";
CM_ SG_ 2566768126 ECUType "The type of ECU.  One example of a use of the ECU type could be for classifying ECU capabilities, such as I/O.…";
CM_ BO_ 2566768382 "Cold Start Aids";
CM_ SG_ 2566768382 EngineColdStartFuelIgniterRelay "The engine cold start fuel igniter relay control command.  This command controls the relay, not the igniter.00b = Off01b = On10b = Reserved11b = Don't care/take…";
CM_ SG_ 2566768382 EngineStartEnableDevice1 "Devices that assist an Engine in starting, e.g. intake heaters and ether.  Primary starting aid.Parameter indicating whether the start enable device 1 is ON or …";
CM_ SG_ 2566768382 EngineStartEnableDevice2 "Devices that assist an engine in starting, e.g. intake heaters, ether, or an alternate/secondary starting aid.  May be of the same type or different than Start …";
CM_ SG_ 2566768382 EngnCldStrtFlIgntrCmmnd "The engine cold start fuel igniter control command, normalized to %, where 0% represents fully off and 100% represents fully on.…";
CM_ SG_ 2566768382 EngnCldStrtFlIgntrRlFdk "Feedback state of the engine cold start fuel igniter relay which indicates the status of the relay output.00b = Off01b = On10b = Error11b = Not available…";
CM_ SG_ 2566768382 EngnStrtEnlDv1Cnfgrtn "The start enable device installed for start enable device 1.0000b = no start enable device 1 installed0001b = glow plugs installed0010b = fuelled start installe…";
CM_ SG_ 2566768382 EngnStrtEnlDv2Cnfgrtn "The start enable device installed for start enable device 2.0000b = no start enable device 2 installed0001b = glow plugs installed0010b = fuelled start installe…";
CM_ BO_ 2566768638 "Off-Highway Engine Control Selection States";
CM_ SG_ 2566768638 EngineAuxiliaryGovernorState "This is the Engine Auxiliary Governor feature. This feature is used to allow engine speed to be controlled by an auxiliary input such as pressure or tailshaft s…";
CM_ SG_ 2566768638 EngineMultiUnitSyncState "This feature is widely used in Industry to operate multiple engines from a single command source. A master engine will synchronize one or more slave engines to …";
CM_ SG_ 2566768638 EngineOperatingModeSelection "Identifies the current engine operating mode. In some off-highway applications it may be desirable to have multiple preconfigured operating modes available for …";
CM_ SG_ 2566768638 EngineTorqueCurveSelection "This parameter will report the selected torque curve, as indicated by SPN 6796.0 = Indicates that the engine is using a torque that is not presently selected by…";
CM_ SG_ 2566768638 EngnAltrntDrpAlrtr2SltStt "In some off-highway applications it may be desirable to have multiple droop settings available across the range of engine operation.  For example, in an agricul…";
CM_ SG_ 2566768638 EngnAltrntLwIdlSltStt "In many applications, it is desirable that an alternate low idle speed setting be made available via switch input. The normal programmed low idle is the default…";
CM_ SG_ 2566768638 EngnAltrntRtngSltStt "This parameter reflects the control state that has been achieved based on the input from the SPN 2882.  In some off-highway applications it may be desirable to …";
CM_ SG_ 2566768638 EngnDrpAlrtr1SltStt "In some off-highway applications it may be desirable to have multiple droop settings available across the range of engine operation.  For example, in an agricul…";
CM_ SG_ 2566768638 EngnDrpAxlrInptSltStt "In some off-highway applications it may be desirable to have multiple droop settings available across the range of engine operation.  For example, in an agricul…";
CM_ SG_ 2566768638 EngnDrpRmtAlrtrSltStt "In some off-highway applications it may be desirable to have multiple droop settings available across the range of engine operation.  For example, in an agricul…";
CM_ BO_ 2566768894 "Operator Primary Intermediate Speed Control state";
CM_ SG_ 2566768894 EngnOprtrPrmrIntrmdtSpdSltStt "13 preprogrammed intermediate speed control settings are available for the controlling ECM to select.  If no speed setting is requested, the engine operates nor…";
CM_ BO_ 2566769406 "Intermediate Speed Control";
CM_ SG_ 2566769406 EngnOprtrPrmrIntrmdtSpdSlt "Allows the operator to select one of 13 preprogrammed Intermediate Speed Control settings. If no speed setting is requested, the engine operates normally. The I…";
CM_ BO_ 2566769662 "Off-Highway Engine Control Selection";
CM_ SG_ 2566769662 EngineAlternateLowIdleSwitch "Operator switch which selects between two low idle speeds, default and alternate.The normal programmed low idle is the default low idle, and when the Alternate …";
CM_ SG_ 2566769662 EngineAlternateRatingSelect "In some off-highway applications it may be desirable to have multiple engine ratings available for selection by the operator. There is the default engine rating…";
CM_ SG_ 2566769662 EngineAuxiliaryGovernorSwitch "This is the On/Off operation of the Auxiliary Governor feature switch. This feature is used to allow engine speed to be controlled by an auxiliary input such as…";
CM_ SG_ 2566769662 EngineDroopAccelerator1Select "In some off-highway applications it may be desirable to have multiple droop settings available across the range of engine operation.  For example, in an agricul…";
CM_ SG_ 2566769662 EngineDroopAccelerator2Select "In some off-highway applications it may be desirable to have multiple droop settings available across the range of engine operation.  For example, in an agricul…";
CM_ SG_ 2566769662 EngineDroopAuxiliaryInputSelect "In some off-highway applications it may be desirable to have multiple droop settings available across the range of engine operation.  For example, in an agricul…";
CM_ SG_ 2566769662 EngineOperatingModeCommand "Command signal identifying the desired preconfigured engine operating mode. In some off-highway applications it may be desirable to have multiple preconfigured …";
CM_ SG_ 2566769662 EngineSynchronizationSwitch "This is the On/Off operation of the Multiple Unit Synchronization functionality. When it is enabled (i.e. On) the master engine will synchronize one or more sla…";
CM_ SG_ 2566769662 EngnDrpRmtAlrtrSlt "In some off-highway applications it may be desirable to have multiple droop settings available across the range of engine operation.  For example, in an agricul…";
CM_ SG_ 2566769662 EngnTrqCrvSltnCmmnd "This parameter will allow selection of a torque curve that is higher than the base curve.0 = Indicates that this parameter is not presently requesting a differe…";
CM_ BO_ 2566770174 "Operator Wiper and Washer Controls Message";
CM_ SG_ 2566770174 FrntNnprtrWprDlCntrl "Time between cycles of the front non-operator side wiper (i.e. from end of cycle 'n' to start of cycle 'n+1') as selected by the operator control (switch, etc.)…";
CM_ SG_ 2566770174 FrontNonoperatorWasherSwitch "State of operation selected by operator switch for the front washer not in front of the operator position.  The parameter, 'Front Operator Washer Switch' should…";
CM_ SG_ 2566770174 FrontNonoperatorWiperSwitch "State of operation selected by operator switch for the front wiper not in front of the operator position.  The parameter, 'Front Operator Washer Switch' should …";
CM_ SG_ 2566770174 FrontOperatorWasherSwitch "State of operation selected by operator switch for the washer in front of the operator position. This parameter, 'Front Operator Washer Switch' should be used f…";
CM_ SG_ 2566770174 FrontOperatorWiperDelayControl "Time between cycles of the front operator side wiper (i.e. from end of cycle 'n' to start of cycle 'n+1') as selected by the operator control (switch, etc.) in …";
CM_ SG_ 2566770174 FrontOperatorWiperSwitch "State of operation selected by operator switch for the Wiper in front of the operator position. This parameter, 'Front Operator Wiper Switch' should be used for…";
CM_ SG_ 2566770174 RearWasherFunction "State of operation selected by operator switch for the rear washer.   The parameter, 'Front Operator Washer Switch' should be used for the control information i…";
CM_ SG_ 2566770174 RearWiperDelayControl "Time between cycles of the rear wiper (i.e. from end of cycle 'n' to start of cycle 'n+1') as selected by the operator control (switch, etc.) in percentage of p…";
CM_ SG_ 2566770174 RearWiperSwitch "State of operation selected by operator switch for the rear wiper.  The parameter, 'Front Operator Washer Switch' should be used for the control information if …";
CM_ BO_ 2566770942 "Intake/Exhaust Conditions 2";
CM_ SG_ 2566770942 EngineIntakeManifold2Pressure "The gage pressure measurement of the air intake manifold for bank #2 or the second air intake manifold. If there are multiple air pressure sensors in the second…";
CM_ SG_ 2566770942 EngnArFltr2DffrntlPrssr "Change in engine air system pressure, measured across the second air filter, due to the filter and any accumulation of solid foreign matter on or in the filter.…";
CM_ SG_ 2566770942 EngnArFltr3DffrntlPrssr "Change in engine air system pressure, measured across the third air filter, due to the filter and any accumulation of solid foreign matter on or in the filter.T…";
CM_ SG_ 2566770942 EngnArFltr4DffrntlPrssr "Change in engine air system pressure, measured across the fourth air filter, due to the filter and any accumulation of solid foreign matter on or in the filter.…";
CM_ SG_ 2566770942 EngnIntkMnfld1AsltPrssr "The absolute pressure measurement of the air intake manifold. If there are multiple air pressure sensors in the intake stream, this is the last one in flow dire…";
CM_ SG_ 2566770942 EngnIntkMnfld1AsltPrssrHghRsltn "The absolute pressure measurement of the air intake manifold. If there are multiple air pressure sensors in the intake stream, this is the last one in flow dire…";
CM_ SG_ 2566770942 EngnIntkMnfld2AsltPrssr "The absolute pressure measurement of the air intake manifold for bank 2 or the second air intake manifold. If there are multiple air pressure sensors in the int…";
CM_ BO_ 2566771454 "ECU Performance";
CM_ SG_ 2566771454 DataMemoryUsage "The used storage capacity of the data buffer memory internal to an ECU, such as a data logger.…";
CM_ SG_ 2566771454 KeepAliveBatteryConsumption "The capacity consumed from the direct battery connection since the key was last turned off.  This value is maintained and does not accumulate while the key swit…";
CM_ BO_ 2566771710 "Turbocharger Information 6";
CM_ SG_ 2566771710 EngnTrhrgr1CmprssrOtltTmprtr "Temperature of the air or air/fuel mixture exiting the turbocharger 1 compressor outlet…";
CM_ SG_ 2566771710 EngnTrhrgr2CmprssrOtltTmprtr "Temperature of the air or air/fuel mixture exiting the turbocharger 2 compressor outlet.…";
CM_ SG_ 2566771710 EngnTrhrgr3CmprssrOtltTmprtr "Temperature of the air or air/fuel mixture exiting the turbocharger 3 compressor outlet.…";
CM_ SG_ 2566771710 EngnTrhrgr4CmprssrOtltTmprtr "Temperature of the air or air/fuel mixture exiting the turbocharger 4 compressor outlet.…";
CM_ BO_ 2566771966 "Cab Message 3";
CM_ SG_ 2566771966 FfthWhlRlsCntrlSrtLkt "Operator's fifth wheel release control interlock. This operator input must be enabled prior to activating the fifth wheel release control (SPN 3314). 00b = Fift…";
CM_ SG_ 2566771966 FifthWheelReleaseControl "Operator input used to release the fifth wheel. Fifth Wheel Release Control Security Lockout and other conditions must be properly enabled before this will func…";
CM_ SG_ 2566771966 TransferCaseSelectorSwitch "Operator switch to select the condition of the transfer case.  States 000b and 001b should be used if the transfer case only functions to switch between 2-wheel…";
CM_ SG_ 2566771966 TransmissionOilLevelRequest "Conveys operator or vehicle system desire for a transmission oil level reading to be taken. 00b = No transmission oil level reading desired01b = Transmission oi…";
CM_ SG_ 2566771966 VehicleTrailerStatus "Indicates a trailer is connected to the towing mechanism.  This is not intended to indicate that the trailer is latched.00b = Trailer is not detected01b = Trail…";
CM_ SG_ 2566771966 AftrtrtmntSCRDsngMdCmmnd "Request the aftertreatment system to run in standard or reduced mode. Standard indicates that the system will dose at higher capacity where the reduced mode wil…";
CM_ SG_ 2566771966 MomentaryOperatorKeySwitch "Momentary switch (possibly a push button switch) that indicates the operator's desire to enter accessory mode, enter run mode, enter crank mode, activate the pr…";
CM_ SG_ 2566771966 OperatorKeyDetected "Indicates that a key is physically inserted in the key switch, or for keyless systems, that a valid key is within activation range.00b = No key detected01b = Ke…";
CM_ SG_ 2566771966 OperatorKeySwitchAccessoryPower "Indicates that the accessory state of the operator key switch is active.This parameter represents the capability of a rotary key switch position, a keyless swit…";
CM_ SG_ 2566771966 OperatorKeySwitchIgnitionPower "Indicates that the ignition (or run) state of the operator key switch is active. This state is also known in DIN 75552 as KL15. Devices should use SPN 158 to re…";
CM_ SG_ 2566771966 OperatorKeySwitchStart "Indicates that the start state of the operator key switch is active. This state is also known in DIN 75552 as KL50.This parameter represents the capability of a…";
CM_ SG_ 2566771966 OprtrKSwthDldBttrOff "Indicates a state in which the main battery switch will be opened after a short delay. This allows the battery to be disconnected (as may be required by ADR reg…";
CM_ BO_ 2566772222 "Electronic Engine Controller 5";
CM_ SG_ 2566772222 EngineFuelControlMode "Indicates whether the Engine Fuel Control System is in open loop or closed loop.00b = Open loop01b = Closed loop10b = SAE reserved11b = Not available…";
CM_ SG_ 2566772222 EngnExhstGsRrltn1Vlv1Cntrl1 "Desired percentage of maximum Exhaust Gas Recirculation (EGR) valve 1 opening.  0% means valve is closed. 100% means maximum valve opening (full gas flow).…";
CM_ SG_ 2566772222 EngnTrhrgr1ClltdTrnIntkTmprtr "Calculated value of turbine intake temperature based on engine operating conditions, such as intake manifold temperature, charge fuel ratio, injection timing, a…";
CM_ SG_ 2566772222 EngnTrhrgr1ClltdTrnOtltTmprtr "Calculated value of turbocharger compressor outlet air temperature.  Temperature of air exiting the turbocharger compressor and before entering charge air coole…";
CM_ SG_ 2566772222 EngnVrlGmtrTrhrgr1CntrlMd "Indicates if the variable geometry turbocharger control status is either open loop or closed loop.00b = open loop01b = closed loop10b = SAE reserved11b = not av…";
CM_ SG_ 2566772222 EngnVrlGmtrTrhrgrVGT1AttrPstn "Sensor that measures the position of the variable geometry turbocharger actuator.  A  position of 0% indicates the actuator is in the position creating the smal…";
CM_ SG_ 2566772222 EVGtTVGTACtStVv "Isolates vehicle brake air from the Variable Geometry Turbocharger (VGT) system when engine is not running.  This valve prevents vehicle air from bleeding off t…";
CM_ BO_ 2566774014 "Marine Control Information";
CM_ SG_ 2566774014 EngineMarineOperatingModeStatus "The operating mode of the engine for marine functions.000b = Maintenance Mode001b = Electrical Power Generation (EPG) mode010b = Propulsion Constant Speed Mode0…";
CM_ SG_ 2566774014 EngnThrttlSnhrnztnMdStts "The status of the Throttle Synchronization Mode. Throttle Synchronization Mode is used to indicate which throttle, if any, is currently being used for the synch…";
CM_ SG_ 2566774014 SlowVesselModeStatus "The status of the Slow Vessel Mode.  Slow Vessel Mode puts the engine in a lower-than-normal low idle speed during docking or other slow vessel operations.00b =…";
CM_ SG_ 2566774014 TrollingModeStatus "The status of the Trolling Mode.  Trolling mode limits the top speed.  Full range travel of the throttle level spans from low idle engine speed to maximum troll…";
CM_ BO_ 2566775038 "Ambient Conditions 2";
CM_ SG_ 2566775038 BrmtrAsltPrssrHghRsltn "Barometric Absolute Pressure (High Resolution).  See SPN 108 if high resolution is not needed.…";
CM_ SG_ 2566775038 CalculatedAmbientAirTemperature "Calculated temperature of air surrounding vehicle.  Use SPN 171 for actual measured ambient air temperature.…";
CM_ SG_ 2566775038 SolarIntensityPercent "This is the solar radiation (power density) falling on the vehicle in percent of the maximum sensor value (SPN 2611).  Currently this is in the infra-red spectr…";
CM_ SG_ 2566775038 SolarSensorMaximum "This is the maximum value which can be reported by the sensor for the solar intensity. (This is a configuration parameter)…";
CM_ SG_ 2566775038 SpecificHumidity "Specific humidity of the ambient intake air.…";
CM_ BO_ 2566775294 "Cab A/C Climate System Information";
CM_ SG_ 2566775294 AirConditionerCompressorStatus "Signal which indicates if the Air Conditioner compressor is on or off.00b = Air Conditioner Compressor is OFF01b = Air Conditioner Compressor is ON10b = Error11…";
CM_ SG_ 2566775294 CACRfrgrntCmprssrOtltPrssr "This is the gage pressure at the compressor outlet in the cab air conditioning system.…";
CM_ BO_ 2566775550 "Supply Pressure Demand";
CM_ SG_ 2566775550 ArSspnsnSpplPrssrRqst "Command signal to influence the pneumatic pressure in the circuit for the electronically controlled air suspension system.   This parameter is the setpoint for …";
CM_ SG_ 2566775550 AxlrEqpmntSpplPrssrRqst "Command signal to influence the pneumatic pressure in the auxiliary circuit.   This parameter is the setpoint for the parameter SPN 1089.…";
CM_ SG_ 2566775550 PneumaticSupplyPressureRequest "Command signal to influence the pneumatic pressure in the main reservoir.  This parameter is the setpoint for the parameter SPN 46.…";
CM_ SG_ 2566775550 PrkngndrTrlrArPrssrRqst "Command signal to influence the pneumatic pressure in the circuit or reservoir for the parking brake and/or the trailer supply.  This parameter is the setpoint …";
CM_ SG_ 2566775550 PwrtrnCrtArSpplPrssrRqst "Command signal to influence the air pressure in the powertrain circuit.  This parameter is the setpoint for the parameter SPN 6305.…";
CM_ SG_ 2566775550 SrvBrkArPrssrRqstCrt1 "Command signal to influence the pneumatic pressure in the service brake circuit or reservoir #1.  This parameter is the setpoint for the parameter SPN 1087.…";
CM_ SG_ 2566775550 SrvBrkArPrssrRqstCrt2 "Command signal to influence the pneumatic pressure in the service brake circuit or reservoir #2.  This parameter is the setpoint for the parameter SPN 1088.…";
CM_ BO_ 2566775806 "Equipment Operation and Control";
CM_ SG_ 2566775806 TravelVelocityControlPosition "The position of the travel velocity control component reported as a percentage of the control's full displacement in each direction respectively.  Positive posi…";
CM_ BO_ 2566776062 "Equipment Performance Data";
CM_ SG_ 2566776062 PayloadCapacityPercentage "The current equipment payload plus the weight of any after-factory modifications reported as a percentage of the equipment's maximum payload capacity. The equip…";
CM_ SG_ 2566776062 PayloadCarryBackWeight "The payload weight left on the machine after the last payload dump event.…";
CM_ SG_ 2566776062 PayloadPercentage "The current payload of the equipment, reported as a percentage of the equipment's rated payload limit.…";
CM_ SG_ 2566776062 PayloadWeight "The current payload weight carried by the machine.…";
CM_ SG_ 2566776062 PayloadWeightConfidence "The level of confidence of the real time payload weight measurement (SPN 6851). Higher confidence values indicate greater probability the real time payload weig…";
CM_ BO_ 2566776318 "Maximum Vehicle Speed Limit Status";
CM_ SG_ 2566776318 AppliedVehicleSpeedLimit "The vehicle speed limit in effect.251 (FBh) is used to indicate that a maximum vehicle speed limit is not selected.See SPN 7420 for alternate resolution.…";
CM_ SG_ 2566776318 MaximumVehicleSpeedLimit1 "The lowest Maximum Vehicle Speed Limit. This value is the similar to SPN 74. However, SPN 74 was not specifically defined to convey  the applied vehicle speed l…";
CM_ SG_ 2566776318 MaximumVehicleSpeedLimit2 "The highest of the two lowest vehicle speed limits…";
CM_ SG_ 2566776318 MaximumVehicleSpeedLimit3 "The highest of the three lowest vehicle speed limits…";
CM_ SG_ 2566776318 MaximumVehicleSpeedLimit4 "The highest of the four lowest vehicle speed limits…";
CM_ SG_ 2566776318 MaximumVehicleSpeedLimit5 "The highest of the five lowest vehicle speed limits…";
CM_ SG_ 2566776318 MaximumVehicleSpeedLimit6 "The highest of the six lowest vehicle speed limits…";
CM_ SG_ 2566776318 MaximumVehicleSpeedLimit7 "The highest of the seven lowest vehicle speed limits…";
BA_DEF_ SG_  "SPN" INT 0 524287;
BA_DEF_ BO_  "VFrameFormat" ENUM  "StandardCAN","ExtendedCAN","reserved","J1939PG";
BA_DEF_DEF_  "SPN" 0;
BA_DEF_DEF_  "VFrameFormat" "J1939PG";
BA_ "SPN" SG_ 2566734334 Aftrtrtmnt1DslExhstFldLnHtr1Stt 4340;
BA_ "SPN" SG_ 2566734334 Aftrtrtmnt1DslExhstFldLnHtr2Stt 4342;
BA_ "SPN" SG_ 2566734334 Aftrtrtmnt1DslExhstFldLnHtr3Stt 4344;
BA_ "SPN" SG_ 2566734334 Aftrtrtmnt1DslExhstFldLnHtr4Stt 4346;
BA_ "SPN" SG_ 2566734334 Aftrtrtmnt1SCRDsngArAssstVlv 4336;
BA_ "SPN" SG_ 2566734334 Aftrtrtmnt1SCRFdkCntrlStts 4339;
BA_ "SPN" SG_ 2566734334 Atttt1DsExstFdDs1Tpt 4337;
BA_ "SPN" SG_ 2566734334 Atttt1DsExstFdLHt1PFMI 4341;
BA_ "SPN" SG_ 2566734334 Atttt1DsExstFdLHt2PFMI 4343;
BA_ "SPN" SG_ 2566734334 Atttt1DsExstFdLHt3PFMI 4345;
BA_ "SPN" SG_ 2566734334 Atttt1DsExstFdLHt4PFMI 4347;
BA_ "SPN" SG_ 2566734334 Atttt1SCRDsAAssstAstPss 4335;
BA_ "SPN" SG_ 2566734334 Atttt1SCRDsVvExstTptRdtRqst 4338;
BA_ "SPN" SG_ 2566735102 Aftertreatment2FuelPressure2 4303;
BA_ "SPN" SG_ 2566735102 Aftrtrtmnt2FlFlwDvrtrVlvCntrl 5427;
BA_ "SPN" SG_ 2566735102 Aftrtrtmnt2FlPmpRlCntrl 5426;
BA_ "SPN" SG_ 2566735102 Aftrtrtmnt2FlPrssr2Cntrl 5428;
BA_ "SPN" SG_ 2566735358 Aftrtrtmnt2ThrWCtlstIntkTmprtr 4295;
BA_ "SPN" SG_ 2566735358 Aftrtrtmnt2ThrWCtlstOtltTmprtr 4296;
BA_ "SPN" SG_ 2566735358 Atttt2TWCtstDtPss 4297;
BA_ "SPN" SG_ 2566735358 Atttt2TWCtstItTptPFMI 4298;
BA_ "SPN" SG_ 2566735358 Atttt2TWCtstOttTptPFMI 4299;
BA_ "SPN" SG_ 2566735358 Atttt2TWCttCvtDtPssPFMI 4300;
BA_ "SPN" SG_ 2566735614 Aftrtrtmnt1ThrWCtlstIntkTmprtr 4289;
BA_ "SPN" SG_ 2566735614 Aftrtrtmnt1ThrWCtlstOtltTmprtr 4290;
BA_ "SPN" SG_ 2566735614 Atttt1TWCtstDtPss 4291;
BA_ "SPN" SG_ 2566735614 Atttt1TWCtstItTptPFMI 4292;
BA_ "SPN" SG_ 2566735614 Atttt1TWCtstOttTptPFMI 4293;
BA_ "SPN" SG_ 2566735614 Atttt1TWCttCvtDtPssPFMI 4294;
BA_ "SPN" SG_ 2566736126 EngnExhstBnk2O2SnsrClsdLpOprtn 4241;
BA_ "SPN" SG_ 2566736126 LongtermFuelTrimBank2 4239;
BA_ "SPN" SG_ 2566736126 ShorttermFuelTrimBank2 4238;
BA_ "SPN" SG_ 2566736382 EngnExhstBnk1O2SnsrClsdLpOprtn 4240;
BA_ "SPN" SG_ 2566736382 LongtermFuelTrimBank1 4237;
BA_ "SPN" SG_ 2566736382 ShorttermFuelTrimBank1 4236;
BA_ "SPN" SG_ 2566743550 Aftertreatment1FuelPressure2 4077;
BA_ "SPN" SG_ 2566743550 Aftrtrtmnt1FlFlwDvrtrVlvCntrl 5424;
BA_ "SPN" SG_ 2566743550 Aftrtrtmnt1FlPmpRlCntrl 5423;
BA_ "SPN" SG_ 2566743550 Aftrtrtmnt1HdrrnDsrIntkFlTmprtr 5456;
BA_ "SPN" SG_ 2566743550 Aftrtrtmnt1FlPrssr2Cntrl 5425;
BA_ "SPN" SG_ 2566743806 EngineCoolantTemperature2 4076;
BA_ "SPN" SG_ 2566743806 EngineCoolantTemperature3 6209;
BA_ "SPN" SG_ 2566743806 EngineCoolantThermostatOpening 4194;
BA_ "SPN" SG_ 2566743806 EngnClntPmpOtltTmprtr 4193;
BA_ "SPN" SG_ 2566743806 EngnExhstGsRrltn1MxrIntkTmprtr 5020;
BA_ "SPN" SG_ 2566743806 EngnExhstVlvAttnSstmOlTmprtr 4288;
BA_ "SPN" SG_ 2566744062 ZeroNetVehicleWeightChange 4075;
BA_ "SPN" SG_ 2566745086 AddtnlTrlrAxlGrpWghtAvll 4072;
BA_ "SPN" SG_ 2566745086 AddtnlTrtrAxlGrpWghtAvll 4063;
BA_ "SPN" SG_ 2566745086 LiftAxleGroupWeightAvailable 4060;
BA_ "SPN" SG_ 2566745086 RrDrvAxlGrpWghtAvll 5934;
BA_ "SPN" SG_ 2566745086 RrStrAxlGrpWghtAvll 5933;
BA_ "SPN" SG_ 2566745086 SlrFrwrdmstDrvAxlGrpWghtAvll 4061;
BA_ "SPN" SG_ 2566745086 SlrFrwrdmstStrAxlGrpWghtAvll 4059;
BA_ "SPN" SG_ 2566745086 TagAxleGroupWeightAvailable 4062;
BA_ "SPN" SG_ 2566745086 TrlrAAxlGrpWghtAvll 4064;
BA_ "SPN" SG_ 2566745086 TrlrBAxlGrpWghtAvll 4065;
BA_ "SPN" SG_ 2566745086 TrlrCAxlGrpWghtAvll 4066;
BA_ "SPN" SG_ 2566745086 TrlrDAxlGrpWghtAvll 4067;
BA_ "SPN" SG_ 2566745086 TrlrEAxlGrpWghtAvll 4068;
BA_ "SPN" SG_ 2566745086 TrlrFAxlGrpWghtAvll 4069;
BA_ "SPN" SG_ 2566745086 TrlrGAxlGrpWghtAvll 4070;
BA_ "SPN" SG_ 2566745086 TrlrHAxlGrpWghtAvll 4071;
BA_ "SPN" SG_ 2566745342 Aftrtrtmnt2SndrArDffrntlPrssr 3833;
BA_ "SPN" SG_ 2566745342 Aftrtrtmnt2SndrArMssFlwRt 3835;
BA_ "SPN" SG_ 2566745342 Aftrtrtmnt2SndrArPrssr 3838;
BA_ "SPN" SG_ 2566745342 Aftrtrtmnt2SndrArTmprtr 3834;
BA_ "SPN" SG_ 2566745598 Aftrtrtmnt1SndrArDffrntlPrssr 3830;
BA_ "SPN" SG_ 2566745598 Aftrtrtmnt1SndrArMssFlwRt 3832;
BA_ "SPN" SG_ 2566745598 Aftrtrtmnt1SndrArPrssr 3837;
BA_ "SPN" SG_ 2566745598 Aftrtrtmnt1SndrArTmprtr 3831;
BA_ "SPN" SG_ 2566745854 Aftrtrtmnt1SCRCnvrsnEffn 4364;
BA_ "SPN" SG_ 2566745854 Aftrtrtmnt1SCRSstmSlftnLvl 7504;
BA_ "SPN" SG_ 2566745854 Atttt1DsExstFdAvCspt 3826;
BA_ "SPN" SG_ 2566745854 Atttt1SCRCddDsExstFdCspt 3828;
BA_ "SPN" SG_ 2566745854 AttttSCROptIdtAtvTvdDst 5463;
BA_ "SPN" SG_ 2566746110 EExstGsRt1CItAstPss 4751;
BA_ "SPN" SG_ 2566746110 EngnExhstGsRrltn1ClrEffn 4752;
BA_ "SPN" SG_ 2566746110 EngnExhstGsRrltn1ClrIntkTmprtr 4750;
BA_ "SPN" SG_ 2566746110 EngnExhstGsRrltn1Vlv2Cntrl 3821;
BA_ "SPN" SG_ 2566746366 Enablestatusoframp1 3811;
BA_ "SPN" SG_ 2566746366 Enablestatusoframp2 3814;
BA_ "SPN" SG_ 2566746366 Enablestatusoframp3 3817;
BA_ "SPN" SG_ 2566746366 Enablestatusoframp4 4455;
BA_ "SPN" SG_ 2566746366 Enablestatusoframp5 4458;
BA_ "SPN" SG_ 2566746366 Movementstatusoframp1 3812;
BA_ "SPN" SG_ 2566746366 Movementstatusoframp2 3815;
BA_ "SPN" SG_ 2566746366 Movementstatusoframp3 3818;
BA_ "SPN" SG_ 2566746366 Movementstatusoframp4 4456;
BA_ "SPN" SG_ 2566746366 Movementstatusoframp5 4459;
BA_ "SPN" SG_ 2566746366 RetractStatusoframp1 3810;
BA_ "SPN" SG_ 2566746366 RetractStatusoframp2 3813;
BA_ "SPN" SG_ 2566746366 RetractStatusoframp3 3816;
BA_ "SPN" SG_ 2566746366 RetractStatusoframp4 4454;
BA_ "SPN" SG_ 2566746366 RetractStatusoframp5 4457;
BA_ "SPN" SG_ 2566746622 TractorBrakeStrokeAxle1Left 3785;
BA_ "SPN" SG_ 2566746622 TractorBrakeStrokeAxle1Right 3786;
BA_ "SPN" SG_ 2566746622 TractorBrakeStrokeAxle2Left 3787;
BA_ "SPN" SG_ 2566746622 TractorBrakeStrokeAxle2Right 3788;
BA_ "SPN" SG_ 2566746622 TractorBrakeStrokeAxle3Left 3789;
BA_ "SPN" SG_ 2566746622 TractorBrakeStrokeAxle3Right 3790;
BA_ "SPN" SG_ 2566746622 TractorBrakeStrokeAxle4Left 3791;
BA_ "SPN" SG_ 2566746622 TractorBrakeStrokeAxle4Right 3792;
BA_ "SPN" SG_ 2566746622 TractorBrakeStrokeAxle5Left 3793;
BA_ "SPN" SG_ 2566746622 TractorBrakeStrokeAxle5Right 3794;
BA_ "SPN" SG_ 2566746622 TrailerBrakeStrokeAxle1Left 3795;
BA_ "SPN" SG_ 2566746622 TrailerBrakeStrokeAxle1Right 3796;
BA_ "SPN" SG_ 2566746622 TrailerBrakeStrokeAxle2Left 3797;
BA_ "SPN" SG_ 2566746622 TrailerBrakeStrokeAxle2Right 3798;
BA_ "SPN" SG_ 2566746622 TrailerBrakeStrokeAxle3Left 3799;
BA_ "SPN" SG_ 2566746622 TrailerBrakeStrokeAxle3Right 3800;
BA_ "SPN" SG_ 2566746622 TrailerBrakeStrokeAxle4Left 3801;
BA_ "SPN" SG_ 2566746622 TrailerBrakeStrokeAxle4Right 3802;
BA_ "SPN" SG_ 2566746622 TrailerBrakeStrokeAxle5Left 3803;
BA_ "SPN" SG_ 2566746622 TrailerBrakeStrokeAxle5Right 3804;
BA_ "SPN" SG_ 2566746878 EngineSparkPlug21 1314;
BA_ "SPN" SG_ 2566746878 EngineSparkPlug22 1315;
BA_ "SPN" SG_ 2566746878 EngineSparkPlug23 1316;
BA_ "SPN" SG_ 2566746878 EngineSparkPlug24 1317;
BA_ "SPN" SG_ 2566747134 EngineSparkPlug17 1310;
BA_ "SPN" SG_ 2566747134 EngineSparkPlug18 1311;
BA_ "SPN" SG_ 2566747134 EngineSparkPlug19 1312;
BA_ "SPN" SG_ 2566747134 EngineSparkPlug20 1313;
BA_ "SPN" SG_ 2566747390 EngineSparkPlug13 1306;
BA_ "SPN" SG_ 2566747390 EngineSparkPlug14 1307;
BA_ "SPN" SG_ 2566747390 EngineSparkPlug15 1308;
BA_ "SPN" SG_ 2566747390 EngineSparkPlug16 1309;
BA_ "SPN" SG_ 2566747646 EngineSparkPlug10 1303;
BA_ "SPN" SG_ 2566747646 EngineSparkPlug11 1304;
BA_ "SPN" SG_ 2566747646 EngineSparkPlug12 1305;
BA_ "SPN" SG_ 2566747646 EngineSparkPlug9 1302;
BA_ "SPN" SG_ 2566747902 EngineSparkPlug5 1298;
BA_ "SPN" SG_ 2566747902 EngineSparkPlug6 1299;
BA_ "SPN" SG_ 2566747902 EngineSparkPlug7 1300;
BA_ "SPN" SG_ 2566747902 EngineSparkPlug8 1301;
BA_ "SPN" SG_ 2566748158 EngineSparkPlug1 1294;
BA_ "SPN" SG_ 2566748158 EngineSparkPlug2 1295;
BA_ "SPN" SG_ 2566748158 EngineSparkPlug3 1296;
BA_ "SPN" SG_ 2566748158 EngineSparkPlug4 1297;
BA_ "SPN" SG_ 2566748414 Aftrtrtmnt2DslPrtltFltrTrpFlUsd 3741;
BA_ "SPN" SG_ 2566748414 Atttt2DsPttFtTpAtvRtT 3742;
BA_ "SPN" SG_ 2566748414 Atttt2DsPttFtTpDsdT 3743;
BA_ "SPN" SG_ 2566748414 Atttt2DsPttFtTpNAtvRtItRqsts 3747;
BA_ "SPN" SG_ 2566748414 Atttt2DsPttFtTpNAtvRtMRqsts 3748;
BA_ "SPN" SG_ 2566748414 Atttt2DsPttFtTpNAtvRts 3744;
BA_ "SPN" SG_ 2566748414 Atttt2DsPttFtTpNPssvRts 3746;
BA_ "SPN" SG_ 2566748414 Atttt2DsPttFtTpPssvRtT 3745;
BA_ "SPN" SG_ 2566748670 Aftrtrtmnt1DslPrtltFltrTrpFlUsd 3733;
BA_ "SPN" SG_ 2566748670 Atttt1DsPttFtTpAtvRtT 3734;
BA_ "SPN" SG_ 2566748670 Atttt1DsPttFtTpDsdT 3735;
BA_ "SPN" SG_ 2566748670 Atttt1DsPttFtTpNAtvRtItRqsts 3739;
BA_ "SPN" SG_ 2566748670 Atttt1DsPttFtTpNAtvRtMRqsts 3740;
BA_ "SPN" SG_ 2566748670 Atttt1DsPttFtTpNAtvRts 3736;
BA_ "SPN" SG_ 2566748670 Atttt1DsPttFtTpNPssvRts 3738;
BA_ "SPN" SG_ 2566748670 Atttt1DsPttFtTpPssvRtT 3737;
BA_ "SPN" SG_ 2566748926 Aftrtrtmnt2DslPrtltFltrStLdPrnt 3722;
BA_ "SPN" SG_ 2566748926 Atttt2DsPttFtAsLdPt 3723;
BA_ "SPN" SG_ 2566748926 Atttt2DsPttFtStLdRtTsd 5467;
BA_ "SPN" SG_ 2566748926 Atttt2DsPttFtTSLstAtvRt 3724;
BA_ "SPN" SG_ 2566749182 Aftrtrtmnt1DslPrtltFltrStLdPrnt 3719;
BA_ "SPN" SG_ 2566749182 Atttt1DsPttFtAsLdPt 3720;
BA_ "SPN" SG_ 2566749182 Atttt1DsPttFtStLdRtTsd 5466;
BA_ "SPN" SG_ 2566749182 Atttt1DsPttFtTSLstAtvRt 3721;
BA_ "SPN" SG_ 2566749438 AftrtrtmntDslPrtltFltrStts 3701;
BA_ "SPN" SG_ 2566749438 Atttt1DsPttFtCdtsNtMtAtvRt 3750;
BA_ "SPN" SG_ 2566749438 AttttDsPttFtAtvRtStts 3700;
BA_ "SPN" SG_ 2566749438 AttttDsPttFtPssvRtStts 3699;
BA_ "SPN" SG_ 2566749438 DslPrtltFltrAtvRgnrtnAvlltStts 8857;
BA_ "SPN" SG_ 2566749438 DslPrtltFltrAtvRgnrtnFrdStts 4175;
BA_ "SPN" SG_ 2566749438 DslPrtltFltrAtvRgnrtnInhtdStts 3702;
BA_ "SPN" SG_ 2566749438 DslPrtltFltrLmpCmmnd 3697;
BA_ "SPN" SG_ 2566749438 DsPttFtAttAtvRtIttCt 3718;
BA_ "SPN" SG_ 2566749438 DsPttFtAtvRtItdDtAtPdOId 3707;
BA_ "SPN" SG_ 2566749438 DsPttFtAtvRtItdDtCtDsd 3704;
BA_ "SPN" SG_ 2566749438 DsPttFtAtvRtItdDtENtWdUp 3716;
BA_ "SPN" SG_ 2566749438 DsPttFtAtvRtItdDtItSwt 3703;
BA_ "SPN" SG_ 2566749438 DsPttFtAtvRtItdDtLwExstPss 5629;
BA_ "SPN" SG_ 2566749438 DsPttFtAtvRtItdDtLwExstTpt 3711;
BA_ "SPN" SG_ 2566749438 DsPttFtAtvRtItdDtOtNt 3708;
BA_ "SPN" SG_ 2566749438 DsPttFtAtvRtItdDtPBNtSt 3710;
BA_ "SPN" SG_ 2566749438 DsPttFtAtvRtItdDtPTOAtv 3706;
BA_ "SPN" SG_ 2566749438 DsPttFtAtvRtItdDtPtSstLt 3715;
BA_ "SPN" SG_ 2566749438 DsPttFtAtvRtItdDtSstFtAtv 3712;
BA_ "SPN" SG_ 2566749438 DsPttFtAtvRtItdDtSstTt 3713;
BA_ "SPN" SG_ 2566749438 DsPttFtAtvRtItdDtSvBAtv 3705;
BA_ "SPN" SG_ 2566749438 DsPttFtAtvRtItdDtTpSstLt 3714;
BA_ "SPN" SG_ 2566749438 DsPttFtAtvRtItdDtVSpdAvAwdSpd 3709;
BA_ "SPN" SG_ 2566749438 DsPttFtAtvRtItdDtVSpdBwAwdSpd 3717;
BA_ "SPN" SG_ 2566749438 ExhstSstmHghTmprtrLmpCmmnd 3698;
BA_ "SPN" SG_ 2566749438 HydrocarbonDoserPurgingEnable 5504;
BA_ "SPN" SG_ 2566749438 DsPttFtAtvRtItdDtTs 10153;
BA_ "SPN" SG_ 2566749950 LeftHeadlampDynamicBendingLight 3691;
BA_ "SPN" SG_ 2566749950 LeftHeadlampLightDistribution 3693;
BA_ "SPN" SG_ 2566749950 RghtHdlmpDnmBndngLght 3692;
BA_ "SPN" SG_ 2566749950 RightHeadlampLightDistribution 3694;
BA_ "SPN" SG_ 2566750206 EngnCnfgrtnIdntftn 6395;
BA_ "SPN" SG_ 2566750206 MxmmCrnkAttmptsprStrtAttmpt 3670;
BA_ "SPN" SG_ 2566750206 NmrfCmstnClsfrAvrgng 6394;
BA_ "SPN" SG_ 2566750206 TrnsmssnIdlGvrnrFlngInhtSpprt 7830;
BA_ "SPN" SG_ 2566751230 TransferCaseActualGearRatio 9170;
BA_ "SPN" SG_ 2566751230 TransferCaseDirectionStatus 8849;
BA_ "SPN" SG_ 2566751230 TransferCaseMessageChecksum 9172;
BA_ "SPN" SG_ 2566751230 TransferCaseMessageCounter 9171;
BA_ "SPN" SG_ 2566751230 Transfercasestatus 3645;
BA_ "SPN" SG_ 2566751486 EngnIntkVlvAttnOlPrssrfrClndr17 3640;
BA_ "SPN" SG_ 2566751486 EngnIntkVlvAttnOlPrssrfrClndr18 3641;
BA_ "SPN" SG_ 2566751486 EngnIntkVlvAttnOlPrssrfrClndr19 3642;
BA_ "SPN" SG_ 2566751486 EngnIntkVlvAttnOlPrssrfrClndr20 3643;
BA_ "SPN" SG_ 2566751742 EngnIntkVlvAttnOlPrssrfrClndr13 3636;
BA_ "SPN" SG_ 2566751742 EngnIntkVlvAttnOlPrssrfrClndr14 3637;
BA_ "SPN" SG_ 2566751742 EngnIntkVlvAttnOlPrssrfrClndr15 3638;
BA_ "SPN" SG_ 2566751742 EngnIntkVlvAttnOlPrssrfrClndr16 3639;
BA_ "SPN" SG_ 2566751998 EngnIntkVlvAttnOlPrssrfrClndr10 3633;
BA_ "SPN" SG_ 2566751998 EngnIntkVlvAttnOlPrssrfrClndr11 3634;
BA_ "SPN" SG_ 2566751998 EngnIntkVlvAttnOlPrssrfrClndr12 3635;
BA_ "SPN" SG_ 2566751998 EngnIntkVlvAttnOlPrssrfrClndr9 3632;
BA_ "SPN" SG_ 2566752254 EngnIntkVlvAttnOlPrssrfrClndr5 3628;
BA_ "SPN" SG_ 2566752254 EngnIntkVlvAttnOlPrssrfrClndr6 3629;
BA_ "SPN" SG_ 2566752254 EngnIntkVlvAttnOlPrssrfrClndr7 3630;
BA_ "SPN" SG_ 2566752254 EngnIntkVlvAttnOlPrssrfrClndr8 3631;
BA_ "SPN" SG_ 2566752510 EngnIntkVlvAttnOlPrssrfrClndr1 3624;
BA_ "SPN" SG_ 2566752510 EngnIntkVlvAttnOlPrssrfrClndr2 3625;
BA_ "SPN" SG_ 2566752510 EngnIntkVlvAttnOlPrssrfrClndr3 3626;
BA_ "SPN" SG_ 2566752510 EngnIntkVlvAttnOlPrssrfrClndr4 3627;
BA_ "SPN" SG_ 2566752766 VehicleRoll 3623;
BA_ "SPN" SG_ 2566753278 Atttt2DsPttFtItPss 3611;
BA_ "SPN" SG_ 2566753278 Atttt2DsPttFtOttPss 3612;
BA_ "SPN" SG_ 2566753534 Atttt1DsPttFtItPss 3609;
BA_ "SPN" SG_ 2566753534 Atttt1DsPttFtOttPss 3610;
BA_ "SPN" SG_ 2566753790 UtilityTotalkVArHoursExport 3595;
BA_ "SPN" SG_ 2566753790 UtilityTotalkVArHoursImport 3596;
BA_ "SPN" SG_ 2566754046 GeneratorTotalkVArHoursExport 3593;
BA_ "SPN" SG_ 2566754046 GeneratorTotalkVArHoursImport 3594;
BA_ "SPN" SG_ 2566754302 GeneratorTotalPercentkVA 3591;
BA_ "SPN" SG_ 2566754302 GeneratorTotalPercentkVAr 3592;
BA_ "SPN" SG_ 2566754302 GeneratorTotalPercentkW 3590;
BA_ "SPN" SG_ 2566754814 AutomaticTransferSwitchStatus 3547;
BA_ "SPN" SG_ 2566754814 BusTieBreaker1 7841;
BA_ "SPN" SG_ 2566754814 BusTieBreaker2 7842;
BA_ "SPN" SG_ 2566754814 EngineLoadGroup 7843;
BA_ "SPN" SG_ 2566754814 EngineSpeedGovernorMode 7840;
BA_ "SPN" SG_ 2566754814 GeneratorCircuitBreakerStatus 3545;
BA_ "SPN" SG_ 2566754814 UtilityCircuitBreakerStatus 3546;
BA_ "SPN" SG_ 2566754814 PackageCircuitBreakerStatus 9792;
BA_ "SPN" SG_ 2566754814 SttnrInvrtrCrtBrkrStts 9793;
BA_ "SPN" SG_ 2566755582 EngnCrnksBrthrOlSprtrSpd 5444;
BA_ "SPN" SG_ 2566755582 EngnExhstGsRrltn1Vlv2Pstn 3822;
BA_ "SPN" SG_ 2566755582 EngnExhstGsRrltn1VlvPstn 27;
BA_ "SPN" SG_ 2566755582 EngnIntkMnfldCmmnddPrssr 5312;
BA_ "SPN" SG_ 2566755838 TransmissionOilLevel2HighLow 5914;
BA_ "SPN" SG_ 2566755838 TransmissionOilLevelSwitch 3533;
BA_ "SPN" SG_ 2566755838 TransmissionOilLifeRemaining 4177;
BA_ "SPN" SG_ 2566755838 TransmissionOilTemperature2 5913;
BA_ "SPN" SG_ 2566755838 TransmissionOverheatIndicator 5345;
BA_ "SPN" SG_ 2566755838 TrnsmssnOlFltrRstrtnSwth 3359;
BA_ "SPN" SG_ 2566755838 TrnsmssnOlLvl2CntdwnTmr 5915;
BA_ "SPN" SG_ 2566755838 TrnsmssnOlLvl2MsrmntStts 5916;
BA_ "SPN" SG_ 2566755838 TrnsmssnTrqCnvrtrOlOtltTmprtr 3823;
BA_ "SPN" SG_ 2566756094 EngineFuelReturnFlowRate 2774;
BA_ "SPN" SG_ 2566756094 EngineFuelSupplyFlowRate 2773;
BA_ "SPN" SG_ 2566756350 EngineFuelReturnTemperature 2776;
BA_ "SPN" SG_ 2566756350 EngineFuelSupplyTemperature 2775;
BA_ "SPN" SG_ 2566756606 Aftertreatment1TotalFuelUsed 3522;
BA_ "SPN" SG_ 2566756606 Aftrtrtmnt1TtlDsldTm 3524;
BA_ "SPN" SG_ 2566756606 Aftrtrtmnt1TtlNmrfAtvRgnrtns 3525;
BA_ "SPN" SG_ 2566756606 Aftrtrtmnt1TtlRgnrtnTm 3523;
BA_ "SPN" SG_ 2566756606 Atttt1DsPttFtAvDstBtwAtvRts 5827;
BA_ "SPN" SG_ 2566756606 Atttt1DsPttFtAvTBtwAtvRts 5454;
BA_ "SPN" SG_ 2566756606 Atttt1DsPttFtTtNAtvRtItRqsts 3727;
BA_ "SPN" SG_ 2566756606 Atttt1DsPttFtTtNAtvRtMRqsts 3728;
BA_ "SPN" SG_ 2566756606 Atttt1DsPttFtTtNPssvRts 3726;
BA_ "SPN" SG_ 2566756606 Atttt1DsPttFtTtPssvRtT 3725;
BA_ "SPN" SG_ 2566756862 Aftertreatment2TotalFuelUsed 3526;
BA_ "SPN" SG_ 2566756862 Aftrtrtmnt2TtlDsldTm 3528;
BA_ "SPN" SG_ 2566756862 Aftrtrtmnt2TtlNmrfAtvRgnrtns 3529;
BA_ "SPN" SG_ 2566756862 Aftrtrtmnt2TtlRgnrtnTm 3527;
BA_ "SPN" SG_ 2566756862 Atttt2DsPttFtAvDstBtwAtvRts 5828;
BA_ "SPN" SG_ 2566756862 Atttt2DsPttFtAvTBtwAtvRts 5455;
BA_ "SPN" SG_ 2566756862 Atttt2DsPttFtTtNAtvRtItRqsts 3731;
BA_ "SPN" SG_ 2566756862 Atttt2DsPttFtTtNAtvRtMRqsts 3732;
BA_ "SPN" SG_ 2566756862 Atttt2DsPttFtTtNPssvRts 3730;
BA_ "SPN" SG_ 2566756862 Atttt2DsPttFtTtPssvRtT 3729;
BA_ "SPN" SG_ 2566757374 Aftrtrtmnt1DslExhstFldCndtvt 3518;
BA_ "SPN" SG_ 2566757374 Aftrtrtmnt1DslExhstFldCnntrtn 3516;
BA_ "SPN" SG_ 2566757374 Aftrtrtmnt1DslExhstFldPrprt 3521;
BA_ "SPN" SG_ 2566757374 Aftrtrtmnt1DslExhstFldTmprtr2 3515;
BA_ "SPN" SG_ 2566757374 Atttt1DsExstFdPptsPFMI 3520;
BA_ "SPN" SG_ 2566757374 Atttt1DsExstFdTpt2PFMI 3519;
BA_ "SPN" SG_ 2566757374 DieselExhaustFluidSpeedofSound 7346;
BA_ "SPN" SG_ 2566757630 Sensorsupplyvoltage5 3513;
BA_ "SPN" SG_ 2566757630 Sensorsupplyvoltage6 3514;
BA_ "SPN" SG_ 2566757630 Sensorsupplyvoltage7 5125;
BA_ "SPN" SG_ 2566757630 Sensorsupplyvoltage8 5126;
BA_ "SPN" SG_ 2566757886 Sensorsupplyvoltage1 3509;
BA_ "SPN" SG_ 2566757886 Sensorsupplyvoltage2 3510;
BA_ "SPN" SG_ 2566757886 Sensorsupplyvoltage3 3511;
BA_ "SPN" SG_ 2566757886 Sensorsupplyvoltage4 3512;
BA_ "SPN" SG_ 2566758142 Aftertreatment2AirSystemRelay 3506;
BA_ "SPN" SG_ 2566758142 Aftertreatment2PurgeAirActuator 3504;
BA_ "SPN" SG_ 2566758142 Aftertreatment2PurgeAirPressure 3500;
BA_ "SPN" SG_ 2566758142 Aftrtrtmnt2ArEnlAttr 3503;
BA_ "SPN" SG_ 2566758142 Aftrtrtmnt2ArPrssrAttrPstn 3502;
BA_ "SPN" SG_ 2566758142 Aftrtrtmnt2ArPrssrCntrl 3501;
BA_ "SPN" SG_ 2566758142 Aftrtrtmnt2AtmztnArAttr 3505;
BA_ "SPN" SG_ 2566758142 Aftrtrtmnt2SpplArPrssr 3499;
BA_ "SPN" SG_ 2566758398 Aftertreatment1AirSystemRelay 3492;
BA_ "SPN" SG_ 2566758398 Aftertreatment1PurgeAirActuator 3490;
BA_ "SPN" SG_ 2566758398 Aftertreatment1PurgeAirPressure 3486;
BA_ "SPN" SG_ 2566758398 Aftrtrtmnt1ArEnlAttr 3489;
BA_ "SPN" SG_ 2566758398 Aftrtrtmnt1ArPrssrAttrPstn 3488;
BA_ "SPN" SG_ 2566758398 Aftrtrtmnt1ArPrssrCntrl 3487;
BA_ "SPN" SG_ 2566758398 Aftrtrtmnt1AtmztnArAttr 3491;
BA_ "SPN" SG_ 2566758398 Aftrtrtmnt1SpplArPrssr 3485;
BA_ "SPN" SG_ 2566758654 Aftertreatment2FuelPressure1 3494;
BA_ "SPN" SG_ 2566758654 Aftertreatment2FuelRate 3495;
BA_ "SPN" SG_ 2566758654 Aftertreatment2Ignition 3498;
BA_ "SPN" SG_ 2566758654 Aftrtrtmnt2FlDrnAttr 4098;
BA_ "SPN" SG_ 2566758654 Aftrtrtmnt2FlEnlAttr 3496;
BA_ "SPN" SG_ 2566758654 Aftrtrtmnt2FlInjtr1HtrCntrl 4302;
BA_ "SPN" SG_ 2566758654 Aftrtrtmnt2FlPrssr1Cntrl 3493;
BA_ "SPN" SG_ 2566758654 Aftrtrtmnt2RgnrtnStts 3497;
BA_ "SPN" SG_ 2566758910 Aftertreatment1FuelPressure1 3480;
BA_ "SPN" SG_ 2566758910 Aftertreatment1FuelRate 3481;
BA_ "SPN" SG_ 2566758910 Aftertreatment1Ignition 3484;
BA_ "SPN" SG_ 2566758910 Aftrtrtmnt1FlDrnAttr 4097;
BA_ "SPN" SG_ 2566758910 Aftrtrtmnt1FlEnlAttr 3482;
BA_ "SPN" SG_ 2566758910 Aftrtrtmnt1FlInjtr1HtrCntrl 4301;
BA_ "SPN" SG_ 2566758910 Aftrtrtmnt1FlPrssr1Cntrl 3479;
BA_ "SPN" SG_ 2566758910 Aftrtrtmnt1RgnrtnStts 3483;
BA_ "SPN" SG_ 2566759678 AtleastonePTOengaged 3948;
BA_ "SPN" SG_ 2566759678 EnableSwitchPTOEngineFlywheel 3939;
BA_ "SPN" SG_ 2566759678 EnggmntCnsntPTOEngnAssrDrv1 3943;
BA_ "SPN" SG_ 2566759678 EnggmntCnsntPTOEngnAssrDrv2 3946;
BA_ "SPN" SG_ 2566759678 EnggmntCnsntPTOEngnFlwhl 3940;
BA_ "SPN" SG_ 2566759678 EnggmntSttsPTOEngnAssrDrv1 3944;
BA_ "SPN" SG_ 2566759678 EnggmntSttsPTOEngnAssrDrv2 3947;
BA_ "SPN" SG_ 2566759678 EnggmntSttsPTOEngnFlwhl 3941;
BA_ "SPN" SG_ 2566759678 EnlSwthPTOEngnAssrDrv1 3942;
BA_ "SPN" SG_ 2566759678 EnlSwthPTOEngnAssrDrv2 3945;
BA_ "SPN" SG_ 2566759678 EnlSwthTrnsfrstptshftPTO 3455;
BA_ "SPN" SG_ 2566759678 EnlSwthTrnsmssntptshftPTO 3454;
BA_ "SPN" SG_ 2566759678 EnlSwthTrnsmssnnptshftPTO2 3453;
BA_ "SPN" SG_ 2566759678 EnlSwthTrnsmssnnptshftPTO1 3452;
BA_ "SPN" SG_ 2566759678 EnggmntCnsntTrnsfrstptshftPTO 3459;
BA_ "SPN" SG_ 2566759678 EnggmntCnsntTrnsmssntptshftPTO 3458;
BA_ "SPN" SG_ 2566759678 EnggmntCnsntTrnsmssnnptshftPTO2 3457;
BA_ "SPN" SG_ 2566759678 EnggmntCnsntTrnsmssnnptshftPTO1 3456;
BA_ "SPN" SG_ 2566759678 EnggmntSttsTrnsfrstptshftPTO 3463;
BA_ "SPN" SG_ 2566759678 EnggmntSttsTrnsmssntptshftPTO 3462;
BA_ "SPN" SG_ 2566759678 EnggmntSttsTrnsmssnnptshftPTO2 3461;
BA_ "SPN" SG_ 2566759678 EnggmntSttsTrnsmssnnptshftPTO1 3460;
BA_ "SPN" SG_ 2566759934 EnableStatusofDoor1 3414;
BA_ "SPN" SG_ 2566759934 EnableStatusofDoor10 3441;
BA_ "SPN" SG_ 2566759934 EnableStatusofDoor2 3417;
BA_ "SPN" SG_ 2566759934 EnableStatusofDoor3 3420;
BA_ "SPN" SG_ 2566759934 EnableStatusofDoor4 3423;
BA_ "SPN" SG_ 2566759934 EnableStatusofDoor5 3426;
BA_ "SPN" SG_ 2566759934 EnableStatusofDoor6 3429;
BA_ "SPN" SG_ 2566759934 EnableStatusofDoor7 3432;
BA_ "SPN" SG_ 2566759934 EnableStatusofDoor8 3435;
BA_ "SPN" SG_ 2566759934 EnableStatusofDoor9 3438;
BA_ "SPN" SG_ 2566759934 LockStatusofDoor1 3412;
BA_ "SPN" SG_ 2566759934 LockStatusofDoor10 3439;
BA_ "SPN" SG_ 2566759934 LockStatusofDoor2 3415;
BA_ "SPN" SG_ 2566759934 LockStatusofDoor3 3418;
BA_ "SPN" SG_ 2566759934 LockStatusofDoor4 3421;
BA_ "SPN" SG_ 2566759934 LockStatusofDoor5 3424;
BA_ "SPN" SG_ 2566759934 LockStatusofDoor6 3427;
BA_ "SPN" SG_ 2566759934 LockStatusofDoor7 3430;
BA_ "SPN" SG_ 2566759934 LockStatusofDoor8 3433;
BA_ "SPN" SG_ 2566759934 LockStatusofDoor9 3436;
BA_ "SPN" SG_ 2566759934 OpenStatusofDoor1 3413;
BA_ "SPN" SG_ 2566759934 OpenStatusofDoor10 3440;
BA_ "SPN" SG_ 2566759934 OpenStatusofDoor2 3416;
BA_ "SPN" SG_ 2566759934 OpenStatusofDoor3 3419;
BA_ "SPN" SG_ 2566759934 OpenStatusofDoor4 3422;
BA_ "SPN" SG_ 2566759934 OpenStatusofDoor5 3425;
BA_ "SPN" SG_ 2566759934 OpenStatusofDoor6 3428;
BA_ "SPN" SG_ 2566759934 OpenStatusofDoor7 3431;
BA_ "SPN" SG_ 2566759934 OpenStatusofDoor8 3434;
BA_ "SPN" SG_ 2566759934 OpenStatusofDoor9 3437;
BA_ "SPN" SG_ 2566760702 NetworkAntennaStatus2 3444;
BA_ "SPN" SG_ 2566760702 NetworkServiceStatus2 3443;
BA_ "SPN" SG_ 2566760702 NetworkSignalStrength2 3445;
BA_ "SPN" SG_ 2566760702 NetworkTransceiverStatus2 3442;
BA_ "SPN" SG_ 2566760702 WrlssCmmntnNtwrkTp2 3446;
BA_ "SPN" SG_ 2566760958 NetworkAntennaStatus1 3370;
BA_ "SPN" SG_ 2566760958 NetworkServiceStatus1 3369;
BA_ "SPN" SG_ 2566760958 NetworkSignalStrength1 3371;
BA_ "SPN" SG_ 2566760958 NetworkTransceiverStatus1 3368;
BA_ "SPN" SG_ 2566760958 WrlssCmmntnNtwrkTp1 3372;
BA_ "SPN" SG_ 2566761214 EngineAftercoolerCoolantLevel 3676;
BA_ "SPN" SG_ 2566761214 EngineCentrifugalOilFilterspeed 3343;
BA_ "SPN" SG_ 2566761214 EngnChrgArClr1IntkPrssr 3340;
BA_ "SPN" SG_ 2566761214 EngnChrgArClr2IntkPrssr 3341;
BA_ "SPN" SG_ 2566761214 EngnChrgArClrClntLvl 3668;
BA_ "SPN" SG_ 2566761214 EngnChrgArClrOtltPrssr 2631;
BA_ "SPN" SG_ 2566761214 EngnClntPmpDffrntlPrssr 3342;
BA_ "SPN" SG_ 2566761726 EngineIdleFuelFlowRateThreshold 2778;
BA_ "SPN" SG_ 2566761726 NmrfFlCnsmptnMntrngTrnsdrs 2777;
BA_ "SPN" SG_ 2566762238 FfthWhlLkCplSttsIndtr 3313;
BA_ "SPN" SG_ 2566762238 FfthWhlLkRdtCplIndtr 3312;
BA_ "SPN" SG_ 2566762238 FifthWheelErrorStatus 3307;
BA_ "SPN" SG_ 2566762238 FifthWheelSliderLockIndicator 3316;
BA_ "SPN" SG_ 2566762238 FifthWheelSliderPosition 3311;
BA_ "SPN" SG_ 2566762494 Aftrtrtmnt2ExhstTmprtr2 3283;
BA_ "SPN" SG_ 2566762494 Atttt2DsPttFtDtPss 3285;
BA_ "SPN" SG_ 2566762494 Atttt2DsPttFtDtPssPFMI 3287;
BA_ "SPN" SG_ 2566762494 Atttt2DsPttFtItdtTpt 3284;
BA_ "SPN" SG_ 2566762494 Atttt2DsPttFtItdtTptPFMI 3288;
BA_ "SPN" SG_ 2566762494 Atttt2ExstTpt2PFMI 3286;
BA_ "SPN" SG_ 2566762750 Aftrtrtmnt2ExhstTmprtr3 3279;
BA_ "SPN" SG_ 2566762750 Atttt2DsPttFtExstTptPFMI 3282;
BA_ "SPN" SG_ 2566762750 Atttt2DsPttFtOttTpt 3280;
BA_ "SPN" SG_ 2566762750 Atttt2ExstTpt3PFMI 3281;
BA_ "SPN" SG_ 2566763006 Aftrtrtmnt2ExhstTmprtr1 3275;
BA_ "SPN" SG_ 2566763006 Atttt2DsPttFtItTpt 3276;
BA_ "SPN" SG_ 2566763006 Atttt2DsPttFtItTptPFMI 3278;
BA_ "SPN" SG_ 2566763006 Atttt2ExstTpt1PFMI 3277;
BA_ "SPN" SG_ 2566763262 Aftrtrtmnt1ExhstTmprtr2 3249;
BA_ "SPN" SG_ 2566763262 Atttt1DsPttFtDtPss 3251;
BA_ "SPN" SG_ 2566763262 Atttt1DsPttFtDtPssPFMI 3253;
BA_ "SPN" SG_ 2566763262 Atttt1DsPttFtItdtTpt 3250;
BA_ "SPN" SG_ 2566763262 Atttt1DsPttFtItdtTptPFMI 3254;
BA_ "SPN" SG_ 2566763262 Atttt1ExstTpt2PFMI 3252;
BA_ "SPN" SG_ 2566763518 Aftrtrtmnt1ExhstTmprtr3 3245;
BA_ "SPN" SG_ 2566763518 Atttt1DsPttFtOttExstTptPFMI 3248;
BA_ "SPN" SG_ 2566763518 Atttt1DsPttFtOttTpt 3246;
BA_ "SPN" SG_ 2566763518 Atttt1ExstTpt3PFMI 3247;
BA_ "SPN" SG_ 2566763774 Aftrtrtmnt1ExhstTmprtr1 3241;
BA_ "SPN" SG_ 2566763774 Atttt1DsPttFtItTpt 3242;
BA_ "SPN" SG_ 2566763774 Atttt1DsPttFtItTptPFMI 3244;
BA_ "SPN" SG_ 2566763774 Atttt1ExstTpt1PFMI 3243;
BA_ "SPN" SG_ 2566765054 ReferenceTirePressure 3191;
BA_ "SPN" SG_ 2566765054 TireLocation 3190;
BA_ "SPN" SG_ 2566765310 FareboxAlarmIdentifier 3181;
BA_ "SPN" SG_ 2566765310 FareboxEmergencyStatus 3179;
BA_ "SPN" SG_ 2566765566 FareValidity 3165;
BA_ "SPN" SG_ 2566765566 InitialFareAgency 3167;
BA_ "SPN" SG_ 2566765566 PassCategory 3166;
BA_ "SPN" SG_ 2566765566 PassengerType 3171;
BA_ "SPN" SG_ 2566765566 PaymentDetails 3177;
BA_ "SPN" SG_ 2566765566 RouteNumber 3169;
BA_ "SPN" SG_ 2566765566 TransactionType 3170;
BA_ "SPN" SG_ 2566765566 TransferSold 3168;
BA_ "SPN" SG_ 2566765566 TransferType 3173;
BA_ "SPN" SG_ 2566765566 TypeofFare 3176;
BA_ "SPN" SG_ 2566765566 TypeofService 3172;
BA_ "SPN" SG_ 2566765822 AssignedBlock 3163;
BA_ "SPN" SG_ 2566765822 AssignedRoute 3160;
BA_ "SPN" SG_ 2566765822 AssignedRun 3162;
BA_ "SPN" SG_ 2566765822 Driversfareboxsecuritycode 3164;
BA_ "SPN" SG_ 2566765822 FareboxServiceStatus 3178;
BA_ "SPN" SG_ 2566765822 FarePresets 3175;
BA_ "SPN" SG_ 2566765822 PatternNumber 3161;
BA_ "SPN" SG_ 2566765822 TripDirection 3174;
BA_ "SPN" SG_ 2566765822 TripNumber 3159;
BA_ "SPN" SG_ 2566765822 TripStatus 3180;
BA_ "SPN" SG_ 2566766078 IntrstnPrmptnRqstRspns 3079;
BA_ "SPN" SG_ 2566766078 PriorityofResponseSentbyEmitter 3084;
BA_ "SPN" SG_ 2566766078 RangeCodeEnable 3081;
BA_ "SPN" SG_ 2566766078 StrobeActivationControlStatus 3082;
BA_ "SPN" SG_ 2566766078 TransitDoorEnable 3083;
BA_ "SPN" SG_ 2566766078 TransitRouteIDUsage 3080;
BA_ "SPN" SG_ 2566766078 VehicleID 3085;
BA_ "SPN" SG_ 2566766334 Agency 3078;
BA_ "SPN" SG_ 2566766334 NmrftsnthTrnstAssgndBlkIdntt 3073;
BA_ "SPN" SG_ 2566766334 NmrftsnthTrnstAssgndRnIdntt 3072;
BA_ "SPN" SG_ 2566766334 NmrftsnthTrnstAssgndRtIdntt 3071;
BA_ "SPN" SG_ 2566766590 NmrftsnthMlpstIdntftn 3070;
BA_ "SPN" SG_ 2566766846 PatronCount 3047;
BA_ "SPN" SG_ 2566766846 SilentAlarmStatus 3044;
BA_ "SPN" SG_ 2566766846 TransitRunStatus 3046;
BA_ "SPN" SG_ 2566766846 TypeofPassengerCount 3043;
BA_ "SPN" SG_ 2566766846 VehicleUseStatus 3045;
BA_ "SPN" SG_ 2566767102 EngnExhstGsRrltn1IntkPrssr 3358;
BA_ "SPN" SG_ 2566767102 EngnExhstGsRrltn1OtltPrssr 5019;
BA_ "SPN" SG_ 2566767102 EngnExhstVlvAttnSstmOlPrssr 4287;
BA_ "SPN" SG_ 2566767102 EngnIntkVlvAttnSstmOlPrssr 2948;
BA_ "SPN" SG_ 2566767102 EngnThrttlVlv1DffrntlPrssr 5631;
BA_ "SPN" SG_ 2566767358 EngineFuelIsolationControl 7394;
BA_ "SPN" SG_ 2566767358 EngineFuelMassFlowRate 5833;
BA_ "SPN" SG_ 2566767358 EngnExhstGsRrltn1Vlv1PstnErrr 5829;
BA_ "SPN" SG_ 2566767358 EngnExhstGsRrltn1Vlv2PstnErrr 5830;
BA_ "SPN" SG_ 2566767358 FuelType 5837;
BA_ "SPN" SG_ 2566767614 AcceleratorPedal1Channel2 2623;
BA_ "SPN" SG_ 2566767614 AcceleratorPedal1Channel3 2624;
BA_ "SPN" SG_ 2566767614 AcceleratorPedal2Channel2 2625;
BA_ "SPN" SG_ 2566767614 AcceleratorPedal2Channel3 2626;
BA_ "SPN" SG_ 2566767614 EngnExhstGsRstrtnVlvCntrl 8150;
BA_ "SPN" SG_ 2566767870 BrakeTemperatureWarning 3839;
BA_ "SPN" SG_ 2566767870 EmergencyBrakingActive 5847;
BA_ "SPN" SG_ 2566767870 FoundationBrakeUse 2919;
BA_ "SPN" SG_ 2566767870 Haltbrakemode 2913;
BA_ "SPN" SG_ 2566767870 Hillholdermode 2912;
BA_ "SPN" SG_ 2566767870 PrkngBrkAttrFllAtvtd 5275;
BA_ "SPN" SG_ 2566767870 RailroadMode 7942;
BA_ "SPN" SG_ 2566767870 XBRAccelerationLimit 2921;
BA_ "SPN" SG_ 2566767870 XBRActiveControlMode 2918;
BA_ "SPN" SG_ 2566767870 XBRSystemState 2917;
BA_ "SPN" SG_ 2566768126 ECUHardwareID 6714;
BA_ "SPN" SG_ 2566768126 ECULocation 2903;
BA_ "SPN" SG_ 2566768126 ECUManufacturerName 4304;
BA_ "SPN" SG_ 2566768126 ECUPartNumber 2901;
BA_ "SPN" SG_ 2566768126 ECUSerialNumber 2902;
BA_ "SPN" SG_ 2566768126 ECUType 2904;
BA_ "SPN" SG_ 2566768382 EngineColdStartFuelIgniterRelay 5549;
BA_ "SPN" SG_ 2566768382 EngineStartEnableDevice1 626;
BA_ "SPN" SG_ 2566768382 EngineStartEnableDevice2 1804;
BA_ "SPN" SG_ 2566768382 EngnCldStrtFlIgntrCmmnd 5548;
BA_ "SPN" SG_ 2566768382 EngnCldStrtFlIgntrRlFdk 5550;
BA_ "SPN" SG_ 2566768382 EngnStrtEnlDv1Cnfgrtn 2899;
BA_ "SPN" SG_ 2566768382 EngnStrtEnlDv2Cnfgrtn 2898;
BA_ "SPN" SG_ 2566768638 EngineAuxiliaryGovernorState 2896;
BA_ "SPN" SG_ 2566768638 EngineMultiUnitSyncState 2890;
BA_ "SPN" SG_ 2566768638 EngineOperatingModeSelection 8664;
BA_ "SPN" SG_ 2566768638 EngineTorqueCurveSelection 1568;
BA_ "SPN" SG_ 2566768638 EngnAltrntDrpAlrtr2SltStt 2893;
BA_ "SPN" SG_ 2566768638 EngnAltrntLwIdlSltStt 2891;
BA_ "SPN" SG_ 2566768638 EngnAltrntRtngSltStt 2888;
BA_ "SPN" SG_ 2566768638 EngnDrpAlrtr1SltStt 2889;
BA_ "SPN" SG_ 2566768638 EngnDrpAxlrInptSltStt 2895;
BA_ "SPN" SG_ 2566768638 EngnDrpRmtAlrtrSltStt 2894;
BA_ "SPN" SG_ 2566768894 EngnOprtrPrmrIntrmdtSpdSltStt 2892;
BA_ "SPN" SG_ 2566769406 EngnOprtrPrmrIntrmdtSpdSlt 2880;
BA_ "SPN" SG_ 2566769662 EngineAlternateLowIdleSwitch 2883;
BA_ "SPN" SG_ 2566769662 EngineAlternateRatingSelect 2882;
BA_ "SPN" SG_ 2566769662 EngineAuxiliaryGovernorSwitch 2884;
BA_ "SPN" SG_ 2566769662 EngineDroopAccelerator1Select 2881;
BA_ "SPN" SG_ 2566769662 EngineDroopAccelerator2Select 2879;
BA_ "SPN" SG_ 2566769662 EngineDroopAuxiliaryInputSelect 2885;
BA_ "SPN" SG_ 2566769662 EngineOperatingModeCommand 8608;
BA_ "SPN" SG_ 2566769662 EngineSynchronizationSwitch 1377;
BA_ "SPN" SG_ 2566769662 EngnDrpRmtAlrtrSlt 2886;
BA_ "SPN" SG_ 2566769662 EngnTrqCrvSltnCmmnd 6796;
BA_ "SPN" SG_ 2566770174 FrntNnprtrWprDlCntrl 2870;
BA_ "SPN" SG_ 2566770174 FrontNonoperatorWasherSwitch 2867;
BA_ "SPN" SG_ 2566770174 FrontNonoperatorWiperSwitch 2864;
BA_ "SPN" SG_ 2566770174 FrontOperatorWasherSwitch 2866;
BA_ "SPN" SG_ 2566770174 FrontOperatorWiperDelayControl 2869;
BA_ "SPN" SG_ 2566770174 FrontOperatorWiperSwitch 2863;
BA_ "SPN" SG_ 2566770174 RearWasherFunction 2868;
BA_ "SPN" SG_ 2566770174 RearWiperDelayControl 2871;
BA_ "SPN" SG_ 2566770174 RearWiperSwitch 2865;
BA_ "SPN" SG_ 2566770942 EngineIntakeManifold2Pressure 3562;
BA_ "SPN" SG_ 2566770942 EngnArFltr2DffrntlPrssr 2809;
BA_ "SPN" SG_ 2566770942 EngnArFltr3DffrntlPrssr 2810;
BA_ "SPN" SG_ 2566770942 EngnArFltr4DffrntlPrssr 2811;
BA_ "SPN" SG_ 2566770942 EngnIntkMnfld1AsltPrssr 3563;
BA_ "SPN" SG_ 2566770942 EngnIntkMnfld1AsltPrssrHghRsltn 4817;
BA_ "SPN" SG_ 2566770942 EngnIntkMnfld2AsltPrssr 5422;
BA_ "SPN" SG_ 2566771454 DataMemoryUsage 2802;
BA_ "SPN" SG_ 2566771454 KeepAliveBatteryConsumption 2803;
BA_ "SPN" SG_ 2566771710 EngnTrhrgr1CmprssrOtltTmprtr 2629;
BA_ "SPN" SG_ 2566771710 EngnTrhrgr2CmprssrOtltTmprtr 2799;
BA_ "SPN" SG_ 2566771710 EngnTrhrgr3CmprssrOtltTmprtr 2800;
BA_ "SPN" SG_ 2566771710 EngnTrhrgr4CmprssrOtltTmprtr 2801;
BA_ "SPN" SG_ 2566771966 FfthWhlRlsCntrlSrtLkt 3315;
BA_ "SPN" SG_ 2566771966 FifthWheelReleaseControl 3314;
BA_ "SPN" SG_ 2566771966 TransferCaseSelectorSwitch 2796;
BA_ "SPN" SG_ 2566771966 TransmissionOilLevelRequest 3809;
BA_ "SPN" SG_ 2566771966 VehicleTrailerStatus 7711;
BA_ "SPN" SG_ 2566771966 AftrtrtmntSCRDsngMdCmmnd 9175;
BA_ "SPN" SG_ 2566771966 MomentaryOperatorKeySwitch 9842;
BA_ "SPN" SG_ 2566771966 OperatorKeyDetected 10144;
BA_ "SPN" SG_ 2566771966 OperatorKeySwitchAccessoryPower 3996;
BA_ "SPN" SG_ 2566771966 OperatorKeySwitchIgnitionPower 10145;
BA_ "SPN" SG_ 2566771966 OperatorKeySwitchStart 10146;
BA_ "SPN" SG_ 2566771966 OprtrKSwthDldBttrOff 10147;
BA_ "SPN" SG_ 2566772222 EngineFuelControlMode 5323;
BA_ "SPN" SG_ 2566772222 EngnExhstGsRrltn1Vlv1Cntrl1 2791;
BA_ "SPN" SG_ 2566772222 EngnTrhrgr1ClltdTrnIntkTmprtr 2789;
BA_ "SPN" SG_ 2566772222 EngnTrhrgr1ClltdTrnOtltTmprtr 2790;
BA_ "SPN" SG_ 2566772222 EngnVrlGmtrTrhrgr1CntrlMd 5457;
BA_ "SPN" SG_ 2566772222 EngnVrlGmtrTrhrgrVGT1AttrPstn 2795;
BA_ "SPN" SG_ 2566772222 EVGtTVGTACtStVv 2792;
BA_ "SPN" SG_ 2566774014 EngineMarineOperatingModeStatus 7845;
BA_ "SPN" SG_ 2566774014 EngnThrttlSnhrnztnMdStts 2615;
BA_ "SPN" SG_ 2566774014 SlowVesselModeStatus 2617;
BA_ "SPN" SG_ 2566774014 TrollingModeStatus 2616;
BA_ "SPN" SG_ 2566775038 BrmtrAsltPrssrHghRsltn 5685;
BA_ "SPN" SG_ 2566775038 CalculatedAmbientAirTemperature 5581;
BA_ "SPN" SG_ 2566775038 SolarIntensityPercent 2610;
BA_ "SPN" SG_ 2566775038 SolarSensorMaximum 2611;
BA_ "SPN" SG_ 2566775038 SpecificHumidity 4490;
BA_ "SPN" SG_ 2566775294 AirConditionerCompressorStatus 7853;
BA_ "SPN" SG_ 2566775294 CACRfrgrntCmprssrOtltPrssr 2609;
BA_ "SPN" SG_ 2566775550 ArSspnsnSpplPrssrRqst 2608;
BA_ "SPN" SG_ 2566775550 AxlrEqpmntSpplPrssrRqst 2607;
BA_ "SPN" SG_ 2566775550 PneumaticSupplyPressureRequest 2603;
BA_ "SPN" SG_ 2566775550 PrkngndrTrlrArPrssrRqst 2604;
BA_ "SPN" SG_ 2566775550 PwrtrnCrtArSpplPrssrRqst 6306;
BA_ "SPN" SG_ 2566775550 SrvBrkArPrssrRqstCrt1 2605;
BA_ "SPN" SG_ 2566775550 SrvBrkArPrssrRqstCrt2 2606;
BA_ "SPN" SG_ 2566775806 TravelVelocityControlPosition 2601;
BA_ "SPN" SG_ 2566776062 PayloadCapacityPercentage 6854;
BA_ "SPN" SG_ 2566776062 PayloadCarryBackWeight 6853;
BA_ "SPN" SG_ 2566776062 PayloadPercentage 2600;
BA_ "SPN" SG_ 2566776062 PayloadWeight 6851;
BA_ "SPN" SG_ 2566776062 PayloadWeightConfidence 6852;
BA_ "SPN" SG_ 2566776318 AppliedVehicleSpeedLimit 2595;
BA_ "SPN" SG_ 2566776318 MaximumVehicleSpeedLimit1 2588;
BA_ "SPN" SG_ 2566776318 MaximumVehicleSpeedLimit2 2589;
BA_ "SPN" SG_ 2566776318 MaximumVehicleSpeedLimit3 2590;
BA_ "SPN" SG_ 2566776318 MaximumVehicleSpeedLimit4 2591;
BA_ "SPN" SG_ 2566776318 MaximumVehicleSpeedLimit5 2592;
BA_ "SPN" SG_ 2566776318 MaximumVehicleSpeedLimit6 2593;
BA_ "SPN" SG_ 2566776318 MaximumVehicleSpeedLimit7 2594;
